VERSION ""

NS_ :

BS_:
BU_: RLR_L RRR_L mADC

BO_ 924 RRR_L_39C: 64 RRR_L
 SG_ RLR_CRCCheck_39C : 503|16@0+ (1.0000000000,0.0000000000) [0.0000000000|65535.0000000000] ""  RLR_L,mADC
 SG_ RLR_RollingCounter_39C : 491|4@0+ (1.0000000000,0.0000000000) [0.0000000000|15.0000000000] ""  RLR_L,mADC
 SG_ RLR_FreespaceSectorKinestate102 : 477|2@0+ (1.0000000000,0.0000000000) [0.0000000000|3.0000000000] "-"  RLR_L,mADC
 SG_ RLR_FreespaceSectorConRidence102 : 479|2@0+ (1.0000000000,0.0000000000) [0.0000000000|3.0000000000] "-"  RLR_L,mADC
 SG_ RLR_FreespaceSectorDistance102 : 457|10@0+ (0.1000000000,0.0000000000) [0.0000000000|100.0000000000] "-"  RLR_L,mADC
 SG_ RLR_FreespaceSectorKinestate101 : 459|2@0+ (1.0000000000,0.0000000000) [0.0000000000|3.0000000000] "-"  RLR_L,mADC
 SG_ RLR_FreespaceSectorConRidence101 : 461|2@0+ (1.0000000000,0.0000000000) [0.0000000000|3.0000000000] "-"  RLR_L,mADC
 SG_ RLR_FreespaceSectorDistance101 : 455|10@0+ (0.1000000000,0.0000000000) [0.0000000000|100.0000000000] "-"  RLR_L,mADC
 SG_ RLR_FreespaceSectorKinestate100 : 441|2@0+ (1.0000000000,0.0000000000) [0.0000000000|3.0000000000] "-"  RLR_L,mADC
 SG_ RLR_FreespaceSectorConRidence100 : 443|2@0+ (1.0000000000,0.0000000000) [0.0000000000|3.0000000000] "-"  RLR_L,mADC
 SG_ RLR_FreespaceSectorDistance100 : 437|10@0+ (0.1000000000,0.0000000000) [0.0000000000|100.0000000000] "-"  RLR_L,mADC
 SG_ RLR_FreespaceSectorKinestate99 : 439|2@0+ (1.0000000000,0.0000000000) [0.0000000000|3.0000000000] "-"  RLR_L,mADC
 SG_ RLR_FreespaceSectorConRidence99 : 425|2@0+ (1.0000000000,0.0000000000) [0.0000000000|3.0000000000] "-"  RLR_L,mADC
 SG_ RLR_FreespaceSectorDistance99 : 419|10@0+ (0.1000000000,0.0000000000) [0.0000000000|100.0000000000] "-"  RLR_L,mADC
 SG_ RLR_FreespaceSectorKinestate98 : 421|2@0+ (1.0000000000,0.0000000000) [0.0000000000|3.0000000000] "-"  RLR_L,mADC
 SG_ RLR_FreespaceSectorConRidence98 : 423|2@0+ (1.0000000000,0.0000000000) [0.0000000000|3.0000000000] "-"  RLR_L,mADC
 SG_ RLR_FreespaceSectorDistance98 : 401|10@0+ (0.1000000000,0.0000000000) [0.0000000000|100.0000000000] "-"  RLR_L,mADC
 SG_ RLR_FreespaceSectorKinestate97 : 403|2@0+ (1.0000000000,0.0000000000) [0.0000000000|3.0000000000] "-"  RLR_L,mADC
 SG_ RLR_FreespaceSectorConRidence97 : 405|2@0+ (1.0000000000,0.0000000000) [0.0000000000|3.0000000000] "-"  RLR_L,mADC
 SG_ RLR_FreespaceSectorDistance97 : 399|10@0+ (0.1000000000,0.0000000000) [0.0000000000|100.0000000000] "-"  RLR_L,mADC
 SG_ RLR_FreespaceSectorKinestate96 : 385|2@0+ (1.0000000000,0.0000000000) [0.0000000000|3.0000000000] "-"  RLR_L,mADC
 SG_ RLR_FreespaceSectorConRidence96 : 387|2@0+ (1.0000000000,0.0000000000) [0.0000000000|3.0000000000] "-"  RLR_L,mADC
 SG_ RLR_FreespaceSectorDistance96 : 381|10@0+ (0.1000000000,0.0000000000) [0.0000000000|100.0000000000] "-"  RLR_L,mADC
 SG_ RLR_FreespaceSectorKinestate95 : 383|2@0+ (1.0000000000,0.0000000000) [0.0000000000|3.0000000000] "-"  RLR_L,mADC
 SG_ RLR_FreespaceSectorConRidence95 : 369|2@0+ (1.0000000000,0.0000000000) [0.0000000000|3.0000000000] "-"  RLR_L,mADC
 SG_ RLR_FreespaceSectorDistance95 : 363|10@0+ (0.1000000000,0.0000000000) [0.0000000000|100.0000000000] "-"  RLR_L,mADC
 SG_ RLR_FreespaceSectorKinestate94 : 365|2@0+ (1.0000000000,0.0000000000) [0.0000000000|3.0000000000] "-"  RLR_L,mADC
 SG_ RLR_FreespaceSectorConRidence94 : 367|2@0+ (1.0000000000,0.0000000000) [0.0000000000|3.0000000000] "-"  RLR_L,mADC
 SG_ RLR_FreespaceSectorDistance94 : 345|10@0+ (0.1000000000,0.0000000000) [0.0000000000|100.0000000000] "-"  RLR_L,mADC
 SG_ RLR_FreespaceSectorKinestate93 : 347|2@0+ (1.0000000000,0.0000000000) [0.0000000000|3.0000000000] "-"  RLR_L,mADC
 SG_ RLR_FreespaceSectorConRidence93 : 349|2@0+ (1.0000000000,0.0000000000) [0.0000000000|3.0000000000] "-"  RLR_L,mADC
 SG_ RLR_FreespaceSectorDistance93 : 343|10@0+ (0.1000000000,0.0000000000) [0.0000000000|100.0000000000] "-"  RLR_L,mADC
 SG_ RLR_FreespaceSectorKinestate92 : 329|2@0+ (1.0000000000,0.0000000000) [0.0000000000|3.0000000000] "-"  RLR_L,mADC
 SG_ RLR_FreespaceSectorConRidence92 : 331|2@0+ (1.0000000000,0.0000000000) [0.0000000000|3.0000000000] "-"  RLR_L,mADC
 SG_ RLR_FreespaceSectorDistance92 : 325|10@0+ (0.1000000000,0.0000000000) [0.0000000000|100.0000000000] "-"  RLR_L,mADC
 SG_ RLR_FreespaceSectorKinestate91 : 327|2@0+ (1.0000000000,0.0000000000) [0.0000000000|3.0000000000] "-"  RLR_L,mADC
 SG_ RLR_FreespaceSectorConRidence91 : 313|2@0+ (1.0000000000,0.0000000000) [0.0000000000|3.0000000000] "-"  RLR_L,mADC
 SG_ RLR_FreespaceSectorDistance91 : 307|10@0+ (0.1000000000,0.0000000000) [0.0000000000|100.0000000000] "-"  RLR_L,mADC
 SG_ RLR_FreespaceSectorKinestate90 : 309|2@0+ (1.0000000000,0.0000000000) [0.0000000000|3.0000000000] "-"  RLR_L,mADC
 SG_ RLR_FreespaceSectorConRidence90 : 311|2@0+ (1.0000000000,0.0000000000) [0.0000000000|3.0000000000] "-"  RLR_L,mADC
 SG_ RLR_FreespaceSectorDistance90 : 289|10@0+ (0.1000000000,0.0000000000) [0.0000000000|100.0000000000] "-"  RLR_L,mADC
 SG_ RLR_FreespaceSectorKinestate89 : 291|2@0+ (1.0000000000,0.0000000000) [0.0000000000|3.0000000000] "-"  RLR_L,mADC
 SG_ RLR_FreespaceSectorConRidence89 : 293|2@0+ (1.0000000000,0.0000000000) [0.0000000000|3.0000000000] "-"  RLR_L,mADC
 SG_ RLR_FreespaceSectorDistance89 : 287|10@0+ (0.1000000000,0.0000000000) [0.0000000000|100.0000000000] "-"  RLR_L,mADC
 SG_ RLR_FreespaceSectorKinestate88 : 273|2@0+ (1.0000000000,0.0000000000) [0.0000000000|3.0000000000] "-"  RLR_L,mADC
 SG_ RLR_FreespaceSectorConRidence88 : 275|2@0+ (1.0000000000,0.0000000000) [0.0000000000|3.0000000000] "-"  RLR_L,mADC
 SG_ RLR_FreespaceSectorDistance88 : 269|10@0+ (0.1000000000,0.0000000000) [0.0000000000|100.0000000000] "-"  RLR_L,mADC
 SG_ RLR_FreespaceSectorKinestate87 : 271|2@0+ (1.0000000000,0.0000000000) [0.0000000000|3.0000000000] "-"  RLR_L,mADC
 SG_ RLR_FreespaceSectorConRidence87 : 257|2@0+ (1.0000000000,0.0000000000) [0.0000000000|3.0000000000] "-"  RLR_L,mADC
 SG_ RLR_FreespaceSectorDistance87 : 251|10@0+ (0.1000000000,0.0000000000) [0.0000000000|100.0000000000] "-"  RLR_L,mADC
 SG_ RLR_FreespaceSectorKinestate86 : 253|2@0+ (1.0000000000,0.0000000000) [0.0000000000|3.0000000000] "-"  RLR_L,mADC
 SG_ RLR_FreespaceSectorConRidence86 : 255|2@0+ (1.0000000000,0.0000000000) [0.0000000000|3.0000000000] "-"  RLR_L,mADC
 SG_ RLR_FreespaceSectorDistance86 : 233|10@0+ (0.1000000000,0.0000000000) [0.0000000000|100.0000000000] "-"  RLR_L,mADC
 SG_ RLR_FreespaceSectorKinestate85 : 235|2@0+ (1.0000000000,0.0000000000) [0.0000000000|3.0000000000] "-"  RLR_L,mADC
 SG_ RLR_FreespaceSectorConRidence85 : 237|2@0+ (1.0000000000,0.0000000000) [0.0000000000|3.0000000000] "-"  RLR_L,mADC
 SG_ RLR_FreespaceSectorDistance85 : 231|10@0+ (0.1000000000,0.0000000000) [0.0000000000|100.0000000000] "-"  RLR_L,mADC
 SG_ RLR_FreespaceSectorKinestate84 : 217|2@0+ (1.0000000000,0.0000000000) [0.0000000000|3.0000000000] "-"  RLR_L,mADC
 SG_ RLR_FreespaceSectorConRidence84 : 219|2@0+ (1.0000000000,0.0000000000) [0.0000000000|3.0000000000] "-"  RLR_L,mADC
 SG_ RLR_FreespaceSectorDistance84 : 213|10@0+ (0.1000000000,0.0000000000) [0.0000000000|100.0000000000] "-"  RLR_L,mADC
 SG_ RLR_FreespaceSectorKinestate83 : 215|2@0+ (1.0000000000,0.0000000000) [0.0000000000|3.0000000000] "-"  RLR_L,mADC
 SG_ RLR_FreespaceSectorConRidence83 : 201|2@0+ (1.0000000000,0.0000000000) [0.0000000000|3.0000000000] "-"  RLR_L,mADC
 SG_ RLR_FreespaceSectorDistance83 : 195|10@0+ (0.1000000000,0.0000000000) [0.0000000000|100.0000000000] "-"  RLR_L,mADC
 SG_ RLR_FreespaceSectorKinestate82 : 197|2@0+ (1.0000000000,0.0000000000) [0.0000000000|3.0000000000] "-"  RLR_L,mADC
 SG_ RLR_FreespaceSectorConRidence82 : 199|2@0+ (1.0000000000,0.0000000000) [0.0000000000|3.0000000000] "-"  RLR_L,mADC
 SG_ RLR_FreespaceSectorDistance82 : 177|10@0+ (0.1000000000,0.0000000000) [0.0000000000|100.0000000000] "-"  RLR_L,mADC
 SG_ RLR_FreespaceSectorKinestate81 : 179|2@0+ (1.0000000000,0.0000000000) [0.0000000000|3.0000000000] "-"  RLR_L,mADC
 SG_ RLR_FreespaceSectorConRidence81 : 181|2@0+ (1.0000000000,0.0000000000) [0.0000000000|3.0000000000] "-"  RLR_L,mADC
 SG_ RLR_FreespaceSectorDistance81 : 175|10@0+ (0.1000000000,0.0000000000) [0.0000000000|100.0000000000] "-"  RLR_L,mADC
 SG_ RLR_FreespaceSectorKinestate80 : 161|2@0+ (1.0000000000,0.0000000000) [0.0000000000|3.0000000000] "-"  RLR_L,mADC
 SG_ RLR_FreespaceSectorConRidence80 : 163|2@0+ (1.0000000000,0.0000000000) [0.0000000000|3.0000000000] "-"  RLR_L,mADC
 SG_ RLR_FreespaceSectorDistance80 : 157|10@0+ (0.1000000000,0.0000000000) [0.0000000000|100.0000000000] "-"  RLR_L,mADC
 SG_ RLR_FreespaceSectorKinestate79 : 159|2@0+ (1.0000000000,0.0000000000) [0.0000000000|3.0000000000] "-"  RLR_L,mADC
 SG_ RLR_FreespaceSectorConRidence79 : 145|2@0+ (1.0000000000,0.0000000000) [0.0000000000|3.0000000000] "-"  RLR_L,mADC
 SG_ RLR_FreespaceSectorDistance79 : 139|10@0+ (0.1000000000,0.0000000000) [0.0000000000|100.0000000000] "-"  RLR_L,mADC
 SG_ RLR_FreespaceSectorKinestate78 : 141|2@0+ (1.0000000000,0.0000000000) [0.0000000000|3.0000000000] "-"  RLR_L,mADC
 SG_ RLR_FreespaceSectorConRidence78 : 143|2@0+ (1.0000000000,0.0000000000) [0.0000000000|3.0000000000] "-"  RLR_L,mADC
 SG_ RLR_FreespaceSectorDistance78 : 121|10@0+ (0.1000000000,0.0000000000) [0.0000000000|100.0000000000] "-"  RLR_L,mADC
 SG_ RLR_FreespaceSectorKinestate77 : 123|2@0+ (1.0000000000,0.0000000000) [0.0000000000|3.0000000000] "-"  RLR_L,mADC
 SG_ RLR_FreespaceSectorConRidence77 : 125|2@0+ (1.0000000000,0.0000000000) [0.0000000000|3.0000000000] "-"  RLR_L,mADC
 SG_ RLR_FreespaceSectorDistance77 : 119|10@0+ (0.1000000000,0.0000000000) [0.0000000000|100.0000000000] "-"  RLR_L,mADC
 SG_ RLR_FreespaceSectorKinestate76 : 105|2@0+ (1.0000000000,0.0000000000) [0.0000000000|3.0000000000] "-"  RLR_L,mADC
 SG_ RLR_FreespaceSectorConRidence76 : 107|2@0+ (1.0000000000,0.0000000000) [0.0000000000|3.0000000000] "-"  RLR_L,mADC
 SG_ RLR_FreespaceSectorDistance76 : 101|10@0+ (0.1000000000,0.0000000000) [0.0000000000|100.0000000000] "-"  RLR_L,mADC
 SG_ RLR_FreespaceSectorKinestate75 : 103|2@0+ (1.0000000000,0.0000000000) [0.0000000000|3.0000000000] "-"  RLR_L,mADC
 SG_ RLR_FreespaceSectorConRidence75 : 89|2@0+ (1.0000000000,0.0000000000) [0.0000000000|3.0000000000] "-"  RLR_L,mADC
 SG_ RLR_FreespaceSectorDistance75 : 83|10@0+ (0.1000000000,0.0000000000) [0.0000000000|100.0000000000] "-"  RLR_L,mADC
 SG_ RLR_FreespaceSectorKinestate74 : 85|2@0+ (1.0000000000,0.0000000000) [0.0000000000|3.0000000000] "-"  RLR_L,mADC
 SG_ RLR_FreespaceSectorConRidence74 : 87|2@0+ (1.0000000000,0.0000000000) [0.0000000000|3.0000000000] "-"  RLR_L,mADC
 SG_ RLR_FreespaceSectorDistance74 : 65|10@0+ (0.1000000000,0.0000000000) [0.0000000000|100.0000000000] "-"  RLR_L,mADC
 SG_ RLR_FreespaceSectorKinestate73 : 67|2@0+ (1.0000000000,0.0000000000) [0.0000000000|3.0000000000] "-"  RLR_L,mADC
 SG_ RLR_FreespaceSectorConRidence73 : 69|2@0+ (1.0000000000,0.0000000000) [0.0000000000|3.0000000000] "-"  RLR_L,mADC
 SG_ RLR_FreespaceSectorDistance73 : 63|10@0+ (0.1000000000,0.0000000000) [0.0000000000|100.0000000000] "-"  RLR_L,mADC
 SG_ RLR_FreespaceSectorKinestate72 : 49|2@0+ (1.0000000000,0.0000000000) [0.0000000000|3.0000000000] "-"  RLR_L,mADC
 SG_ RLR_FreespaceSectorConRidence72 : 51|2@0+ (1.0000000000,0.0000000000) [0.0000000000|3.0000000000] "-"  RLR_L,mADC
 SG_ RLR_FreespaceSectorDistance72 : 45|10@0+ (0.1000000000,0.0000000000) [0.0000000000|100.0000000000] "-"  RLR_L,mADC
 SG_ RLR_FreespaceSectorKinestate71 : 47|2@0+ (1.0000000000,0.0000000000) [0.0000000000|3.0000000000] "-"  RLR_L,mADC
 SG_ RLR_FreespaceSectorConRidence71 : 33|2@0+ (1.0000000000,0.0000000000) [0.0000000000|3.0000000000] "-"  RLR_L,mADC
 SG_ RLR_FreespaceSectorDistance71 : 27|10@0+ (0.1000000000,0.0000000000) [0.0000000000|100.0000000000] "-"  RLR_L,mADC
 SG_ RLR_FreespaceSectorKinestate70 : 29|2@0+ (1.0000000000,0.0000000000) [0.0000000000|3.0000000000] "-"  RLR_L,mADC
 SG_ RLR_FreespaceSectorConRidence70 : 31|2@0+ (1.0000000000,0.0000000000) [0.0000000000|3.0000000000] "-"  RLR_L,mADC
 SG_ RLR_FreespaceSectorDistance70 : 9|10@0+ (0.1000000000,0.0000000000) [0.0000000000|100.0000000000] "-"  RLR_L,mADC
 SG_ RLR_FreespaceSectorKinestate69 : 11|2@0+ (1.0000000000,0.0000000000) [0.0000000000|3.0000000000] "-"  RLR_L,mADC
 SG_ RLR_FreespaceSectorConRidence69 : 13|2@0+ (1.0000000000,0.0000000000) [0.0000000000|3.0000000000] "-"  RLR_L,mADC
 SG_ RLR_FreespaceSectorDistance69 : 7|10@0+ (0.1000000000,0.0000000000) [0.0000000000|100.0000000000] "-"  RLR_L,mADC

BO_ 925 RRR_L_39D: 64 RRR_L
 SG_ RLR_CRCCheck_39D : 503|16@0+ (1.0000000000,0.0000000000) [0.0000000000|65535.0000000000] ""  RLR_L,mADC
 SG_ RLR_RollingCounter_39D : 491|4@0+ (1.0000000000,0.0000000000) [0.0000000000|15.0000000000] ""  RLR_L,mADC
 SG_ RLR_FreespaceSectorKinestate136 : 477|2@0+ (1.0000000000,0.0000000000) [0.0000000000|3.0000000000] "-"  RLR_L,mADC
 SG_ RLR_FreespaceSectorConRidence136 : 479|2@0+ (1.0000000000,0.0000000000) [0.0000000000|3.0000000000] "-"  RLR_L,mADC
 SG_ RLR_FreespaceSectorDistance136 : 457|10@0+ (0.1000000000,0.0000000000) [0.0000000000|100.0000000000] "-"  RLR_L,mADC
 SG_ RLR_FreespaceSectorKinestate135 : 459|2@0+ (1.0000000000,0.0000000000) [0.0000000000|3.0000000000] "-"  RLR_L,mADC
 SG_ RLR_FreespaceSectorConRidence135 : 461|2@0+ (1.0000000000,0.0000000000) [0.0000000000|3.0000000000] "-"  RLR_L,mADC
 SG_ RLR_FreespaceSectorDistance135 : 455|10@0+ (0.1000000000,0.0000000000) [0.0000000000|100.0000000000] "-"  RLR_L,mADC
 SG_ RLR_FreespaceSectorKinestate134 : 441|2@0+ (1.0000000000,0.0000000000) [0.0000000000|3.0000000000] "-"  RLR_L,mADC
 SG_ RLR_FreespaceSectorConRidence134 : 443|2@0+ (1.0000000000,0.0000000000) [0.0000000000|3.0000000000] "-"  RLR_L,mADC
 SG_ RLR_FreespaceSectorDistance134 : 437|10@0+ (0.1000000000,0.0000000000) [0.0000000000|100.0000000000] "-"  RLR_L,mADC
 SG_ RLR_FreespaceSectorKinestate133 : 439|2@0+ (1.0000000000,0.0000000000) [0.0000000000|3.0000000000] "-"  RLR_L,mADC
 SG_ RLR_FreespaceSectorConRidence133 : 425|2@0+ (1.0000000000,0.0000000000) [0.0000000000|3.0000000000] "-"  RLR_L,mADC
 SG_ RLR_FreespaceSectorDistance133 : 419|10@0+ (0.1000000000,0.0000000000) [0.0000000000|100.0000000000] "-"  RLR_L,mADC
 SG_ RLR_FreespaceSectorKinestate132 : 421|2@0+ (1.0000000000,0.0000000000) [0.0000000000|3.0000000000] "-"  RLR_L,mADC
 SG_ RLR_FreespaceSectorConRidence132 : 423|2@0+ (1.0000000000,0.0000000000) [0.0000000000|3.0000000000] "-"  RLR_L,mADC
 SG_ RLR_FreespaceSectorDistance132 : 401|10@0+ (0.1000000000,0.0000000000) [0.0000000000|100.0000000000] "-"  RLR_L,mADC
 SG_ RLR_FreespaceSectorKinestate131 : 403|2@0+ (1.0000000000,0.0000000000) [0.0000000000|3.0000000000] "-"  RLR_L,mADC
 SG_ RLR_FreespaceSectorConRidence131 : 405|2@0+ (1.0000000000,0.0000000000) [0.0000000000|3.0000000000] "-"  RLR_L,mADC
 SG_ RLR_FreespaceSectorDistance131 : 399|10@0+ (0.1000000000,0.0000000000) [0.0000000000|100.0000000000] "-"  RLR_L,mADC
 SG_ RLR_FreespaceSectorKinestate130 : 385|2@0+ (1.0000000000,0.0000000000) [0.0000000000|3.0000000000] "-"  RLR_L,mADC
 SG_ RLR_FreespaceSectorConRidence130 : 387|2@0+ (1.0000000000,0.0000000000) [0.0000000000|3.0000000000] "-"  RLR_L,mADC
 SG_ RLR_FreespaceSectorDistance130 : 381|10@0+ (0.1000000000,0.0000000000) [0.0000000000|100.0000000000] "-"  RLR_L,mADC
 SG_ RLR_FreespaceSectorKinestate129 : 383|2@0+ (1.0000000000,0.0000000000) [0.0000000000|3.0000000000] "-"  RLR_L,mADC
 SG_ RLR_FreespaceSectorConRidence129 : 369|2@0+ (1.0000000000,0.0000000000) [0.0000000000|3.0000000000] "-"  RLR_L,mADC
 SG_ RLR_FreespaceSectorDistance129 : 363|10@0+ (0.1000000000,0.0000000000) [0.0000000000|100.0000000000] "-"  RLR_L,mADC
 SG_ RLR_FreespaceSectorKinestate128 : 365|2@0+ (1.0000000000,0.0000000000) [0.0000000000|3.0000000000] "-"  RLR_L,mADC
 SG_ RLR_FreespaceSectorConRidence128 : 367|2@0+ (1.0000000000,0.0000000000) [0.0000000000|3.0000000000] "-"  RLR_L,mADC
 SG_ RLR_FreespaceSectorDistance128 : 345|10@0+ (0.1000000000,0.0000000000) [0.0000000000|100.0000000000] "-"  RLR_L,mADC
 SG_ RLR_FreespaceSectorKinestate127 : 347|2@0+ (1.0000000000,0.0000000000) [0.0000000000|3.0000000000] "-"  RLR_L,mADC
 SG_ RLR_FreespaceSectorConRidence127 : 349|2@0+ (1.0000000000,0.0000000000) [0.0000000000|3.0000000000] "-"  RLR_L,mADC
 SG_ RLR_FreespaceSectorDistance127 : 343|10@0+ (0.1000000000,0.0000000000) [0.0000000000|100.0000000000] "-"  RLR_L,mADC
 SG_ RLR_FreespaceSectorKinestate126 : 329|2@0+ (1.0000000000,0.0000000000) [0.0000000000|3.0000000000] "-"  RLR_L,mADC
 SG_ RLR_FreespaceSectorConRidence126 : 331|2@0+ (1.0000000000,0.0000000000) [0.0000000000|3.0000000000] "-"  RLR_L,mADC
 SG_ RLR_FreespaceSectorDistance126 : 325|10@0+ (0.1000000000,0.0000000000) [0.0000000000|100.0000000000] "-"  RLR_L,mADC
 SG_ RLR_FreespaceSectorKinestate125 : 327|2@0+ (1.0000000000,0.0000000000) [0.0000000000|3.0000000000] "-"  RLR_L,mADC
 SG_ RLR_FreespaceSectorConRidence125 : 313|2@0+ (1.0000000000,0.0000000000) [0.0000000000|3.0000000000] "-"  RLR_L,mADC
 SG_ RLR_FreespaceSectorDistance125 : 307|10@0+ (0.1000000000,0.0000000000) [0.0000000000|100.0000000000] "-"  RLR_L,mADC
 SG_ RLR_FreespaceSectorKinestate124 : 309|2@0+ (1.0000000000,0.0000000000) [0.0000000000|3.0000000000] "-"  RLR_L,mADC
 SG_ RLR_FreespaceSectorConRidence124 : 311|2@0+ (1.0000000000,0.0000000000) [0.0000000000|3.0000000000] "-"  RLR_L,mADC
 SG_ RLR_FreespaceSectorDistance124 : 289|10@0+ (0.1000000000,0.0000000000) [0.0000000000|100.0000000000] "-"  RLR_L,mADC
 SG_ RLR_FreespaceSectorKinestate123 : 291|2@0+ (1.0000000000,0.0000000000) [0.0000000000|3.0000000000] "-"  RLR_L,mADC
 SG_ RLR_FreespaceSectorConRidence123 : 293|2@0+ (1.0000000000,0.0000000000) [0.0000000000|3.0000000000] "-"  RLR_L,mADC
 SG_ RLR_FreespaceSectorDistance123 : 287|10@0+ (0.1000000000,0.0000000000) [0.0000000000|100.0000000000] "-"  RLR_L,mADC
 SG_ RLR_FreespaceSectorKinestate122 : 273|2@0+ (1.0000000000,0.0000000000) [0.0000000000|3.0000000000] "-"  RLR_L,mADC
 SG_ RLR_FreespaceSectorConRidence122 : 275|2@0+ (1.0000000000,0.0000000000) [0.0000000000|3.0000000000] "-"  RLR_L,mADC
 SG_ RLR_FreespaceSectorDistance122 : 269|10@0+ (0.1000000000,0.0000000000) [0.0000000000|100.0000000000] "-"  RLR_L,mADC
 SG_ RLR_FreespaceSectorKinestate121 : 271|2@0+ (1.0000000000,0.0000000000) [0.0000000000|3.0000000000] "-"  RLR_L,mADC
 SG_ RLR_FreespaceSectorConRidence121 : 257|2@0+ (1.0000000000,0.0000000000) [0.0000000000|3.0000000000] "-"  RLR_L,mADC
 SG_ RLR_FreespaceSectorDistance121 : 251|10@0+ (0.1000000000,0.0000000000) [0.0000000000|100.0000000000] "-"  RLR_L,mADC
 SG_ RLR_FreespaceSectorKinestate120 : 253|2@0+ (1.0000000000,0.0000000000) [0.0000000000|3.0000000000] "-"  RLR_L,mADC
 SG_ RLR_FreespaceSectorConRidence120 : 255|2@0+ (1.0000000000,0.0000000000) [0.0000000000|3.0000000000] "-"  RLR_L,mADC
 SG_ RLR_FreespaceSectorDistance120 : 233|10@0+ (0.1000000000,0.0000000000) [0.0000000000|100.0000000000] "-"  RLR_L,mADC
 SG_ RLR_FreespaceSectorKinestate119 : 235|2@0+ (1.0000000000,0.0000000000) [0.0000000000|3.0000000000] "-"  RLR_L,mADC
 SG_ RLR_FreespaceSectorConRidence119 : 237|2@0+ (1.0000000000,0.0000000000) [0.0000000000|3.0000000000] "-"  RLR_L,mADC
 SG_ RLR_FreespaceSectorDistance119 : 231|10@0+ (0.1000000000,0.0000000000) [0.0000000000|100.0000000000] "-"  RLR_L,mADC
 SG_ RLR_FreespaceSectorKinestate118 : 217|2@0+ (1.0000000000,0.0000000000) [0.0000000000|3.0000000000] "-"  RLR_L,mADC
 SG_ RLR_FreespaceSectorConRidence118 : 219|2@0+ (1.0000000000,0.0000000000) [0.0000000000|3.0000000000] "-"  RLR_L,mADC
 SG_ RLR_FreespaceSectorDistance118 : 213|10@0+ (0.1000000000,0.0000000000) [0.0000000000|100.0000000000] "-"  RLR_L,mADC
 SG_ RLR_FreespaceSectorKinestate117 : 215|2@0+ (1.0000000000,0.0000000000) [0.0000000000|3.0000000000] "-"  RLR_L,mADC
 SG_ RLR_FreespaceSectorConRidence117 : 201|2@0+ (1.0000000000,0.0000000000) [0.0000000000|3.0000000000] "-"  RLR_L,mADC
 SG_ RLR_FreespaceSectorDistance117 : 195|10@0+ (0.1000000000,0.0000000000) [0.0000000000|100.0000000000] "-"  RLR_L,mADC
 SG_ RLR_FreespaceSectorKinestate116 : 197|2@0+ (1.0000000000,0.0000000000) [0.0000000000|3.0000000000] "-"  RLR_L,mADC
 SG_ RLR_FreespaceSectorConRidence116 : 199|2@0+ (1.0000000000,0.0000000000) [0.0000000000|3.0000000000] "-"  RLR_L,mADC
 SG_ RLR_FreespaceSectorDistance116 : 177|10@0+ (0.1000000000,0.0000000000) [0.0000000000|100.0000000000] "-"  RLR_L,mADC
 SG_ RLR_FreespaceSectorKinestate115 : 179|2@0+ (1.0000000000,0.0000000000) [0.0000000000|3.0000000000] "-"  RLR_L,mADC
 SG_ RLR_FreespaceSectorConRidence115 : 181|2@0+ (1.0000000000,0.0000000000) [0.0000000000|3.0000000000] "-"  RLR_L,mADC
 SG_ RLR_FreespaceSectorDistance115 : 175|10@0+ (0.1000000000,0.0000000000) [0.0000000000|100.0000000000] "-"  RLR_L,mADC
 SG_ RLR_FreespaceSectorKinestate114 : 161|2@0+ (1.0000000000,0.0000000000) [0.0000000000|3.0000000000] "-"  RLR_L,mADC
 SG_ RLR_FreespaceSectorConRidence114 : 163|2@0+ (1.0000000000,0.0000000000) [0.0000000000|3.0000000000] "-"  RLR_L,mADC
 SG_ RLR_FreespaceSectorDistance114 : 157|10@0+ (0.1000000000,0.0000000000) [0.0000000000|100.0000000000] "-"  RLR_L,mADC
 SG_ RLR_FreespaceSectorKinestate113 : 159|2@0+ (1.0000000000,0.0000000000) [0.0000000000|3.0000000000] "-"  RLR_L,mADC
 SG_ RLR_FreespaceSectorConRidence113 : 145|2@0+ (1.0000000000,0.0000000000) [0.0000000000|3.0000000000] "-"  RLR_L,mADC
 SG_ RLR_FreespaceSectorDistance113 : 139|10@0+ (0.1000000000,0.0000000000) [0.0000000000|100.0000000000] "-"  RLR_L,mADC
 SG_ RLR_FreespaceSectorKinestate112 : 141|2@0+ (1.0000000000,0.0000000000) [0.0000000000|3.0000000000] "-"  RLR_L,mADC
 SG_ RLR_FreespaceSectorConRidence112 : 143|2@0+ (1.0000000000,0.0000000000) [0.0000000000|3.0000000000] "-"  RLR_L,mADC
 SG_ RLR_FreespaceSectorDistance112 : 121|10@0+ (0.1000000000,0.0000000000) [0.0000000000|100.0000000000] "-"  RLR_L,mADC
 SG_ RLR_FreespaceSectorKinestate111 : 123|2@0+ (1.0000000000,0.0000000000) [0.0000000000|3.0000000000] "-"  RLR_L,mADC
 SG_ RLR_FreespaceSectorConRidence111 : 125|2@0+ (1.0000000000,0.0000000000) [0.0000000000|3.0000000000] "-"  RLR_L,mADC
 SG_ RLR_FreespaceSectorDistance111 : 119|10@0+ (0.1000000000,0.0000000000) [0.0000000000|100.0000000000] "-"  RLR_L,mADC
 SG_ RLR_FreespaceSectorKinestate110 : 105|2@0+ (1.0000000000,0.0000000000) [0.0000000000|3.0000000000] "-"  RLR_L,mADC
 SG_ RLR_FreespaceSectorConRidence110 : 107|2@0+ (1.0000000000,0.0000000000) [0.0000000000|3.0000000000] "-"  RLR_L,mADC
 SG_ RLR_FreespaceSectorDistance110 : 101|10@0+ (0.1000000000,0.0000000000) [0.0000000000|100.0000000000] "-"  RLR_L,mADC
 SG_ RLR_FreespaceSectorKinestate109 : 103|2@0+ (1.0000000000,0.0000000000) [0.0000000000|3.0000000000] "-"  RLR_L,mADC
 SG_ RLR_FreespaceSectorConRidence109 : 89|2@0+ (1.0000000000,0.0000000000) [0.0000000000|3.0000000000] "-"  RLR_L,mADC
 SG_ RLR_FreespaceSectorDistance109 : 83|10@0+ (0.1000000000,0.0000000000) [0.0000000000|100.0000000000] "-"  RLR_L,mADC
 SG_ RLR_FreespaceSectorKinestate108 : 85|2@0+ (1.0000000000,0.0000000000) [0.0000000000|3.0000000000] "-"  RLR_L,mADC
 SG_ RLR_FreespaceSectorConRidence108 : 87|2@0+ (1.0000000000,0.0000000000) [0.0000000000|3.0000000000] "-"  RLR_L,mADC
 SG_ RLR_FreespaceSectorDistance108 : 65|10@0+ (0.1000000000,0.0000000000) [0.0000000000|100.0000000000] "-"  RLR_L,mADC
 SG_ RLR_FreespaceSectorKinestate107 : 67|2@0+ (1.0000000000,0.0000000000) [0.0000000000|3.0000000000] "-"  RLR_L,mADC
 SG_ RLR_FreespaceSectorConRidence107 : 69|2@0+ (1.0000000000,0.0000000000) [0.0000000000|3.0000000000] "-"  RLR_L,mADC
 SG_ RLR_FreespaceSectorDistance107 : 63|10@0+ (0.1000000000,0.0000000000) [0.0000000000|100.0000000000] "-"  RLR_L,mADC
 SG_ RLR_FreespaceSectorKinestate106 : 49|2@0+ (1.0000000000,0.0000000000) [0.0000000000|3.0000000000] "-"  RLR_L,mADC
 SG_ RLR_FreespaceSectorConRidence106 : 51|2@0+ (1.0000000000,0.0000000000) [0.0000000000|3.0000000000] "-"  RLR_L,mADC
 SG_ RLR_FreespaceSectorDistance106 : 45|10@0+ (0.1000000000,0.0000000000) [0.0000000000|100.0000000000] "-"  RLR_L,mADC
 SG_ RLR_FreespaceSectorKinestate105 : 47|2@0+ (1.0000000000,0.0000000000) [0.0000000000|3.0000000000] "-"  RLR_L,mADC
 SG_ RLR_FreespaceSectorConRidence105 : 33|2@0+ (1.0000000000,0.0000000000) [0.0000000000|3.0000000000] "-"  RLR_L,mADC
 SG_ RLR_FreespaceSectorDistance105 : 27|10@0+ (0.1000000000,0.0000000000) [0.0000000000|100.0000000000] "-"  RLR_L,mADC
 SG_ RLR_FreespaceSectorKinestate104 : 29|2@0+ (1.0000000000,0.0000000000) [0.0000000000|3.0000000000] "-"  RLR_L,mADC
 SG_ RLR_FreespaceSectorConRidence104 : 31|2@0+ (1.0000000000,0.0000000000) [0.0000000000|3.0000000000] "-"  RLR_L,mADC
 SG_ RLR_FreespaceSectorDistance104 : 9|10@0+ (0.1000000000,0.0000000000) [0.0000000000|100.0000000000] "-"  RLR_L,mADC
 SG_ RLR_FreespaceSectorKinestate103 : 11|2@0+ (1.0000000000,0.0000000000) [0.0000000000|3.0000000000] "-"  RLR_L,mADC
 SG_ RLR_FreespaceSectorConRidence103 : 13|2@0+ (1.0000000000,0.0000000000) [0.0000000000|3.0000000000] "-"  RLR_L,mADC
 SG_ RLR_FreespaceSectorDistance103 : 7|10@0+ (0.1000000000,0.0000000000) [0.0000000000|100.0000000000] "-"  RLR_L,mADC

BO_ 926 RRR_L_39E: 64 RRR_L
 SG_ RLR_CRCCheck_39E : 503|16@0+ (1.0000000000,0.0000000000) [0.0000000000|65535.0000000000] ""  RLR_L,mADC
 SG_ RLR_RollingCounter_39E : 491|4@0+ (1.0000000000,0.0000000000) [0.0000000000|15.0000000000] ""  RLR_L,mADC
 SG_ RLR_FreespaceSectorKinestate170 : 477|2@0+ (1.0000000000,0.0000000000) [0.0000000000|3.0000000000] "-"  RLR_L,mADC
 SG_ RLR_FreespaceSectorConRidence170 : 479|2@0+ (1.0000000000,0.0000000000) [0.0000000000|3.0000000000] "-"  RLR_L,mADC
 SG_ RLR_FreespaceSectorDistance170 : 457|10@0+ (0.1000000000,0.0000000000) [0.0000000000|100.0000000000] "-"  RLR_L,mADC
 SG_ RLR_FreespaceSectorKinestate169 : 459|2@0+ (1.0000000000,0.0000000000) [0.0000000000|3.0000000000] "-"  RLR_L,mADC
 SG_ RLR_FreespaceSectorConRidence169 : 461|2@0+ (1.0000000000,0.0000000000) [0.0000000000|3.0000000000] "-"  RLR_L,mADC
 SG_ RLR_FreespaceSectorDistance169 : 455|10@0+ (0.1000000000,0.0000000000) [0.0000000000|100.0000000000] "-"  RLR_L,mADC
 SG_ RLR_FreespaceSectorKinestate168 : 441|2@0+ (1.0000000000,0.0000000000) [0.0000000000|3.0000000000] "-"  RLR_L,mADC
 SG_ RLR_FreespaceSectorConRidence168 : 443|2@0+ (1.0000000000,0.0000000000) [0.0000000000|3.0000000000] "-"  RLR_L,mADC
 SG_ RLR_FreespaceSectorDistance168 : 437|10@0+ (0.1000000000,0.0000000000) [0.0000000000|100.0000000000] "-"  RLR_L,mADC
 SG_ RLR_FreespaceSectorKinestate167 : 439|2@0+ (1.0000000000,0.0000000000) [0.0000000000|3.0000000000] "-"  RLR_L,mADC
 SG_ RLR_FreespaceSectorConRidence167 : 425|2@0+ (1.0000000000,0.0000000000) [0.0000000000|3.0000000000] "-"  RLR_L,mADC
 SG_ RLR_FreespaceSectorDistance167 : 419|10@0+ (0.1000000000,0.0000000000) [0.0000000000|100.0000000000] "-"  RLR_L,mADC
 SG_ RLR_FreespaceSectorKinestate166 : 421|2@0+ (1.0000000000,0.0000000000) [0.0000000000|3.0000000000] "-"  RLR_L,mADC
 SG_ RLR_FreespaceSectorConRidence166 : 423|2@0+ (1.0000000000,0.0000000000) [0.0000000000|3.0000000000] "-"  RLR_L,mADC
 SG_ RLR_FreespaceSectorDistance166 : 401|10@0+ (0.1000000000,0.0000000000) [0.0000000000|100.0000000000] "-"  RLR_L,mADC
 SG_ RLR_FreespaceSectorKinestate165 : 403|2@0+ (1.0000000000,0.0000000000) [0.0000000000|3.0000000000] "-"  RLR_L,mADC
 SG_ RLR_FreespaceSectorConRidence165 : 405|2@0+ (1.0000000000,0.0000000000) [0.0000000000|3.0000000000] "-"  RLR_L,mADC
 SG_ RLR_FreespaceSectorDistance165 : 399|10@0+ (0.1000000000,0.0000000000) [0.0000000000|100.0000000000] "-"  RLR_L,mADC
 SG_ RLR_FreespaceSectorKinestate164 : 385|2@0+ (1.0000000000,0.0000000000) [0.0000000000|3.0000000000] "-"  RLR_L,mADC
 SG_ RLR_FreespaceSectorConRidence164 : 387|2@0+ (1.0000000000,0.0000000000) [0.0000000000|3.0000000000] "-"  RLR_L,mADC
 SG_ RLR_FreespaceSectorDistance164 : 381|10@0+ (0.1000000000,0.0000000000) [0.0000000000|100.0000000000] "-"  RLR_L,mADC
 SG_ RLR_FreespaceSectorKinestate163 : 383|2@0+ (1.0000000000,0.0000000000) [0.0000000000|3.0000000000] "-"  RLR_L,mADC
 SG_ RLR_FreespaceSectorConRidence163 : 369|2@0+ (1.0000000000,0.0000000000) [0.0000000000|3.0000000000] "-"  RLR_L,mADC
 SG_ RLR_FreespaceSectorDistance163 : 363|10@0+ (0.1000000000,0.0000000000) [0.0000000000|100.0000000000] "-"  RLR_L,mADC
 SG_ RLR_FreespaceSectorKinestate162 : 365|2@0+ (1.0000000000,0.0000000000) [0.0000000000|3.0000000000] "-"  RLR_L,mADC
 SG_ RLR_FreespaceSectorConRidence162 : 367|2@0+ (1.0000000000,0.0000000000) [0.0000000000|3.0000000000] "-"  RLR_L,mADC
 SG_ RLR_FreespaceSectorDistance162 : 345|10@0+ (0.1000000000,0.0000000000) [0.0000000000|100.0000000000] "-"  RLR_L,mADC
 SG_ RLR_FreespaceSectorKinestate161 : 347|2@0+ (1.0000000000,0.0000000000) [0.0000000000|3.0000000000] "-"  RLR_L,mADC
 SG_ RLR_FreespaceSectorConRidence161 : 349|2@0+ (1.0000000000,0.0000000000) [0.0000000000|3.0000000000] "-"  RLR_L,mADC
 SG_ RLR_FreespaceSectorDistance161 : 343|10@0+ (0.1000000000,0.0000000000) [0.0000000000|100.0000000000] "-"  RLR_L,mADC
 SG_ RLR_FreespaceSectorKinestate160 : 329|2@0+ (1.0000000000,0.0000000000) [0.0000000000|3.0000000000] "-"  RLR_L,mADC
 SG_ RLR_FreespaceSectorConRidence160 : 331|2@0+ (1.0000000000,0.0000000000) [0.0000000000|3.0000000000] "-"  RLR_L,mADC
 SG_ RLR_FreespaceSectorDistance160 : 325|10@0+ (0.1000000000,0.0000000000) [0.0000000000|100.0000000000] "-"  RLR_L,mADC
 SG_ RLR_FreespaceSectorKinestate159 : 327|2@0+ (1.0000000000,0.0000000000) [0.0000000000|3.0000000000] "-"  RLR_L,mADC
 SG_ RLR_FreespaceSectorConRidence159 : 313|2@0+ (1.0000000000,0.0000000000) [0.0000000000|3.0000000000] "-"  RLR_L,mADC
 SG_ RLR_FreespaceSectorDistance159 : 307|10@0+ (0.1000000000,0.0000000000) [0.0000000000|100.0000000000] "-"  RLR_L,mADC
 SG_ RLR_FreespaceSectorKinestate158 : 309|2@0+ (1.0000000000,0.0000000000) [0.0000000000|3.0000000000] "-"  RLR_L,mADC
 SG_ RLR_FreespaceSectorConRidence158 : 311|2@0+ (1.0000000000,0.0000000000) [0.0000000000|3.0000000000] "-"  RLR_L,mADC
 SG_ RLR_FreespaceSectorDistance158 : 289|10@0+ (0.1000000000,0.0000000000) [0.0000000000|100.0000000000] "-"  RLR_L,mADC
 SG_ RLR_FreespaceSectorKinestate157 : 291|2@0+ (1.0000000000,0.0000000000) [0.0000000000|3.0000000000] "-"  RLR_L,mADC
 SG_ RLR_FreespaceSectorConRidence157 : 293|2@0+ (1.0000000000,0.0000000000) [0.0000000000|3.0000000000] "-"  RLR_L,mADC
 SG_ RLR_FreespaceSectorDistance157 : 287|10@0+ (0.1000000000,0.0000000000) [0.0000000000|100.0000000000] "-"  RLR_L,mADC
 SG_ RLR_FreespaceSectorKinestate156 : 273|2@0+ (1.0000000000,0.0000000000) [0.0000000000|3.0000000000] "-"  RLR_L,mADC
 SG_ RLR_FreespaceSectorConRidence156 : 275|2@0+ (1.0000000000,0.0000000000) [0.0000000000|3.0000000000] "-"  RLR_L,mADC
 SG_ RLR_FreespaceSectorDistance156 : 269|10@0+ (0.1000000000,0.0000000000) [0.0000000000|100.0000000000] "-"  RLR_L,mADC
 SG_ RLR_FreespaceSectorKinestate155 : 271|2@0+ (1.0000000000,0.0000000000) [0.0000000000|3.0000000000] "-"  RLR_L,mADC
 SG_ RLR_FreespaceSectorConRidence155 : 257|2@0+ (1.0000000000,0.0000000000) [0.0000000000|3.0000000000] "-"  RLR_L,mADC
 SG_ RLR_FreespaceSectorDistance155 : 251|10@0+ (0.1000000000,0.0000000000) [0.0000000000|100.0000000000] "-"  RLR_L,mADC
 SG_ RLR_FreespaceSectorKinestate154 : 253|2@0+ (1.0000000000,0.0000000000) [0.0000000000|3.0000000000] "-"  RLR_L,mADC
 SG_ RLR_FreespaceSectorConRidence154 : 255|2@0+ (1.0000000000,0.0000000000) [0.0000000000|3.0000000000] "-"  RLR_L,mADC
 SG_ RLR_FreespaceSectorDistance154 : 233|10@0+ (0.1000000000,0.0000000000) [0.0000000000|100.0000000000] "-"  RLR_L,mADC
 SG_ RLR_FreespaceSectorKinestate153 : 235|2@0+ (1.0000000000,0.0000000000) [0.0000000000|3.0000000000] "-"  RLR_L,mADC
 SG_ RLR_FreespaceSectorConRidence153 : 237|2@0+ (1.0000000000,0.0000000000) [0.0000000000|3.0000000000] "-"  RLR_L,mADC
 SG_ RLR_FreespaceSectorDistance153 : 231|10@0+ (0.1000000000,0.0000000000) [0.0000000000|100.0000000000] "-"  RLR_L,mADC
 SG_ RLR_FreespaceSectorKinestate152 : 217|2@0+ (1.0000000000,0.0000000000) [0.0000000000|3.0000000000] "-"  RLR_L,mADC
 SG_ RLR_FreespaceSectorConRidence152 : 219|2@0+ (1.0000000000,0.0000000000) [0.0000000000|3.0000000000] "-"  RLR_L,mADC
 SG_ RLR_FreespaceSectorDistance152 : 213|10@0+ (0.1000000000,0.0000000000) [0.0000000000|100.0000000000] "-"  RLR_L,mADC
 SG_ RLR_FreespaceSectorKinestate151 : 215|2@0+ (1.0000000000,0.0000000000) [0.0000000000|3.0000000000] "-"  RLR_L,mADC
 SG_ RLR_FreespaceSectorConRidence151 : 201|2@0+ (1.0000000000,0.0000000000) [0.0000000000|3.0000000000] "-"  RLR_L,mADC
 SG_ RLR_FreespaceSectorDistance151 : 195|10@0+ (0.1000000000,0.0000000000) [0.0000000000|100.0000000000] "-"  RLR_L,mADC
 SG_ RLR_FreespaceSectorKinestate150 : 197|2@0+ (1.0000000000,0.0000000000) [0.0000000000|3.0000000000] "-"  RLR_L,mADC
 SG_ RLR_FreespaceSectorConRidence150 : 199|2@0+ (1.0000000000,0.0000000000) [0.0000000000|3.0000000000] "-"  RLR_L,mADC
 SG_ RLR_FreespaceSectorDistance150 : 177|10@0+ (0.1000000000,0.0000000000) [0.0000000000|100.0000000000] "-"  RLR_L,mADC
 SG_ RLR_FreespaceSectorKinestate149 : 179|2@0+ (1.0000000000,0.0000000000) [0.0000000000|3.0000000000] "-"  RLR_L,mADC
 SG_ RLR_FreespaceSectorConRidence149 : 181|2@0+ (1.0000000000,0.0000000000) [0.0000000000|3.0000000000] "-"  RLR_L,mADC
 SG_ RLR_FreespaceSectorDistance149 : 175|10@0+ (0.1000000000,0.0000000000) [0.0000000000|100.0000000000] "-"  RLR_L,mADC
 SG_ RLR_FreespaceSectorKinestate148 : 161|2@0+ (1.0000000000,0.0000000000) [0.0000000000|3.0000000000] "-"  RLR_L,mADC
 SG_ RLR_FreespaceSectorConRidence148 : 163|2@0+ (1.0000000000,0.0000000000) [0.0000000000|3.0000000000] "-"  RLR_L,mADC
 SG_ RLR_FreespaceSectorDistance148 : 157|10@0+ (0.1000000000,0.0000000000) [0.0000000000|100.0000000000] "-"  RLR_L,mADC
 SG_ RLR_FreespaceSectorKinestate147 : 159|2@0+ (1.0000000000,0.0000000000) [0.0000000000|3.0000000000] "-"  RLR_L,mADC
 SG_ RLR_FreespaceSectorConRidence147 : 145|2@0+ (1.0000000000,0.0000000000) [0.0000000000|3.0000000000] "-"  RLR_L,mADC
 SG_ RLR_FreespaceSectorDistance147 : 139|10@0+ (0.1000000000,0.0000000000) [0.0000000000|100.0000000000] "-"  RLR_L,mADC
 SG_ RLR_FreespaceSectorKinestate146 : 141|2@0+ (1.0000000000,0.0000000000) [0.0000000000|3.0000000000] "-"  RLR_L,mADC
 SG_ RLR_FreespaceSectorConRidence146 : 143|2@0+ (1.0000000000,0.0000000000) [0.0000000000|3.0000000000] "-"  RLR_L,mADC
 SG_ RLR_FreespaceSectorDistance146 : 121|10@0+ (0.1000000000,0.0000000000) [0.0000000000|100.0000000000] "-"  RLR_L,mADC
 SG_ RLR_FreespaceSectorKinestate145 : 123|2@0+ (1.0000000000,0.0000000000) [0.0000000000|3.0000000000] "-"  RLR_L,mADC
 SG_ RLR_FreespaceSectorConRidence145 : 125|2@0+ (1.0000000000,0.0000000000) [0.0000000000|3.0000000000] "-"  RLR_L,mADC
 SG_ RLR_FreespaceSectorDistance145 : 119|10@0+ (0.1000000000,0.0000000000) [0.0000000000|100.0000000000] "-"  RLR_L,mADC
 SG_ RLR_FreespaceSectorKinestate144 : 105|2@0+ (1.0000000000,0.0000000000) [0.0000000000|3.0000000000] "-"  RLR_L,mADC
 SG_ RLR_FreespaceSectorConRidence144 : 107|2@0+ (1.0000000000,0.0000000000) [0.0000000000|3.0000000000] "-"  RLR_L,mADC
 SG_ RLR_FreespaceSectorDistance144 : 101|10@0+ (0.1000000000,0.0000000000) [0.0000000000|100.0000000000] "-"  RLR_L,mADC
 SG_ RLR_FreespaceSectorKinestate143 : 103|2@0+ (1.0000000000,0.0000000000) [0.0000000000|3.0000000000] "-"  RLR_L,mADC
 SG_ RLR_FreespaceSectorConRidence143 : 89|2@0+ (1.0000000000,0.0000000000) [0.0000000000|3.0000000000] "-"  RLR_L,mADC
 SG_ RLR_FreespaceSectorDistance143 : 83|10@0+ (0.1000000000,0.0000000000) [0.0000000000|100.0000000000] "-"  RLR_L,mADC
 SG_ RLR_FreespaceSectorKinestate142 : 85|2@0+ (1.0000000000,0.0000000000) [0.0000000000|3.0000000000] "-"  RLR_L,mADC
 SG_ RLR_FreespaceSectorConRidence142 : 87|2@0+ (1.0000000000,0.0000000000) [0.0000000000|3.0000000000] "-"  RLR_L,mADC
 SG_ RLR_FreespaceSectorDistance142 : 65|10@0+ (0.1000000000,0.0000000000) [0.0000000000|100.0000000000] "-"  RLR_L,mADC
 SG_ RLR_FreespaceSectorKinestate141 : 67|2@0+ (1.0000000000,0.0000000000) [0.0000000000|3.0000000000] "-"  RLR_L,mADC
 SG_ RLR_FreespaceSectorConRidence141 : 69|2@0+ (1.0000000000,0.0000000000) [0.0000000000|3.0000000000] "-"  RLR_L,mADC
 SG_ RLR_FreespaceSectorDistance141 : 63|10@0+ (0.1000000000,0.0000000000) [0.0000000000|100.0000000000] "-"  RLR_L,mADC
 SG_ RLR_FreespaceSectorKinestate140 : 49|2@0+ (1.0000000000,0.0000000000) [0.0000000000|3.0000000000] "-"  RLR_L,mADC
 SG_ RLR_FreespaceSectorConRidence140 : 51|2@0+ (1.0000000000,0.0000000000) [0.0000000000|3.0000000000] "-"  RLR_L,mADC
 SG_ RLR_FreespaceSectorDistance140 : 45|10@0+ (0.1000000000,0.0000000000) [0.0000000000|100.0000000000] "-"  RLR_L,mADC
 SG_ RLR_FreespaceSectorKinestate139 : 47|2@0+ (1.0000000000,0.0000000000) [0.0000000000|3.0000000000] "-"  RLR_L,mADC
 SG_ RLR_FreespaceSectorConRidence139 : 33|2@0+ (1.0000000000,0.0000000000) [0.0000000000|3.0000000000] "-"  RLR_L,mADC
 SG_ RLR_FreespaceSectorDistance139 : 27|10@0+ (0.1000000000,0.0000000000) [0.0000000000|100.0000000000] "-"  RLR_L,mADC
 SG_ RLR_FreespaceSectorKinestate138 : 29|2@0+ (1.0000000000,0.0000000000) [0.0000000000|3.0000000000] "-"  RLR_L,mADC
 SG_ RLR_FreespaceSectorConRidence138 : 31|2@0+ (1.0000000000,0.0000000000) [0.0000000000|3.0000000000] "-"  RLR_L,mADC
 SG_ RLR_FreespaceSectorDistance138 : 9|10@0+ (0.1000000000,0.0000000000) [0.0000000000|100.0000000000] "-"  RLR_L,mADC
 SG_ RLR_FreespaceSectorKinestate137 : 11|2@0+ (1.0000000000,0.0000000000) [0.0000000000|3.0000000000] "-"  RLR_L,mADC
 SG_ RLR_FreespaceSectorConRidence137 : 13|2@0+ (1.0000000000,0.0000000000) [0.0000000000|3.0000000000] "-"  RLR_L,mADC
 SG_ RLR_FreespaceSectorDistance137 : 7|10@0+ (0.1000000000,0.0000000000) [0.0000000000|100.0000000000] "-"  RLR_L,mADC

BO_ 927 RRR_L_39F: 64 RRR_L
 SG_ RLR_CRCCheck_39F : 503|16@0+ (1.0000000000,0.0000000000) [0.0000000000|65535.0000000000] ""  RLR_L,mADC
 SG_ RLR_RollingCounter_39F : 491|4@0+ (1.0000000000,0.0000000000) [0.0000000000|15.0000000000] ""  RLR_L,mADC
 SG_ RLR_FreespaceSectorKinestate180 : 141|2@0+ (1.0000000000,0.0000000000) [0.0000000000|3.0000000000] "-"  RLR_L,mADC
 SG_ RLR_FreespaceSectorConRidence180 : 143|2@0+ (1.0000000000,0.0000000000) [0.0000000000|3.0000000000] "-"  RLR_L,mADC
 SG_ RLR_FreespaceSectorDistance180 : 121|10@0+ (0.1000000000,0.0000000000) [0.0000000000|100.0000000000] "-"  RLR_L,mADC
 SG_ RLR_FreespaceSectorKinestate179 : 123|2@0+ (1.0000000000,0.0000000000) [0.0000000000|3.0000000000] "-"  RLR_L,mADC
 SG_ RLR_FreespaceSectorConRidence179 : 125|2@0+ (1.0000000000,0.0000000000) [0.0000000000|3.0000000000] "-"  RLR_L,mADC
 SG_ RLR_FreespaceSectorDistance179 : 119|10@0+ (0.1000000000,0.0000000000) [0.0000000000|100.0000000000] "-"  RLR_L,mADC
 SG_ RLR_FreespaceSectorKinestate178 : 105|2@0+ (1.0000000000,0.0000000000) [0.0000000000|3.0000000000] "-"  RLR_L,mADC
 SG_ RLR_FreespaceSectorConRidence178 : 107|2@0+ (1.0000000000,0.0000000000) [0.0000000000|3.0000000000] "-"  RLR_L,mADC
 SG_ RLR_FreespaceSectorDistance178 : 101|10@0+ (0.1000000000,0.0000000000) [0.0000000000|100.0000000000] "-"  RLR_L,mADC
 SG_ RLR_FreespaceSectorKinestate177 : 103|2@0+ (1.0000000000,0.0000000000) [0.0000000000|3.0000000000] "-"  RLR_L,mADC
 SG_ RLR_FreespaceSectorConRidence177 : 89|2@0+ (1.0000000000,0.0000000000) [0.0000000000|3.0000000000] "-"  RLR_L,mADC
 SG_ RLR_FreespaceSectorDistance177 : 83|10@0+ (0.1000000000,0.0000000000) [0.0000000000|100.0000000000] "-"  RLR_L,mADC
 SG_ RLR_FreespaceSectorKinestate176 : 85|2@0+ (1.0000000000,0.0000000000) [0.0000000000|3.0000000000] "-"  RLR_L,mADC
 SG_ RLR_FreespaceSectorConRidence176 : 87|2@0+ (1.0000000000,0.0000000000) [0.0000000000|3.0000000000] "-"  RLR_L,mADC
 SG_ RLR_FreespaceSectorDistance176 : 65|10@0+ (0.1000000000,0.0000000000) [0.0000000000|100.0000000000] "-"  RLR_L,mADC
 SG_ RLR_FreespaceSectorKinestate175 : 67|2@0+ (1.0000000000,0.0000000000) [0.0000000000|3.0000000000] "-"  RLR_L,mADC
 SG_ RLR_FreespaceSectorConRidence175 : 69|2@0+ (1.0000000000,0.0000000000) [0.0000000000|3.0000000000] "-"  RLR_L,mADC
 SG_ RLR_FreespaceSectorDistance175 : 63|10@0+ (0.1000000000,0.0000000000) [0.0000000000|100.0000000000] "-"  RLR_L,mADC
 SG_ RLR_FreespaceSectorKinestate174 : 49|2@0+ (1.0000000000,0.0000000000) [0.0000000000|3.0000000000] "-"  RLR_L,mADC
 SG_ RLR_FreespaceSectorConRidence174 : 51|2@0+ (1.0000000000,0.0000000000) [0.0000000000|3.0000000000] "-"  RLR_L,mADC
 SG_ RLR_FreespaceSectorDistance174 : 45|10@0+ (0.1000000000,0.0000000000) [0.0000000000|100.0000000000] "-"  RLR_L,mADC
 SG_ RLR_FreespaceSectorKinestate173 : 47|2@0+ (1.0000000000,0.0000000000) [0.0000000000|3.0000000000] "-"  RLR_L,mADC
 SG_ RLR_FreespaceSectorConRidence173 : 33|2@0+ (1.0000000000,0.0000000000) [0.0000000000|3.0000000000] "-"  RLR_L,mADC
 SG_ RLR_FreespaceSectorDistance173 : 27|10@0+ (0.1000000000,0.0000000000) [0.0000000000|100.0000000000] "-"  RLR_L,mADC
 SG_ RLR_FreespaceSectorKinestate172 : 29|2@0+ (1.0000000000,0.0000000000) [0.0000000000|3.0000000000] "-"  RLR_L,mADC
 SG_ RLR_FreespaceSectorConRidence172 : 31|2@0+ (1.0000000000,0.0000000000) [0.0000000000|3.0000000000] "-"  RLR_L,mADC
 SG_ RLR_FreespaceSectorDistance172 : 9|10@0+ (0.1000000000,0.0000000000) [0.0000000000|100.0000000000] "-"  RLR_L,mADC
 SG_ RLR_FreespaceSectorKinestate171 : 11|2@0+ (1.0000000000,0.0000000000) [0.0000000000|3.0000000000] "-"  RLR_L,mADC
 SG_ RLR_FreespaceSectorConRidence171 : 13|2@0+ (1.0000000000,0.0000000000) [0.0000000000|3.0000000000] "-"  RLR_L,mADC
 SG_ RLR_FreespaceSectorDistance171 : 7|10@0+ (0.1000000000,0.0000000000) [0.0000000000|100.0000000000] "-"  RLR_L,mADC

BO_ 693 RRR_L_2B5: 64 RRR_L
 SG_ RLR_CRCCheck_2B5 : 503|16@0+ (1.0000000000,0.0000000000) [0.0000000000|65535.0000000000] ""  RLR_L,mADC
 SG_ RLR_RollingCounter_2B5 : 491|4@0+ (1.0000000000,0.0000000000) [0.0000000000|15.0000000000] ""  RLR_L,mADC
 SG_ LCDAR_ResetSts : 250|3@0+ (1.0000000000,0.0000000000) [0.0000000000|7.0000000000] ""  RLR_L,mADC
 SG_ FuncDegradeType_RR : 223|32@0+ (1.0000000000,0.0000000000) [0.0000000000|4294967295.0000000000] ""  RLR_L,mADC
 SG_ FUSION_TimeoutCnt_RR : 215|8@0+ (1.0000000000,0.0000000000) [0.0000000000|255.0000000000] ""  RLR_L,mADC
 SG_ VALIDATION_TimeoutCnt_RR : 207|8@0+ (1.0000000000,0.0000000000) [0.0000000000|255.0000000000] ""  RLR_L,mADC
 SG_ CurFrameCycle_RR : 199|8@0+ (1.0000000000,0.0000000000) [0.0000000000|255.0000000000] ""  RLR_L,mADC
 SG_ ProcessTimeoutCnt_RR : 191|8@0+ (1.0000000000,0.0000000000) [0.0000000000|255.0000000000] ""  RLR_L,mADC
 SG_ RevFrameCnt_RR : 159|32@0+ (1.0000000000,0.0000000000) [0.0000000000|4294967295.0000000000] ""  RLR_L,mADC
 SG_ Local_Pointcloud_Number_RR : 151|8@0+ (1.0000000000,0.0000000000) [0.0000000000|255.0000000000] ""  RLR_L,mADC
 SG_ RealTimeCal_PrcssBar_RR : 142|7@0+ (1.0000000000,0.0000000000) [0.0000000000|100.0000000000] "%"  RLR_L,mADC
 SG_ RealTimeCal_VelErrOutput_RR : 134|7@0+ (0.1000000000,-5.0000000000) [-5.0000000000|5.0000000000] "%"  RLR_L,mADC
 SG_ RealTimeCal_HoriMntErrOutput_RR : 112|9@0+ (0.0200000000,-5.0000000000) [-5.0000000000|5.0000000000] "°"  RLR_L,mADC
 SG_ RealTimeCal_FailReasonCode_RR : 116|3@0+ (1.0000000000,0.0000000000) [0.0000000000|7.0000000000] ""  RLR_L,mADC
 SG_ RealTimeCal_Status_RR : 119|3@0+ (1.0000000000,0.0000000000) [0.0000000000|7.0000000000] ""  RLR_L,mADC
 SG_ DiagCal_PrcssBar_RR : 110|7@0+ (1.0000000000,0.0000000000) [0.0000000000|100.0000000000] "%"  RLR_L,mADC
 SG_ DiagCal_VelErrOutput_RR : 102|7@0+ (0.1000000000,-5.0000000000) [-5.0000000000|5.0000000000] "%"  RLR_L,mADC
 SG_ DiagCal_HoriMntErrOutput_RR : 80|9@0+ (0.0200000000,-5.0000000000) [-5.0000000000|5.0000000000] "°"  RLR_L,mADC
 SG_ DiagCal_FailReasonCode_RR : 84|3@0+ (1.0000000000,0.0000000000) [0.0000000000|7.0000000000] ""  RLR_L,mADC
 SG_ DiagCal_Status_RR : 87|3@0+ (1.0000000000,0.0000000000) [0.0000000000|7.0000000000] ""  RLR_L,mADC
 SG_ EolCal_PrcssBar_RR : 78|7@0+ (1.0000000000,0.0000000000) [0.0000000000|100.0000000000] "%"  RLR_L,mADC
 SG_ EolCal_VelErrOutput_RR : 70|7@0+ (0.1000000000,-5.0000000000) [-5.0000000000|5.0000000000] "%"  RLR_L,mADC
 SG_ EolCal_HoriMntErrOutput_RR : 48|9@0+ (0.0200000000,-5.0000000000) [-5.0000000000|5.0000000000] "°"  RLR_L,mADC
 SG_ EolCal_FailReasonCode_RR : 52|3@0+ (1.0000000000,0.0000000000) [0.0000000000|7.0000000000] ""  RLR_L,mADC
 SG_ EolCal_Status_RR : 55|3@0+ (1.0000000000,0.0000000000) [0.0000000000|7.0000000000] ""  RLR_L,mADC
 SG_ PriCounter_RR : 31|24@0+ (1.0000000000,0.0000000000) [0.0000000000|16777215.0000000000] ""  RLR_L,mADC
 SG_ MsgCounter_RR : 7|24@0+ (1.0000000000,0.0000000000) [0.0000000000|16777215.0000000000] ""  RLR_L,mADC

BO_ 338 mADC_152: 64 mADC
 SG_ ADR_TriggerEventReq : 303|6@0+ (1.0000000000,0.0000000000) [0.0000000000|63.0000000000] ""  RLR_L,RRR_L
 SG_ ADC_RollingCounter_152 : 491|4@0+ (1.0000000000,0.0000000000) [0.0000000000|15.0000000000] ""  RLR_L,RRR_L
 SG_ ADC_CRCCheck_152 : 503|16@0+ (1.0000000000,0.0000000000) [0.0000000000|65535.0000000000] ""  RLR_L,RRR_L
 SG_ ADC_SenceMode : 131|2@0+ (1.0000000000,0.0000000000) [0.0000000000|3.0000000000] ""  RLR_L,RRR_L

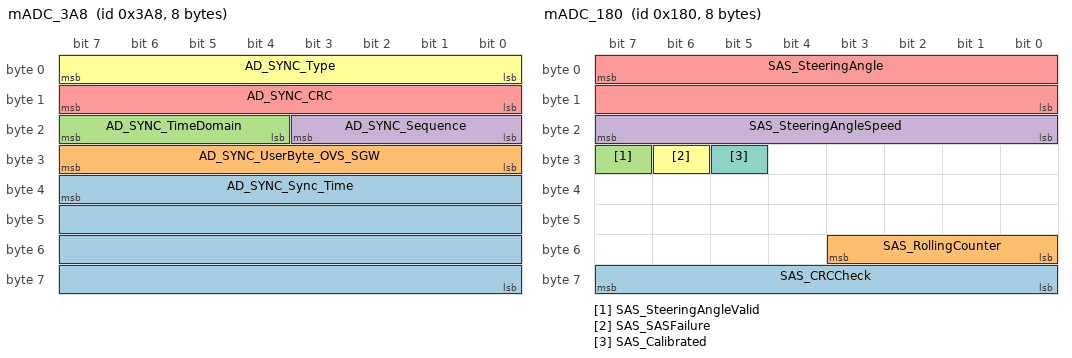
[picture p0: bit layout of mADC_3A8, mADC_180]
BO_ 936 mADC_3A8: 8 mADC
 SG_ AD_SYNC_Sync_Time : 39|32@0+ (1.0000000000,0.0000000000) [0.0000000000|4290000000.0000000000] ""  RLR_L,RRR_L
 SG_ AD_SYNC_UserByte_OVS_SGW : 31|8@0+ (1.0000000000,0.0000000000) [0.0000000000|255.0000000000] ""  RLR_L,RRR_L
 SG_ AD_SYNC_TimeDomain : 23|4@0+ (1.0000000000,0.0000000000) [0.0000000000|15.0000000000] ""  RLR_L,RRR_L
 SG_ AD_SYNC_Sequence : 19|4@0+ (1.0000000000,0.0000000000) [0.0000000000|15.0000000000] ""  RLR_L,RRR_L
 SG_ AD_SYNC_CRC : 15|8@0+ (1.0000000000,0.0000000000) [0.0000000000|255.0000000000] ""  RLR_L,RRR_L
 SG_ AD_SYNC_Type : 7|8@0+ (1.0000000000,0.0000000000) [0.0000000000|255.0000000000] ""  RLR_L,RRR_L

BO_ 384 mADC_180: 8 mADC
 SG_ SAS_CRCCheck : 63|8@0+ (1.0000000000,0.0000000000) [0.0000000000|255.0000000000] ""  RLR_L,RRR_L
 SG_ SAS_RollingCounter : 51|4@0+ (1.0000000000,0.0000000000) [0.0000000000|15.0000000000] ""  RLR_L,RRR_L
 SG_ SAS_SteeringAngleValid : 31|1@0+ (1.0000000000,0.0000000000) [0.0000000000|1.0000000000] ""  RLR_L,RRR_L
 SG_ SAS_SteeringAngleSpeed : 23|8@0+ (4.0000000000,0.0000000000) [0.0000000000|1016.0000000000] "deg/s"  RLR_L,RRR_L
 SG_ SAS_SteeringAngle : 7|16@0- (0.1000000000,0.0000000000) [-780.0000000000|780.0000000000] "degree"  RLR_L,RRR_L
 SG_ SAS_SASFailure : 30|1@0+ (1.0000000000,0.0000000000) [0.0000000000|1.0000000000] ""  RLR_L,RRR_L
 SG_ SAS_Calibrated : 29|1@0+ (1.0000000000,0.0000000000) [0.0000000000|1.0000000000] ""  RLR_L,RRR_L

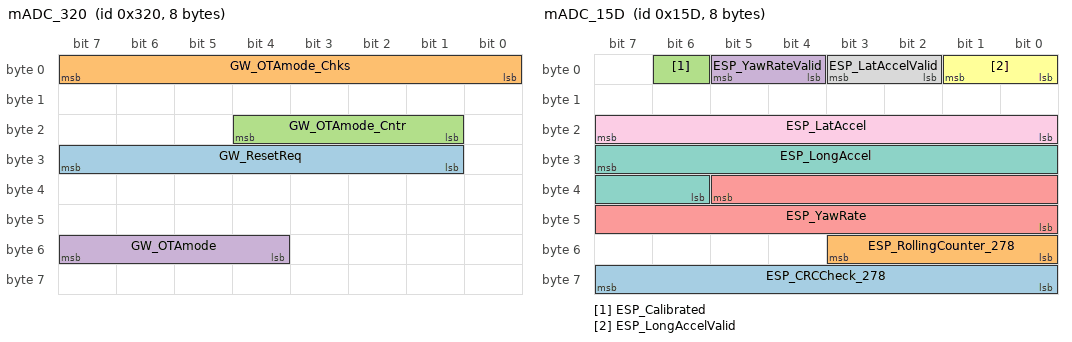
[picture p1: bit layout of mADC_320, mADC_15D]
BO_ 800 mADC_320: 8 mADC
 SG_ GW_ResetReq : 31|7@0+ (1.0000000000,0.0000000000) [0.0000000000|127.0000000000] ""  RLR_L,RRR_L
 SG_ GW_OTAmode_Chks : 7|8@0+ (1.0000000000,0.0000000000) [0.0000000000|255.0000000000] ""  RLR_L,RRR_L
 SG_ GW_OTAmode_Cntr : 20|4@0+ (1.0000000000,0.0000000000) [0.0000000000|15.0000000000] ""  RLR_L,RRR_L
 SG_ GW_OTAmode : 55|4@0+ (1.0000000000,0.0000000000) [0.0000000000|15.0000000000] ""  RLR_L,RRR_L

BO_ 1302 mADC_516: 32 mADC
 SG_ HU_LocalTimeValid : 71|1@0+ (1.0000000000,0.0000000000) [0.0000000000|1.0000000000] ""  RLR_L,RRR_L
 SG_ HU_LocalTimeSecond : 109|6@0+ (1.0000000000,0.0000000000) [0.0000000000|59.0000000000] "second"  RLR_L,RRR_L
 SG_ HU_LocalTimeMinute : 101|6@0+ (1.0000000000,0.0000000000) [0.0000000000|59.0000000000] "minute"  RLR_L,RRR_L
 SG_ HU_LocalTimeHour : 92|5@0+ (1.0000000000,0.0000000000) [0.0000000000|23.0000000000] "hour"  RLR_L,RRR_L
 SG_ HU_LocalTimeDate : 84|5@0+ (1.0000000000,0.0000000000) [1.0000000000|31.0000000000] "day"  RLR_L,RRR_L
 SG_ HU_LocalTimeMonth : 75|4@0+ (1.0000000000,0.0000000000) [1.0000000000|12.0000000000] "month"  RLR_L,RRR_L
 SG_ HU_LocalTimeYear : 119|8@0+ (1.0000000000,2013.0000000000) [2013.0000000000|2268.0000000000] "year"  RLR_L,RRR_L
 SG_ HU_CurrentLocationLatitude : 35|28@0+ (0.0000010000,-134.2177270000) [-90.0000000000|90.0000000000] "degree"  RLR_L,RRR_L
 SG_ HU_CurrentLocationLongitude : 4|29@0+ (0.0000010000,-268.4354550000) [-180.0000000000|180.0000000000] "degree"  RLR_L,RRR_L
 SG_ HU_CurrentLocationValid : 7|1@0+ (1.0000000000,0.0000000000) [0.0000000000|1.0000000000] ""  RLR_L,RRR_L

BO_ 349 mADC_15D: 8 mADC
 SG_ ESP_CRCCheck_278 : 63|8@0+ (1.0000000000,0.0000000000) [0.0000000000|255.0000000000] ""  RLR_L,RRR_L
 SG_ ESP_RollingCounter_278 : 51|4@0+ (1.0000000000,0.0000000000) [0.0000000000|15.0000000000] ""  RLR_L,RRR_L
 SG_ ESP_Calibrated : 6|1@0+ (1.0000000000,0.0000000000) [0.0000000000|1.0000000000] ""  RLR_L,RRR_L
 SG_ ESP_YawRateValid : 5|2@0+ (1.0000000000,0.0000000000) [0.0000000000|3.0000000000] ""  RLR_L,RRR_L
 SG_ ESP_YawRate : 37|14@0+ (0.0100000000,-81.9100000000) [-81.9100000000|81.9100000000] "degree/s"  RLR_L,RRR_L
 SG_ ESP_LongAccelValid : 1|2@0+ (1.0000000000,0.0000000000) [0.0000000000|3.0000000000] ""  RLR_L,RRR_L
 SG_ ESP_LongAccel : 31|10@0+ (0.0312500000,-16.0000000000) [-16.0000000000|15.9062500000] "m/s2"  RLR_L,RRR_L
 SG_ ESP_LatAccelValid : 3|2@0+ (1.0000000000,0.0000000000) [0.0000000000|3.0000000000] ""  RLR_L,RRR_L
 SG_ ESP_LatAccel : 23|8@0+ (0.1000000000,-12.7000000000) [-12.7000000000|12.7000000000] "m/s2"  RLR_L,RRR_L

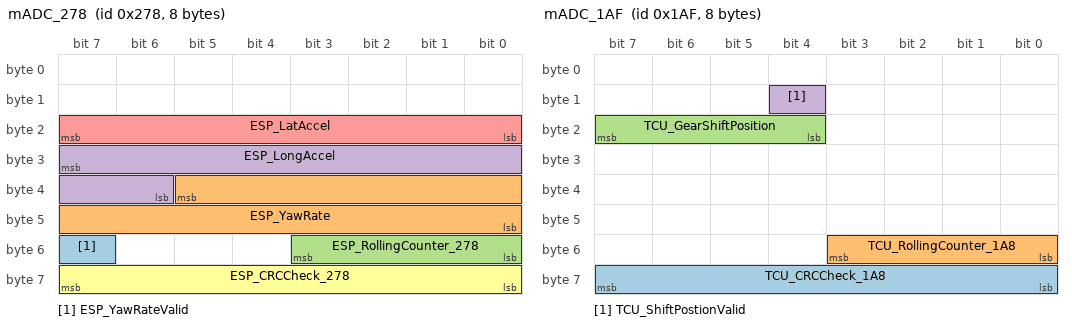
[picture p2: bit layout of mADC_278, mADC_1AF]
BO_ 632 mADC_278: 8 mADC
 SG_ ESP_YawRateValid : 55|1@0+ (1.0000000000,0.0000000000) [0.0000000000|1.0000000000] ""  RLR_L,RRR_L
 SG_ ESP_YawRate : 37|14@0+ (0.0100000000,-81.9100000000) [-81.9100000000|81.9100000000] "degree/s"  RLR_L,RRR_L
 SG_ ESP_RollingCounter_278 : 51|4@0+ (1.0000000000,0.0000000000) [0.0000000000|15.0000000000] ""  RLR_L,RRR_L
 SG_ ESP_LongAccel : 31|10@0+ (0.0312500000,-16.0000000000) [-16.0000000000|15.9062500000] "m/s2"  RLR_L,RRR_L
 SG_ ESP_LatAccel : 23|8@0+ (0.1000000000,-12.7000000000) [-12.7000000000|12.7000000000] "m/s2"  RLR_L,RRR_L
 SG_ ESP_CRCCheck_278 : 63|8@0+ (1.0000000000,0.0000000000) [0.0000000000|255.0000000000] ""  RLR_L,RRR_L

BO_ 378 mADC_17A: 64 mADC
 SG_ ESP_TCSFailStatus : 4|1@0+ (1.0000000000,0.0000000000) [0.0000000000|1.0000000000] ""  RLR_L,RRR_L
 SG_ ESP_ESPFunctionStatus : 1|1@0+ (1.0000000000,0.0000000000) [0.0000000000|1.0000000000] ""  RLR_L,RRR_L
 SG_ ESP_ESPActiveStatus : 0|1@0+ (1.0000000000,0.0000000000) [0.0000000000|1.0000000000] ""  RLR_L,RRR_L
 SG_ ESP_ABSFailStatus : 3|1@0+ (1.0000000000,0.0000000000) [0.0000000000|1.0000000000] ""  RLR_L,RRR_L
 SG_ ESP_ABSActiveStatus : 7|1@0+ (1.0000000000,0.0000000000) [0.0000000000|1.0000000000] ""  RLR_L,RRR_L
 SG_ ESP_VehicleSpeedValid : 37|1@0+ (1.0000000000,0.0000000000) [0.0000000000|1.0000000000] ""  RLR_L,RRR_L
 SG_ ESP_VehicleSpeed : 36|13@0+ (0.0562500000,0.0000000000) [0.0000000000|360.0000000000] "km/h"  RLR_L,RRR_L

BO_ 523 mADC_20B: 64 mADC
 SG_ ESP_RollingCounter_20B : 491|4@0+ (1.0000000000,0.0000000000) [0.0000000000|15.0000000000] ""  RLR_L,RRR_L
 SG_ ESP_CRCCheck_20B : 503|16@0+ (1.0000000000,0.0000000000) [0.0000000000|65535.0000000000] ""  RLR_L,RRR_L
 SG_ ESP_PrefillAvailable : 259|1@0+ (1.0000000000,0.0000000000) [0.0000000000|1.0000000000] ""  RLR_L,RRR_L
 SG_ ESP_PrefillActive : 260|1@0+ (1.0000000000,0.0000000000) [0.0000000000|1.0000000000] ""  RLR_L,RRR_L
 SG_ ESP_BrakeOverHeatBrakeDiscTemp : 270|1@0+ (1.0000000000,0.0000000000) [0.0000000000|1.0000000000] ""  RLR_L,RRR_L
 SG_ ESP_BrakeForce : 263|1@0+ (1.0000000000,0.0000000000) [0.0000000000|1.0000000000] ""  RLR_L,RRR_L
 SG_ ESP_AEBdecActive : 257|1@0+ (1.0000000000,0.0000000000) [0.0000000000|1.0000000000] ""  RLR_L,RRR_L
 SG_ ESP_AEBAvailable : 258|1@0+ (1.0000000000,0.0000000000) [0.0000000000|1.0000000000] ""  RLR_L,RRR_L
 SG_ ESP_VDCActive : 266|1@0+ (1.0000000000,0.0000000000) [0.0000000000|1.0000000000] ""  RLR_L,RRR_L
 SG_ ESP_TCSActive : 265|1@0+ (1.0000000000,0.0000000000) [0.0000000000|1.0000000000] ""  RLR_L,RRR_L
 SG_ ESP_OnlyABSActive : 264|1@0+ (1.0000000000,0.0000000000) [0.0000000000|1.0000000000] ""  RLR_L,RRR_L
 SG_ Wheel_Speed_RR_Valid_Data : 71|1@0+ (1.0000000000,0.0000000000) [0.0000000000|1.0000000000] ""  RLR_L,RRR_L
 SG_ Wheel_Speed_RR_Pulse : 231|8@0+ (1.0000000000,0.0000000000) [0.0000000000|254.0000000000] ""  RLR_L,RRR_L
 SG_ Wheel_Speed_RR_Direction : 70|2@0+ (1.0000000000,0.0000000000) [0.0000000000|3.0000000000] ""  RLR_L,RRR_L
 SG_ Wheel_Speed_RR_Data : 68|13@0+ (0.0562500000,0.0000000000) [0.0000000000|360.0000000000] "km/h"  RLR_L,RRR_L
 SG_ Wheel_Speed_RL_Valid_Data : 87|1@0+ (1.0000000000,0.0000000000) [0.0000000000|1.0000000000] ""  RLR_L,RRR_L
 SG_ Wheel_Speed_RL_Pulse : 239|8@0+ (1.0000000000,0.0000000000) [0.0000000000|254.0000000000] ""  RLR_L,RRR_L
 SG_ Wheel_Speed_RL_Direction : 86|2@0+ (1.0000000000,0.0000000000) [0.0000000000|3.0000000000] ""  RLR_L,RRR_L
 SG_ Wheel_Speed_RL_Data : 84|13@0+ (0.0562500000,0.0000000000) [0.0000000000|360.0000000000] "km/h"  RLR_L,RRR_L
 SG_ Wheel_Speed_FR_Valid_Data : 7|1@0+ (1.0000000000,0.0000000000) [0.0000000000|1.0000000000] ""  RLR_L,RRR_L
 SG_ Wheel_Speed_FR_Pulse : 223|8@0+ (1.0000000000,0.0000000000) [0.0000000000|254.0000000000] ""  RLR_L,RRR_L
 SG_ Wheel_Speed_FR_Direction : 6|2@0+ (1.0000000000,0.0000000000) [0.0000000000|3.0000000000] ""  RLR_L,RRR_L
 SG_ Wheel_Speed_FR_Data : 4|13@0+ (0.0562500000,0.0000000000) [0.0000000000|360.0000000000] "km/h"  RLR_L,RRR_L
 SG_ Wheel_Speed_FL_Valid_Data : 23|1@0+ (1.0000000000,0.0000000000) [0.0000000000|1.0000000000] ""  RLR_L,RRR_L
 SG_ Wheel_Speed_FL_Pulse : 215|8@0+ (1.0000000000,0.0000000000) [0.0000000000|254.0000000000] ""  RLR_L,RRR_L
 SG_ Wheel_Speed_FL_Direction : 22|2@0+ (1.0000000000,0.0000000000) [0.0000000000|3.0000000000] ""  RLR_L,RRR_L
 SG_ Wheel_Speed_FL_Data : 20|13@0+ (0.0562500000,0.0000000000) [0.0000000000|360.0000000000] "km/h"  RLR_L,RRR_L
 SG_ IBCU_BrkPedlStsGbVld : 303|2@0+ (1.0000000000,0.0000000000) [0.0000000000|2.0000000000] ""  RLR_L,RRR_L
 SG_ IBCU_BrkPedoplStsGb : 295|8@0+ (1.0000000000,0.0000000000) [0.0000000000|255.0000000000] "%"  RLR_L,RRR_L
 SG_ ESP_VehicleStandstillVld : 286|1@0+ (1.0000000000,0.0000000000) [0.0000000000|1.0000000000] ""  RLR_L,RRR_L
 SG_ ESP_VehicleStandstill : 267|1@0+ (1.0000000000,0.0000000000) [0.0000000000|1.0000000000] ""  RLR_L,RRR_L

BO_ 271 mADC_10F: 8 mADC
 SG_ IBCU_sOutputRodAct_Q : 29|2@0+ (1.0000000000,0.0000000000) [0.0000000000|3.0000000000] ""  RLR_L,RRR_L
 SG_ IBCU_sOutputRodAct : 27|12@0+ (0.0156250000,-5.0000000000) [-5.0000000000|47.0000000000] "mm"  RLR_L,RRR_L

BO_ 381 mADC_17D: 64 mADC
 SG_ PCU_RollingCounter_17D : 491|4@0+ (1.0000000000,0.0000000000) [0.0000000000|15.0000000000] ""  RLR_L,RRR_L
 SG_ PCU_CRCCheck_17D : 503|16@0+ (1.0000000000,0.0000000000) [0.0000000000|65535.0000000000] ""  RLR_L,RRR_L
 SG_ PCU_RealAccPedlVld : 79|1@0+ (1.0000000000,0.0000000000) [0.0000000000|1.0000000000] ""  RLR_L,RRR_L
 SG_ PCU_RealAccPedl : 71|8@0+ (0.3920000000,0.0000000000) [0.0000000000|99.9600000000] "%"  RLR_L,RRR_L

BO_ 398 mADC_18E: 32 mADC
 SG_ EMS_BrakePedalStatus : 119|2@0+ (1.0000000000,0.0000000000) [0.0000000000|3.0000000000] ""  RLR_L,RRR_L
 SG_ EMS_RollingCounter_18E : 235|4@0+ (1.0000000000,0.0000000000) [0.0000000000|15.0000000000] ""  RLR_L,RRR_L
 SG_ EMS_CRCCheck_18E : 247|16@0+ (1.0000000000,0.0000000000) [0.0000000000|65535.0000000000] ""  RLR_L,RRR_L
 SG_ EMS_RealAccPedal : 71|8@0+ (0.3920000000,0.0000000000) [0.0000000000|99.5680000000] "%"  RLR_L,RRR_L

BO_ 431 mADC_1AF: 8 mADC
 SG_ TCU_CRCCheck_1A8 : 63|8@0+ (1.0000000000,0.0000000000) [0.0000000000|255.0000000000] ""  RLR_L,RRR_L
 SG_ TCU_RollingCounter_1A8 : 51|4@0+ (1.0000000000,0.0000000000) [0.0000000000|15.0000000000] ""  RLR_L,RRR_L
 SG_ TCU_GearShiftPosition : 23|4@0+ (1.0000000000,0.0000000000) [0.0000000000|15.0000000000] ""  RLR_L,RRR_L
 SG_ TCU_ShiftPostionValid : 12|1@0+ (1.0000000000,0.0000000000) [0.0000000000|1.0000000000] ""  RLR_L,RRR_L

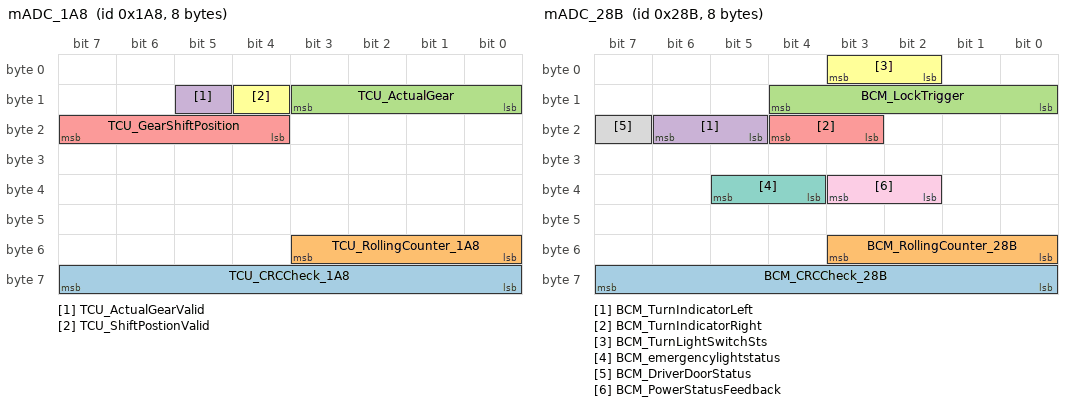
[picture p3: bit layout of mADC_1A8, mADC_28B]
BO_ 424 mADC_1A8: 8 mADC
 SG_ TCU_CRCCheck_1A8 : 63|8@0+ (1.0000000000,0.0000000000) [0.0000000000|255.0000000000] ""  RLR_L,RRR_L
 SG_ TCU_RollingCounter_1A8 : 51|4@0+ (1.0000000000,0.0000000000) [0.0000000000|15.0000000000] ""  RLR_L,RRR_L
 SG_ TCU_ActualGear : 11|4@0+ (1.0000000000,0.0000000000) [0.0000000000|15.0000000000] ""  RLR_L,RRR_L
 SG_ TCU_ActualGearValid : 13|1@0+ (1.0000000000,0.0000000000) [0.0000000000|1.0000000000] ""  RLR_L,RRR_L
 SG_ TCU_GearShiftPosition : 23|4@0+ (1.0000000000,0.0000000000) [0.0000000000|15.0000000000] ""  RLR_L,RRR_L
 SG_ TCU_ShiftPostionValid : 12|1@0+ (1.0000000000,0.0000000000) [0.0000000000|1.0000000000] ""  RLR_L,RRR_L

BO_ 796 mADC_31C: 8 mADC
 SG_ PCU_VcuRdySts : 16|1@0+ (1.0000000000,0.0000000000) [0.0000000000|1.0000000000] ""  RLR_L,RRR_L

BO_ 651 mADC_28B: 8 mADC
 SG_ BCM_CRCCheck_28B : 63|8@0+ (1.0000000000,0.0000000000) [0.0000000000|255.0000000000] ""  RLR_L,RRR_L
 SG_ BCM_RollingCounter_28B : 51|4@0+ (1.0000000000,0.0000000000) [0.0000000000|15.0000000000] ""  RLR_L,RRR_L
 SG_ BCM_LockTrigger : 12|5@0+ (1.0000000000,0.0000000000) [0.0000000000|31.0000000000] ""  RLR_L,RRR_L
 SG_ BCM_TurnIndicatorLeft : 22|2@0+ (1.0000000000,0.0000000000) [0.0000000000|3.0000000000] ""  RLR_L,RRR_L
 SG_ BCM_TurnIndicatorRight : 20|2@0+ (1.0000000000,0.0000000000) [0.0000000000|3.0000000000] ""  RLR_L,RRR_L
 SG_ BCM_TurnLightSwitchSts : 3|2@0+ (1.0000000000,0.0000000000) [0.0000000000|3.0000000000] ""  RLR_L,RRR_L
 SG_ BCM_emergencylightstatus : 37|2@0+ (1.0000000000,0.0000000000) [0.0000000000|3.0000000000] ""  RLR_L,RRR_L
 SG_ BCM_DriverDoorStatus : 23|1@0+ (1.0000000000,0.0000000000) [0.0000000000|1.0000000000] ""  RLR_L,RRR_L
 SG_ BCM_PowerStatusFeedback : 35|2@0+ (1.0000000000,0.0000000000) [0.0000000000|3.0000000000] ""  RLR_L,RRR_L

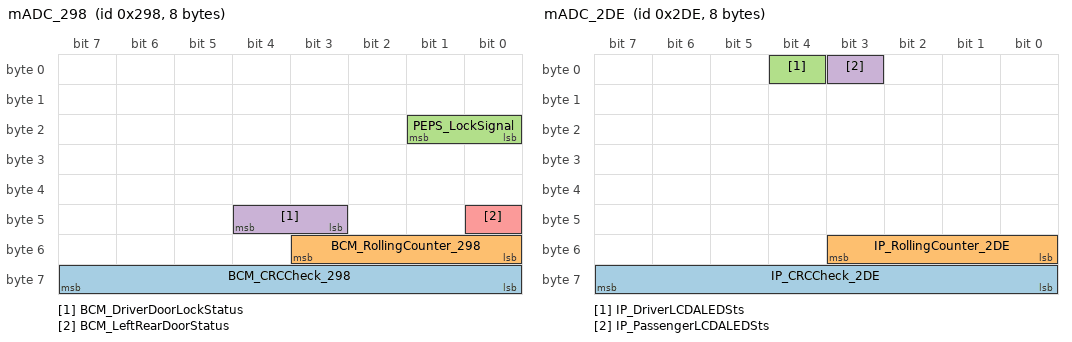
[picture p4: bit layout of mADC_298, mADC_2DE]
BO_ 664 mADC_298: 8 mADC
 SG_ BCM_CRCCheck_298 : 63|8@0+ (1.0000000000,0.0000000000) [0.0000000000|255.0000000000] ""  RLR_L,RRR_L
 SG_ BCM_RollingCounter_298 : 51|4@0+ (1.0000000000,0.0000000000) [0.0000000000|15.0000000000] ""  RLR_L,RRR_L
 SG_ PEPS_LockSignal : 17|2@0+ (1.0000000000,0.0000000000) [0.0000000000|3.0000000000] ""  RLR_L,RRR_L
 SG_ BCM_DriverDoorLockStatus : 44|2@0+ (1.0000000000,0.0000000000) [0.0000000000|3.0000000000] ""  RLR_L,RRR_L
 SG_ BCM_LeftRearDoorStatus : 40|1@0+ (1.0000000000,0.0000000000) [0.0000000000|1.0000000000] ""  RLR_L,RRR_L

BO_ 721 mADC_2D1: 8 mADC
 SG_ BCM_RightRearDoorStatus : 38|1@0+ (1.0000000000,0.0000000000) [0.0000000000|1.0000000000] ""  RLR_L,RRR_L
 SG_ BCM_PassengerDoorStatus : 45|1@0+ (1.0000000000,0.0000000000) [0.0000000000|1.0000000000] ""  RLR_L,RRR_L

BO_ 734 mADC_2DE: 8 mADC
 SG_ IP_CRCCheck_2DE : 63|8@0+ (1.0000000000,0.0000000000) [0.0000000000|255.0000000000] ""  RLR_L,RRR_L
 SG_ IP_RollingCounter_2DE : 51|4@0+ (1.0000000000,0.0000000000) [0.0000000000|15.0000000000] ""  RLR_L,RRR_L
 SG_ IP_DriverLCDALEDSts : 4|1@0+ (1.0000000000,0.0000000000) [0.0000000000|1.0000000000] ""  RLR_L,RRR_L
 SG_ IP_PassengerLCDALEDSts : 3|1@0+ (1.0000000000,0.0000000000) [0.0000000000|1.0000000000] ""  RLR_L,RRR_L

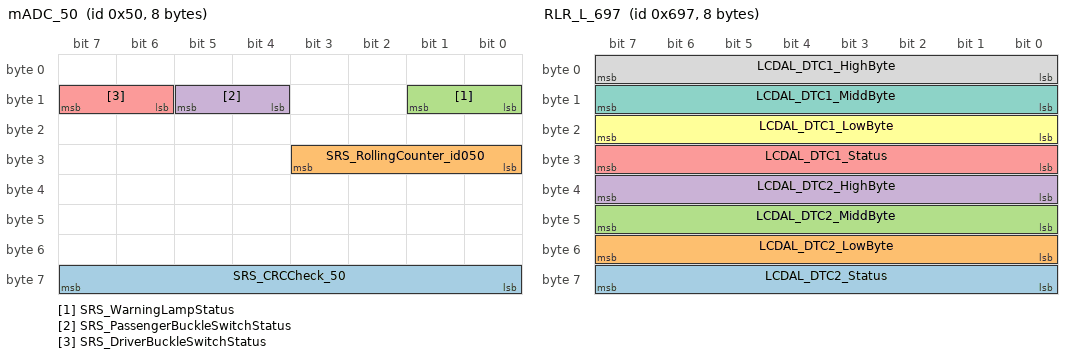
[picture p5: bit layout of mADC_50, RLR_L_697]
BO_ 80 mADC_50: 8 mADC
 SG_ SRS_CRCCheck_50 : 63|8@0+ (1.0000000000,0.0000000000) [0.0000000000|255.0000000000] ""  RLR_L,RRR_L
 SG_ SRS_RollingCounter_id050 : 27|4@0+ (1.0000000000,0.0000000000) [0.0000000000|15.0000000000] ""  RLR_L,RRR_L
 SG_ SRS_WarningLampStatus : 9|2@0+ (1.0000000000,0.0000000000) [0.0000000000|3.0000000000] ""  RLR_L,RRR_L
 SG_ SRS_PassengerBuckleSwitchStatus : 13|2@0+ (1.0000000000,0.0000000000) [0.0000000000|3.0000000000] ""  RLR_L,RRR_L
 SG_ SRS_DriverBuckleSwitchStatus : 15|2@0+ (1.0000000000,0.0000000000) [0.0000000000|3.0000000000] ""  RLR_L,RRR_L

BO_ 870 mADC_366: 8 mADC
 SG_ AC_EnvironmentalTemp : 23|8@0+ (0.5000000000,-40.0000000000) [-40.0000000000|87.0000000000] "degreeC"  RLR_L,RRR_L
 SG_ AC_EnvironmentalTempVD : 8|1@0+ (1.0000000000,0.0000000000) [0.0000000000|1.0000000000] ""  RLR_L,RRR_L

BO_ 1287 mADC_507: 64 mADC
 SG_ HU_AudioWarningEnable : 25|2@0+ (1.0000000000,0.0000000000) [0.0000000000|3.0000000000] ""  RLR_L,RRR_L
 SG_ HU_RCTBEnable : 19|2@0+ (1.0000000000,0.0000000000) [0.0000000000|3.0000000000] ""  RLR_L,RRR_L
 SG_ HU_RCTAEnable : 0|2@0+ (1.0000000000,0.0000000000) [0.0000000000|3.0000000000] ""  RLR_L,RRR_L
 SG_ HU_BSDLCASetting : 162|3@0+ (1.0000000000,0.0000000000) [0.0000000000|7.0000000000] ""  RLR_L,RRR_L
 SG_ HU_SEAEnable : 17|2@0+ (1.0000000000,0.0000000000) [0.0000000000|3.0000000000] ""  RLR_L,RRR_L
 SG_ HU_RCWEnable : 14|2@0+ (1.0000000000,0.0000000000) [0.0000000000|3.0000000000] ""  RLR_L,RRR_L

BO_ 1328 mADC_530: 8 mADC
 SG_ IP_TotalOdometer : 23|24@0+ (0.1000000000,0.0000000000) [0.0000000000|999999.0000000000] "Km"  RLR_L,RRR_L

BO_ 903 mADC_387: 8 mADC
 SG_ BCM_PowersaveModeStatus : 21|2@0+ (1.0000000000,0.0000000000) [0.0000000000|3.0000000000] ""  RLR_L,RRR_L

BO_ 964 mADC_3C4: 64 mADC
 SG_ HU_BSDLCAMode : 183|3@0+ (1.0000000000,0.0000000000) [0.0000000000|7.0000000000] ""  RLR_L,RRR_L

BO_ 579 mADC_243: 64 mADC
 SG_ Transmitcnt6_F : 455|32@0+ (1.0000000000,0.0000000000) [0.0000000000|4294967295.0000000000] ""  RLR_L,RRR_L
 SG_ Transmitcnt5_F : 423|32@0+ (1.0000000000,0.0000000000) [0.0000000000|4294967295.0000000000] ""  RLR_L,RRR_L
 SG_ Transmitcnt4_F : 391|32@0+ (1.0000000000,0.0000000000) [0.0000000000|4294967295.0000000000] ""  RLR_L,RRR_L
 SG_ Transmitcnt3_F : 359|32@0+ (1.0000000000,0.0000000000) [0.0000000000|4294967295.0000000000] ""  RLR_L,RRR_L
 SG_ Transmitcnt2_F : 327|32@0+ (1.0000000000,0.0000000000) [0.0000000000|4294967295.0000000000] ""  RLR_L,RRR_L
 SG_ Transmitcnt1_F : 295|32@0+ (1.0000000000,0.0000000000) [0.0000000000|4294967295.0000000000] ""  RLR_L,RRR_L
 SG_ FLR_Track_ID_R : 270|7@0+ (1.0000000000,0.0000000000) [0.0000000000|127.0000000000] ""  RLR_L,RRR_L
 SG_ FLR_Measured_R : 273|2@0+ (1.0000000000,0.0000000000) [0.0000000000|3.0000000000] ""  RLR_L,RRR_L
 SG_ FLR_Location_R : 199|2@0+ (1.0000000000,0.0000000000) [0.0000000000|3.0000000000] ""  RLR_L,RRR_L
 SG_ FLR_ClassComfrmFlg_R : 271|1@0+ (1.0000000000,0.0000000000) [0.0000000000|1.0000000000] ""  RLR_L,RRR_L
 SG_ FLR_TrckrType_R : 197|3@0+ (1.0000000000,0.0000000000) [0.0000000000|7.0000000000] ""  RLR_L,RRR_L
 SG_ FLR_TrckrAge_R : 263|8@0+ (1.0000000000,0.0000000000) [0.0000000000|255.0000000000] ""  RLR_L,RRR_L
 SG_ FLR_MotionStatus_R : 194|3@0+ (1.0000000000,0.0000000000) [0.0000000000|7.0000000000] ""  RLR_L,RRR_L
 SG_ FLR_AbsVy_R : 207|12@0+ (0.0625000000,-128.0000000000) [-128.0000000000|127.9380000000] "m/s"  RLR_L,RRR_L
 SG_ FLR_AbsoVx_R : 211|10@0+ (0.1250000000,-64.0000000000) [-64.0000000000|63.8750000000] "m/s"  RLR_L,RRR_L
 SG_ FLR_LocDx_R : 217|13@0+ (0.0625000000,-256.0000000000) [-256.0000000000|255.9380000000] "m"  RLR_L,RRR_L
 SG_ FLR_LocDy_R : 236|11@0+ (0.1250000000,-128.0000000000) [-128.0000000000|127.8750000000] "m"  RLR_L,RRR_L
 SG_ FLR_HeadingAngle_R : 241|10@0+ (0.0100000000,-3.1400000000) [-3.1400000000|3.1400000000] "rad"  RLR_L,RRR_L
 SG_ FLR_Length_R : 132|9@0+ (0.0500000000,0.0000000000) [0.0000000000|25.5000000000] "m"  RLR_L,RRR_L
 SG_ FLR_Width_R : 139|11@0+ (0.0100000000,0.0000000000) [0.0000000000|12.0000000000] "m"  RLR_L,RRR_L
 SG_ FLR_Track_ID_L : 144|7@0+ (1.0000000000,0.0000000000) [0.0000000000|127.0000000000] ""  RLR_L,RRR_L
 SG_ FLR_Measured_L : 153|2@0+ (1.0000000000,0.0000000000) [0.0000000000|3.0000000000] ""  RLR_L,RRR_L
 SG_ FLR_Location_L : 167|2@0+ (1.0000000000,0.0000000000) [0.0000000000|3.0000000000] ""  RLR_L,RRR_L
 SG_ FLR_ClassComfrmFlg_L : 164|1@0+ (1.0000000000,0.0000000000) [0.0000000000|1.0000000000] ""  RLR_L,RRR_L
 SG_ FLR_TrckrType_L : 163|3@0+ (1.0000000000,0.0000000000) [0.0000000000|7.0000000000] ""  RLR_L,RRR_L
 SG_ FLR_TrckrAge_L : 71|8@0+ (1.0000000000,0.0000000000) [0.0000000000|255.0000000000] ""  RLR_L,RRR_L
 SG_ FLR_MotionStatus_L : 160|3@0+ (1.0000000000,0.0000000000) [0.0000000000|7.0000000000] ""  RLR_L,RRR_L
 SG_ FLR_AbsVy_L : 173|12@0+ (0.0625000000,-128.0000000000) [-128.0000000000|127.9380000000] "m/s"  RLR_L,RRR_L
 SG_ FLR_AbsoVx_L : 177|10@0+ (0.1250000000,-64.0000000000) [-64.0000000000|63.8750000000] "m/s"  RLR_L,RRR_L
 SG_ FLR_LocDx_L : 79|13@0+ (0.0625000000,-256.0000000000) [-256.0000000000|255.9380000000] "m"  RLR_L,RRR_L
 SG_ FLR_LocDy_L : 82|11@0+ (0.1250000000,-128.0000000000) [-128.0000000000|127.8750000000] "m"  RLR_L,RRR_L
 SG_ FLR_HeadingAngle_L : 103|10@0+ (0.0100000000,-3.1400000000) [-3.1400000000|3.1400000000] "rad"  RLR_L,RRR_L
 SG_ FLR_Length_L : 109|9@0+ (0.0500000000,0.0000000000) [0.0000000000|25.5000000000] "m"  RLR_L,RRR_L
 SG_ FLR_Width_L : 116|11@0+ (0.0100000000,0.0000000000) [0.0000000000|12.0000000000] "m"  RLR_L,RRR_L
 SG_ FLR_TrckrNum : 121|2@0+ (1.0000000000,0.0000000000) [0.0000000000|3.0000000000] ""  RLR_L,RRR_L
 SG_ FLR_TrackerTimeStamp : 7|64@0+ (0.0001000000,0.0000000000) [0.0000000000|429496.7295000000] "s"  RLR_L,RRR_L

BO_ 1875 mADC_753: 64 mADC

BO_ 1884 RRR_L_75C: 8 RRR_L

BO_ 1876 mADC_754: 64 mADC

BO_ 1883 RLR_L_75B: 8 RLR_L

BO_ 1104 mADC_450: 8 mADC

BO_ 1108 RLR_L_454: 8 RLR_L

BO_ 1109 RRR_L_455: 8 RRR_L

BO_ 1687 RLR_L_697: 8 RLR_L
 SG_ LCDAL_DTC2_Status : 63|8@0+ (1.0000000000,0.0000000000) [0.0000000000|255.0000000000] ""  RRR_L,mADC
 SG_ LCDAL_DTC2_LowByte : 55|8@0+ (1.0000000000,0.0000000000) [0.0000000000|255.0000000000] ""  RRR_L,mADC
 SG_ LCDAL_DTC2_MiddByte : 47|8@0+ (1.0000000000,0.0000000000) [0.0000000000|255.0000000000] ""  RRR_L,mADC
 SG_ LCDAL_DTC2_HighByte : 39|8@0+ (1.0000000000,0.0000000000) [0.0000000000|255.0000000000] ""  RRR_L,mADC
 SG_ LCDAL_DTC1_Status : 31|8@0+ (1.0000000000,0.0000000000) [0.0000000000|255.0000000000] ""  RRR_L,mADC
 SG_ LCDAL_DTC1_LowByte : 23|8@0+ (1.0000000000,0.0000000000) [0.0000000000|255.0000000000] ""  RRR_L,mADC
 SG_ LCDAL_DTC1_MiddByte : 15|8@0+ (1.0000000000,0.0000000000) [0.0000000000|255.0000000000] ""  RRR_L,mADC
 SG_ LCDAL_DTC1_HighByte : 7|8@0+ (1.0000000000,0.0000000000) [0.0000000000|255.0000000000] ""  RRR_L,mADC

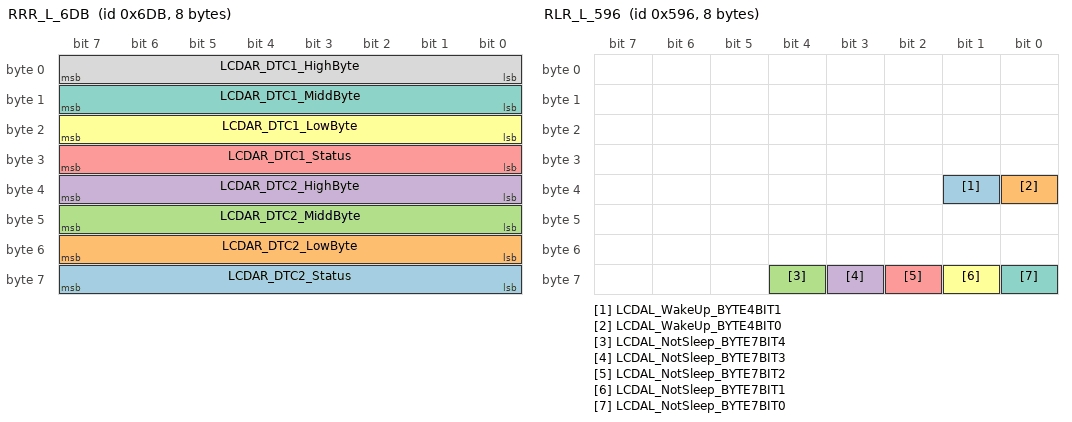
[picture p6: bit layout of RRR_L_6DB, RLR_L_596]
BO_ 1755 RRR_L_6DB: 8 RRR_L
 SG_ LCDAR_DTC2_Status : 63|8@0+ (1.0000000000,0.0000000000) [0.0000000000|255.0000000000] ""  RLR_L,mADC
 SG_ LCDAR_DTC2_LowByte : 55|8@0+ (1.0000000000,0.0000000000) [0.0000000000|255.0000000000] ""  RLR_L,mADC
 SG_ LCDAR_DTC2_MiddByte : 47|8@0+ (1.0000000000,0.0000000000) [0.0000000000|255.0000000000] ""  RLR_L,mADC
 SG_ LCDAR_DTC2_HighByte : 39|8@0+ (1.0000000000,0.0000000000) [0.0000000000|255.0000000000] ""  RLR_L,mADC
 SG_ LCDAR_DTC1_Status : 31|8@0+ (1.0000000000,0.0000000000) [0.0000000000|255.0000000000] ""  RLR_L,mADC
 SG_ LCDAR_DTC1_LowByte : 23|8@0+ (1.0000000000,0.0000000000) [0.0000000000|255.0000000000] ""  RLR_L,mADC
 SG_ LCDAR_DTC1_MiddByte : 15|8@0+ (1.0000000000,0.0000000000) [0.0000000000|255.0000000000] ""  RLR_L,mADC
 SG_ LCDAR_DTC1_HighByte : 7|8@0+ (1.0000000000,0.0000000000) [0.0000000000|255.0000000000] ""  RLR_L,mADC

BO_ 1430 RLR_L_596: 8 RLR_L
 SG_ LCDAL_WakeUp_BYTE4BIT1 : 33|1@0+ (1.0000000000,0.0000000000) [0.0000000000|1.0000000000] ""  RRR_L,mADC
 SG_ LCDAL_WakeUp_BYTE4BIT0 : 32|1@0+ (1.0000000000,0.0000000000) [0.0000000000|1.0000000000] ""  RRR_L,mADC
 SG_ LCDAL_NotSleep_BYTE7BIT4 : 60|1@0+ (1.0000000000,0.0000000000) [0.0000000000|1.0000000000] ""  RRR_L,mADC
 SG_ LCDAL_NotSleep_BYTE7BIT3 : 59|1@0+ (1.0000000000,0.0000000000) [0.0000000000|1.0000000000] ""  RRR_L,mADC
 SG_ LCDAL_NotSleep_BYTE7BIT2 : 58|1@0+ (1.0000000000,0.0000000000) [0.0000000000|1.0000000000] ""  RRR_L,mADC
 SG_ LCDAL_NotSleep_BYTE7BIT1 : 57|1@0+ (1.0000000000,0.0000000000) [0.0000000000|1.0000000000] ""  RRR_L,mADC
 SG_ LCDAL_NotSleep_BYTE7BIT0 : 56|1@0+ (1.0000000000,0.0000000000) [0.0000000000|1.0000000000] ""  RRR_L,mADC

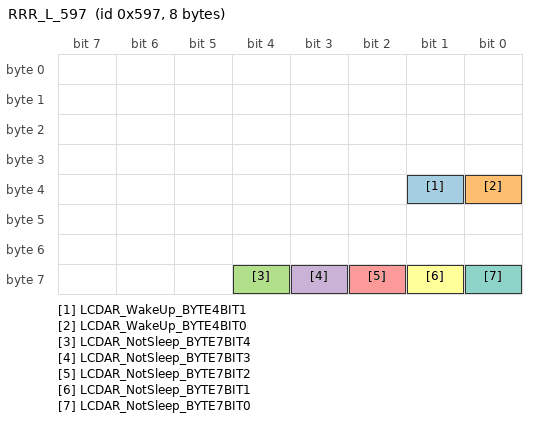
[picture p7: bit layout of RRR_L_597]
BO_ 1431 RRR_L_597: 8 RRR_L
 SG_ LCDAR_WakeUp_BYTE4BIT1 : 33|1@0+ (1.0000000000,0.0000000000) [0.0000000000|1.0000000000] ""  RLR_L,mADC
 SG_ LCDAR_WakeUp_BYTE4BIT0 : 32|1@0+ (1.0000000000,0.0000000000) [0.0000000000|1.0000000000] ""  RLR_L,mADC
 SG_ LCDAR_NotSleep_BYTE7BIT4 : 60|1@0+ (1.0000000000,0.0000000000) [0.0000000000|1.0000000000] ""  RLR_L,mADC
 SG_ LCDAR_NotSleep_BYTE7BIT3 : 59|1@0+ (1.0000000000,0.0000000000) [0.0000000000|1.0000000000] ""  RLR_L,mADC
 SG_ LCDAR_NotSleep_BYTE7BIT2 : 58|1@0+ (1.0000000000,0.0000000000) [0.0000000000|1.0000000000] ""  RLR_L,mADC
 SG_ LCDAR_NotSleep_BYTE7BIT1 : 57|1@0+ (1.0000000000,0.0000000000) [0.0000000000|1.0000000000] ""  RLR_L,mADC
 SG_ LCDAR_NotSleep_BYTE7BIT0 : 56|1@0+ (1.0000000000,0.0000000000) [0.0000000000|1.0000000000] ""  RLR_L,mADC

BO_ 698 RLR_L_2BA: 64 RLR_L
 SG_ RLR_CRCCheck_2BA : 503|16@0+ (1.0000000000,0.0000000000) [0.0000000000|65535.0000000000] ""  RRR_L,mADC
 SG_ RLR_RollingCounter_2BA : 491|4@0+ (1.0000000000,0.0000000000) [0.0000000000|15.0000000000] ""  RRR_L,mADC
 SG_ RLR_OBJ32_Ax : 333|10@0+ (0.0312500000,-16.0000000000) [-16.0000000000|15.9688000000] "m/s2"  RRR_L,mADC
 SG_ RLR_OBJ31_Ax : 327|10@0+ (0.0312500000,-16.0000000000) [-16.0000000000|15.9688000000] "m/s2"  RRR_L,mADC
 SG_ RLR_OBJ30_Ax : 309|10@0+ (0.0312500000,-16.0000000000) [-16.0000000000|15.9688000000] "m/s2"  RRR_L,mADC
 SG_ RLR_OBJ29_Ax : 303|10@0+ (0.0312500000,-16.0000000000) [-16.0000000000|15.9688000000] "m/s2"  RRR_L,mADC
 SG_ RLR_OBJ28_Ax : 281|10@0+ (0.0312500000,-16.0000000000) [-16.0000000000|15.9688000000] "m/s2"  RRR_L,mADC
 SG_ RLR_OBJ27_Ax : 275|10@0+ (0.0312500000,-16.0000000000) [-16.0000000000|15.9688000000] "m/s2"  RRR_L,mADC
 SG_ RLR_OBJ26_Ax : 269|10@0+ (0.0312500000,-16.0000000000) [-16.0000000000|15.9688000000] "m/s2"  RRR_L,mADC
 SG_ RLR_OBJ25_Ax : 263|10@0+ (0.0312500000,-16.0000000000) [-16.0000000000|15.9688000000] "m/s2"  RRR_L,mADC
 SG_ RLR_OBJ24_Ax : 245|10@0+ (0.0312500000,-16.0000000000) [-16.0000000000|15.9688000000] "m/s2"  RRR_L,mADC
 SG_ RLR_OBJ23_Ax : 239|10@0+ (0.0312500000,-16.0000000000) [-16.0000000000|15.9688000000] "m/s2"  RRR_L,mADC
 SG_ RLR_OBJ22_Ax : 217|10@0+ (0.0312500000,-16.0000000000) [-16.0000000000|15.9688000000] "m/s2"  RRR_L,mADC
 SG_ RLR_OBJ21_Ax : 211|10@0+ (0.0312500000,-16.0000000000) [-16.0000000000|15.9688000000] "m/s2"  RRR_L,mADC
 SG_ RLR_OBJ20_Ax : 205|10@0+ (0.0312500000,-16.0000000000) [-16.0000000000|15.9688000000] "m/s2"  RRR_L,mADC
 SG_ RLR_OBJ19_Ax : 199|10@0+ (0.0312500000,-16.0000000000) [-16.0000000000|15.9688000000] "m/s2"  RRR_L,mADC
 SG_ RLR_OBJ18_Ax : 181|10@0+ (0.0312500000,-16.0000000000) [-16.0000000000|15.9688000000] "m/s2"  RRR_L,mADC
 SG_ RLR_OBJ17_Ax : 175|10@0+ (0.0312500000,-16.0000000000) [-16.0000000000|15.9688000000] "m/s2"  RRR_L,mADC
 SG_ RLR_OBJ16_Ax : 153|10@0+ (0.0312500000,-16.0000000000) [-16.0000000000|15.9688000000] "m/s2"  RRR_L,mADC
 SG_ RLR_OBJ15_Ax : 147|10@0+ (0.0312500000,-16.0000000000) [-16.0000000000|15.9688000000] "m/s2"  RRR_L,mADC
 SG_ RLR_OBJ14_Ax : 141|10@0+ (0.0312500000,-16.0000000000) [-16.0000000000|15.9688000000] "m/s2"  RRR_L,mADC
 SG_ RLR_OBJ13_Ax : 135|10@0+ (0.0312500000,-16.0000000000) [-16.0000000000|15.9688000000] "m/s2"  RRR_L,mADC
 SG_ RLR_OBJ12_Ax : 117|10@0+ (0.0312500000,-16.0000000000) [-16.0000000000|15.9688000000] "m/s2"  RRR_L,mADC
 SG_ RLR_OBJ11_Ax : 111|10@0+ (0.0312500000,-16.0000000000) [-16.0000000000|15.9688000000] "m/s2"  RRR_L,mADC
 SG_ RLR_OBJ10_Ax : 89|10@0+ (0.0312500000,-16.0000000000) [-16.0000000000|15.9688000000] "m/s2"  RRR_L,mADC
 SG_ RLR_OBJ9_Ax : 83|10@0+ (0.0312500000,-16.0000000000) [-16.0000000000|15.9688000000] "m/s2"  RRR_L,mADC
 SG_ RLR_OBJ8_Ax : 77|10@0+ (0.0312500000,-16.0000000000) [-16.0000000000|15.9688000000] "m/s2"  RRR_L,mADC
 SG_ RLR_OBJ7_Ax : 71|10@0+ (0.0312500000,-16.0000000000) [-16.0000000000|15.9688000000] "m/s2"  RRR_L,mADC
 SG_ RLR_OBJ6_Ax : 53|10@0+ (0.0312500000,-16.0000000000) [-16.0000000000|15.9688000000] "m/s2"  RRR_L,mADC
 SG_ RLR_OBJ5_Ax : 47|10@0+ (0.0312500000,-16.0000000000) [-16.0000000000|15.9688000000] "m/s2"  RRR_L,mADC
 SG_ RLR_OBJ4_Ax : 25|10@0+ (0.0312500000,-16.0000000000) [-16.0000000000|15.9688000000] "m/s2"  RRR_L,mADC
 SG_ RLR_OBJ3_Ax : 19|10@0+ (0.0312500000,-16.0000000000) [-16.0000000000|15.9688000000] "m/s2"  RRR_L,mADC
 SG_ RLR_OBJ2_Ax : 13|10@0+ (0.0312500000,-16.0000000000) [-16.0000000000|15.9688000000] "m/s2"  RRR_L,mADC
 SG_ RLR_OBJ1_Ax : 7|10@0+ (0.0312500000,-16.0000000000) [-16.0000000000|15.9688000000] "m/s2"  RRR_L,mADC

BO_ 957 mADC_3BD: 64 mADC
 SG_ HU_AsistantSysteSwitch : 365|2@0+ (1.0000000000,0.0000000000) [0.0000000000|2.0000000000] ""  RLR_L,RRR_L

CM_ BO_ 924  " ";
CM_ SG_ 924 RLR_CRCCheck_39C  " ";
CM_ SG_ 924 RLR_RollingCounter_39C  " ";
CM_ SG_ 924 RLR_FreespaceSectorKinestate102  " ";
CM_ SG_ 924 RLR_FreespaceSectorConRidence102  " ";
CM_ SG_ 924 RLR_FreespaceSectorDistance102  " ";
CM_ SG_ 924 RLR_FreespaceSectorKinestate101  " ";
CM_ SG_ 924 RLR_FreespaceSectorConRidence101  " ";
CM_ SG_ 924 RLR_FreespaceSectorDistance101  " ";
CM_ SG_ 924 RLR_FreespaceSectorKinestate100  " ";
CM_ SG_ 924 RLR_FreespaceSectorConRidence100  " ";
CM_ SG_ 924 RLR_FreespaceSectorDistance100  " ";
CM_ SG_ 924 RLR_FreespaceSectorKinestate99  " ";
CM_ SG_ 924 RLR_FreespaceSectorConRidence99  " ";
CM_ SG_ 924 RLR_FreespaceSectorDistance99  " ";
CM_ SG_ 924 RLR_FreespaceSectorKinestate98  " ";
CM_ SG_ 924 RLR_FreespaceSectorConRidence98  " ";
CM_ SG_ 924 RLR_FreespaceSectorDistance98  " ";
CM_ SG_ 924 RLR_FreespaceSectorKinestate97  " ";
CM_ SG_ 924 RLR_FreespaceSectorConRidence97  " ";
CM_ SG_ 924 RLR_FreespaceSectorDistance97  " ";
CM_ SG_ 924 RLR_FreespaceSectorKinestate96  " ";
CM_ SG_ 924 RLR_FreespaceSectorConRidence96  " ";
CM_ SG_ 924 RLR_FreespaceSectorDistance96  " ";
CM_ SG_ 924 RLR_FreespaceSectorKinestate95  " ";
CM_ SG_ 924 RLR_FreespaceSectorConRidence95  " ";
CM_ SG_ 924 RLR_FreespaceSectorDistance95  " ";
CM_ SG_ 924 RLR_FreespaceSectorKinestate94  " ";
CM_ SG_ 924 RLR_FreespaceSectorConRidence94  " ";
CM_ SG_ 924 RLR_FreespaceSectorDistance94  " ";
CM_ SG_ 924 RLR_FreespaceSectorKinestate93  " ";
CM_ SG_ 924 RLR_FreespaceSectorConRidence93  " ";
CM_ SG_ 924 RLR_FreespaceSectorDistance93  " ";
CM_ SG_ 924 RLR_FreespaceSectorKinestate92  " ";
CM_ SG_ 924 RLR_FreespaceSectorConRidence92  " ";
CM_ SG_ 924 RLR_FreespaceSectorDistance92  " ";
CM_ SG_ 924 RLR_FreespaceSectorKinestate91  " ";
CM_ SG_ 924 RLR_FreespaceSectorConRidence91  " ";
CM_ SG_ 924 RLR_FreespaceSectorDistance91  " ";
CM_ SG_ 924 RLR_FreespaceSectorKinestate90  " ";
CM_ SG_ 924 RLR_FreespaceSectorConRidence90  " ";
CM_ SG_ 924 RLR_FreespaceSectorDistance90  " ";
CM_ SG_ 924 RLR_FreespaceSectorKinestate89  " ";
CM_ SG_ 924 RLR_FreespaceSectorConRidence89  " ";
CM_ SG_ 924 RLR_FreespaceSectorDistance89  " ";
CM_ SG_ 924 RLR_FreespaceSectorKinestate88  " ";
CM_ SG_ 924 RLR_FreespaceSectorConRidence88  " ";
CM_ SG_ 924 RLR_FreespaceSectorDistance88  " ";
CM_ SG_ 924 RLR_FreespaceSectorKinestate87  " ";
CM_ SG_ 924 RLR_FreespaceSectorConRidence87  " ";
CM_ SG_ 924 RLR_FreespaceSectorDistance87  " ";
CM_ SG_ 924 RLR_FreespaceSectorKinestate86  " ";
CM_ SG_ 924 RLR_FreespaceSectorConRidence86  " ";
CM_ SG_ 924 RLR_FreespaceSectorDistance86  " ";
CM_ SG_ 924 RLR_FreespaceSectorKinestate85  " ";
CM_ SG_ 924 RLR_FreespaceSectorConRidence85  " ";
CM_ SG_ 924 RLR_FreespaceSectorDistance85  " ";
CM_ SG_ 924 RLR_FreespaceSectorKinestate84  " ";
CM_ SG_ 924 RLR_FreespaceSectorConRidence84  " ";
CM_ SG_ 924 RLR_FreespaceSectorDistance84  " ";
CM_ SG_ 924 RLR_FreespaceSectorKinestate83  " ";
CM_ SG_ 924 RLR_FreespaceSectorConRidence83  " ";
CM_ SG_ 924 RLR_FreespaceSectorDistance83  " ";
CM_ SG_ 924 RLR_FreespaceSectorKinestate82  " ";
CM_ SG_ 924 RLR_FreespaceSectorConRidence82  " ";
CM_ SG_ 924 RLR_FreespaceSectorDistance82  " ";
CM_ SG_ 924 RLR_FreespaceSectorKinestate81  " ";
CM_ SG_ 924 RLR_FreespaceSectorConRidence81  " ";
CM_ SG_ 924 RLR_FreespaceSectorDistance81  " ";
CM_ SG_ 924 RLR_FreespaceSectorKinestate80  " ";
CM_ SG_ 924 RLR_FreespaceSectorConRidence80  " ";
CM_ SG_ 924 RLR_FreespaceSectorDistance80  " ";
CM_ SG_ 924 RLR_FreespaceSectorKinestate79  " ";
CM_ SG_ 924 RLR_FreespaceSectorConRidence79  " ";
CM_ SG_ 924 RLR_FreespaceSectorDistance79  " ";
CM_ SG_ 924 RLR_FreespaceSectorKinestate78  " ";
CM_ SG_ 924 RLR_FreespaceSectorConRidence78  " ";
CM_ SG_ 924 RLR_FreespaceSectorDistance78  " ";
CM_ SG_ 924 RLR_FreespaceSectorKinestate77  " ";
CM_ SG_ 924 RLR_FreespaceSectorConRidence77  " ";
CM_ SG_ 924 RLR_FreespaceSectorDistance77  " ";
CM_ SG_ 924 RLR_FreespaceSectorKinestate76  " ";
CM_ SG_ 924 RLR_FreespaceSectorConRidence76  " ";
CM_ SG_ 924 RLR_FreespaceSectorDistance76  " ";
CM_ SG_ 924 RLR_FreespaceSectorKinestate75  " ";
CM_ SG_ 924 RLR_FreespaceSectorConRidence75  " ";
CM_ SG_ 924 RLR_FreespaceSectorDistance75  " ";
CM_ SG_ 924 RLR_FreespaceSectorKinestate74  " ";
CM_ SG_ 924 RLR_FreespaceSectorConRidence74  " ";
CM_ SG_ 924 RLR_FreespaceSectorDistance74  " ";
CM_ SG_ 924 RLR_FreespaceSectorKinestate73  " ";
CM_ SG_ 924 RLR_FreespaceSectorConRidence73  " ";
CM_ SG_ 924 RLR_FreespaceSectorDistance73  " ";
CM_ SG_ 924 RLR_FreespaceSectorKinestate72  " ";
CM_ SG_ 924 RLR_FreespaceSectorConRidence72  " ";
CM_ SG_ 924 RLR_FreespaceSectorDistance72  " ";
CM_ SG_ 924 RLR_FreespaceSectorKinestate71  " ";
CM_ SG_ 924 RLR_FreespaceSectorConRidence71  " ";
CM_ SG_ 924 RLR_FreespaceSectorDistance71  " ";
CM_ SG_ 924 RLR_FreespaceSectorKinestate70  " ";
CM_ SG_ 924 RLR_FreespaceSectorConRidence70  " ";
CM_ SG_ 924 RLR_FreespaceSectorDistance70  " ";
CM_ SG_ 924 RLR_FreespaceSectorKinestate69  " ";
CM_ SG_ 924 RLR_FreespaceSectorConRidence69  " ";
CM_ SG_ 924 RLR_FreespaceSectorDistance69  " ";

CM_ BO_ 925  " ";
CM_ SG_ 925 RLR_CRCCheck_39D  " ";
CM_ SG_ 925 RLR_RollingCounter_39D  " ";
CM_ SG_ 925 RLR_FreespaceSectorKinestate136  " ";
CM_ SG_ 925 RLR_FreespaceSectorConRidence136  " ";
CM_ SG_ 925 RLR_FreespaceSectorDistance136  " ";
CM_ SG_ 925 RLR_FreespaceSectorKinestate135  " ";
CM_ SG_ 925 RLR_FreespaceSectorConRidence135  " ";
CM_ SG_ 925 RLR_FreespaceSectorDistance135  " ";
CM_ SG_ 925 RLR_FreespaceSectorKinestate134  " ";
CM_ SG_ 925 RLR_FreespaceSectorConRidence134  " ";
CM_ SG_ 925 RLR_FreespaceSectorDistance134  " ";
CM_ SG_ 925 RLR_FreespaceSectorKinestate133  " ";
CM_ SG_ 925 RLR_FreespaceSectorConRidence133  " ";
CM_ SG_ 925 RLR_FreespaceSectorDistance133  " ";
CM_ SG_ 925 RLR_FreespaceSectorKinestate132  " ";
CM_ SG_ 925 RLR_FreespaceSectorConRidence132  " ";
CM_ SG_ 925 RLR_FreespaceSectorDistance132  " ";
CM_ SG_ 925 RLR_FreespaceSectorKinestate131  " ";
CM_ SG_ 925 RLR_FreespaceSectorConRidence131  " ";
CM_ SG_ 925 RLR_FreespaceSectorDistance131  " ";
CM_ SG_ 925 RLR_FreespaceSectorKinestate130  " ";
CM_ SG_ 925 RLR_FreespaceSectorConRidence130  " ";
CM_ SG_ 925 RLR_FreespaceSectorDistance130  " ";
CM_ SG_ 925 RLR_FreespaceSectorKinestate129  " ";
CM_ SG_ 925 RLR_FreespaceSectorConRidence129  " ";
CM_ SG_ 925 RLR_FreespaceSectorDistance129  " ";
CM_ SG_ 925 RLR_FreespaceSectorKinestate128  " ";
CM_ SG_ 925 RLR_FreespaceSectorConRidence128  " ";
CM_ SG_ 925 RLR_FreespaceSectorDistance128  " ";
CM_ SG_ 925 RLR_FreespaceSectorKinestate127  " ";
CM_ SG_ 925 RLR_FreespaceSectorConRidence127  " ";
CM_ SG_ 925 RLR_FreespaceSectorDistance127  " ";
CM_ SG_ 925 RLR_FreespaceSectorKinestate126  " ";
CM_ SG_ 925 RLR_FreespaceSectorConRidence126  " ";
CM_ SG_ 925 RLR_FreespaceSectorDistance126  " ";
CM_ SG_ 925 RLR_FreespaceSectorKinestate125  " ";
CM_ SG_ 925 RLR_FreespaceSectorConRidence125  " ";
CM_ SG_ 925 RLR_FreespaceSectorDistance125  " ";
CM_ SG_ 925 RLR_FreespaceSectorKinestate124  " ";
CM_ SG_ 925 RLR_FreespaceSectorConRidence124  " ";
CM_ SG_ 925 RLR_FreespaceSectorDistance124  " ";
CM_ SG_ 925 RLR_FreespaceSectorKinestate123  " ";
CM_ SG_ 925 RLR_FreespaceSectorConRidence123  " ";
CM_ SG_ 925 RLR_FreespaceSectorDistance123  " ";
CM_ SG_ 925 RLR_FreespaceSectorKinestate122  " ";
CM_ SG_ 925 RLR_FreespaceSectorConRidence122  " ";
CM_ SG_ 925 RLR_FreespaceSectorDistance122  " ";
CM_ SG_ 925 RLR_FreespaceSectorKinestate121  " ";
CM_ SG_ 925 RLR_FreespaceSectorConRidence121  " ";
CM_ SG_ 925 RLR_FreespaceSectorDistance121  " ";
CM_ SG_ 925 RLR_FreespaceSectorKinestate120  " ";
CM_ SG_ 925 RLR_FreespaceSectorConRidence120  " ";
CM_ SG_ 925 RLR_FreespaceSectorDistance120  " ";
CM_ SG_ 925 RLR_FreespaceSectorKinestate119  " ";
CM_ SG_ 925 RLR_FreespaceSectorConRidence119  " ";
CM_ SG_ 925 RLR_FreespaceSectorDistance119  " ";
CM_ SG_ 925 RLR_FreespaceSectorKinestate118  " ";
CM_ SG_ 925 RLR_FreespaceSectorConRidence118  " ";
CM_ SG_ 925 RLR_FreespaceSectorDistance118  " ";
CM_ SG_ 925 RLR_FreespaceSectorKinestate117  " ";
CM_ SG_ 925 RLR_FreespaceSectorConRidence117  " ";
CM_ SG_ 925 RLR_FreespaceSectorDistance117  " ";
CM_ SG_ 925 RLR_FreespaceSectorKinestate116  " ";
CM_ SG_ 925 RLR_FreespaceSectorConRidence116  " ";
CM_ SG_ 925 RLR_FreespaceSectorDistance116  " ";
CM_ SG_ 925 RLR_FreespaceSectorKinestate115  " ";
CM_ SG_ 925 RLR_FreespaceSectorConRidence115  " ";
CM_ SG_ 925 RLR_FreespaceSectorDistance115  " ";
CM_ SG_ 925 RLR_FreespaceSectorKinestate114  " ";
CM_ SG_ 925 RLR_FreespaceSectorConRidence114  " ";
CM_ SG_ 925 RLR_FreespaceSectorDistance114  " ";
CM_ SG_ 925 RLR_FreespaceSectorKinestate113  " ";
CM_ SG_ 925 RLR_FreespaceSectorConRidence113  " ";
CM_ SG_ 925 RLR_FreespaceSectorDistance113  " ";
CM_ SG_ 925 RLR_FreespaceSectorKinestate112  " ";
CM_ SG_ 925 RLR_FreespaceSectorConRidence112  " ";
CM_ SG_ 925 RLR_FreespaceSectorDistance112  " ";
CM_ SG_ 925 RLR_FreespaceSectorKinestate111  " ";
CM_ SG_ 925 RLR_FreespaceSectorConRidence111  " ";
CM_ SG_ 925 RLR_FreespaceSectorDistance111  " ";
CM_ SG_ 925 RLR_FreespaceSectorKinestate110  " ";
CM_ SG_ 925 RLR_FreespaceSectorConRidence110  " ";
CM_ SG_ 925 RLR_FreespaceSectorDistance110  " ";
CM_ SG_ 925 RLR_FreespaceSectorKinestate109  " ";
CM_ SG_ 925 RLR_FreespaceSectorConRidence109  " ";
CM_ SG_ 925 RLR_FreespaceSectorDistance109  " ";
CM_ SG_ 925 RLR_FreespaceSectorKinestate108  " ";
CM_ SG_ 925 RLR_FreespaceSectorConRidence108  " ";
CM_ SG_ 925 RLR_FreespaceSectorDistance108  " ";
CM_ SG_ 925 RLR_FreespaceSectorKinestate107  " ";
CM_ SG_ 925 RLR_FreespaceSectorConRidence107  " ";
CM_ SG_ 925 RLR_FreespaceSectorDistance107  " ";
CM_ SG_ 925 RLR_FreespaceSectorKinestate106  " ";
CM_ SG_ 925 RLR_FreespaceSectorConRidence106  " ";
CM_ SG_ 925 RLR_FreespaceSectorDistance106  " ";
CM_ SG_ 925 RLR_FreespaceSectorKinestate105  " ";
CM_ SG_ 925 RLR_FreespaceSectorConRidence105  " ";
CM_ SG_ 925 RLR_FreespaceSectorDistance105  " ";
CM_ SG_ 925 RLR_FreespaceSectorKinestate104  " ";
CM_ SG_ 925 RLR_FreespaceSectorConRidence104  " ";
CM_ SG_ 925 RLR_FreespaceSectorDistance104  " ";
CM_ SG_ 925 RLR_FreespaceSectorKinestate103  " ";
CM_ SG_ 925 RLR_FreespaceSectorConRidence103  " ";
CM_ SG_ 925 RLR_FreespaceSectorDistance103  " ";

CM_ BO_ 926  " ";
CM_ SG_ 926 RLR_CRCCheck_39E  " ";
CM_ SG_ 926 RLR_RollingCounter_39E  " ";
CM_ SG_ 926 RLR_FreespaceSectorKinestate170  " ";
CM_ SG_ 926 RLR_FreespaceSectorConRidence170  " ";
CM_ SG_ 926 RLR_FreespaceSectorDistance170  " ";
CM_ SG_ 926 RLR_FreespaceSectorKinestate169  " ";
CM_ SG_ 926 RLR_FreespaceSectorConRidence169  " ";
CM_ SG_ 926 RLR_FreespaceSectorDistance169  " ";
CM_ SG_ 926 RLR_FreespaceSectorKinestate168  " ";
CM_ SG_ 926 RLR_FreespaceSectorConRidence168  " ";
CM_ SG_ 926 RLR_FreespaceSectorDistance168  " ";
CM_ SG_ 926 RLR_FreespaceSectorKinestate167  " ";
CM_ SG_ 926 RLR_FreespaceSectorConRidence167  " ";
CM_ SG_ 926 RLR_FreespaceSectorDistance167  " ";
CM_ SG_ 926 RLR_FreespaceSectorKinestate166  " ";
CM_ SG_ 926 RLR_FreespaceSectorConRidence166  " ";
CM_ SG_ 926 RLR_FreespaceSectorDistance166  " ";
CM_ SG_ 926 RLR_FreespaceSectorKinestate165  " ";
CM_ SG_ 926 RLR_FreespaceSectorConRidence165  " ";
CM_ SG_ 926 RLR_FreespaceSectorDistance165  " ";
CM_ SG_ 926 RLR_FreespaceSectorKinestate164  " ";
CM_ SG_ 926 RLR_FreespaceSectorConRidence164  " ";
CM_ SG_ 926 RLR_FreespaceSectorDistance164  " ";
CM_ SG_ 926 RLR_FreespaceSectorKinestate163  " ";
CM_ SG_ 926 RLR_FreespaceSectorConRidence163  " ";
CM_ SG_ 926 RLR_FreespaceSectorDistance163  " ";
CM_ SG_ 926 RLR_FreespaceSectorKinestate162  " ";
CM_ SG_ 926 RLR_FreespaceSectorConRidence162  " ";
CM_ SG_ 926 RLR_FreespaceSectorDistance162  " ";
CM_ SG_ 926 RLR_FreespaceSectorKinestate161  " ";
CM_ SG_ 926 RLR_FreespaceSectorConRidence161  " ";
CM_ SG_ 926 RLR_FreespaceSectorDistance161  " ";
CM_ SG_ 926 RLR_FreespaceSectorKinestate160  " ";
CM_ SG_ 926 RLR_FreespaceSectorConRidence160  " ";
CM_ SG_ 926 RLR_FreespaceSectorDistance160  " ";
CM_ SG_ 926 RLR_FreespaceSectorKinestate159  " ";
CM_ SG_ 926 RLR_FreespaceSectorConRidence159  " ";
CM_ SG_ 926 RLR_FreespaceSectorDistance159  " ";
CM_ SG_ 926 RLR_FreespaceSectorKinestate158  " ";
CM_ SG_ 926 RLR_FreespaceSectorConRidence158  " ";
CM_ SG_ 926 RLR_FreespaceSectorDistance158  " ";
CM_ SG_ 926 RLR_FreespaceSectorKinestate157  " ";
CM_ SG_ 926 RLR_FreespaceSectorConRidence157  " ";
CM_ SG_ 926 RLR_FreespaceSectorDistance157  " ";
CM_ SG_ 926 RLR_FreespaceSectorKinestate156  " ";
CM_ SG_ 926 RLR_FreespaceSectorConRidence156  " ";
CM_ SG_ 926 RLR_FreespaceSectorDistance156  " ";
CM_ SG_ 926 RLR_FreespaceSectorKinestate155  " ";
CM_ SG_ 926 RLR_FreespaceSectorConRidence155  " ";
CM_ SG_ 926 RLR_FreespaceSectorDistance155  " ";
CM_ SG_ 926 RLR_FreespaceSectorKinestate154  " ";
CM_ SG_ 926 RLR_FreespaceSectorConRidence154  " ";
CM_ SG_ 926 RLR_FreespaceSectorDistance154  " ";
CM_ SG_ 926 RLR_FreespaceSectorKinestate153  " ";
CM_ SG_ 926 RLR_FreespaceSectorConRidence153  " ";
CM_ SG_ 926 RLR_FreespaceSectorDistance153  " ";
CM_ SG_ 926 RLR_FreespaceSectorKinestate152  " ";
CM_ SG_ 926 RLR_FreespaceSectorConRidence152  " ";
CM_ SG_ 926 RLR_FreespaceSectorDistance152  " ";
CM_ SG_ 926 RLR_FreespaceSectorKinestate151  " ";
CM_ SG_ 926 RLR_FreespaceSectorConRidence151  " ";
CM_ SG_ 926 RLR_FreespaceSectorDistance151  " ";
CM_ SG_ 926 RLR_FreespaceSectorKinestate150  " ";
CM_ SG_ 926 RLR_FreespaceSectorConRidence150  " ";
CM_ SG_ 926 RLR_FreespaceSectorDistance150  " ";
CM_ SG_ 926 RLR_FreespaceSectorKinestate149  " ";
CM_ SG_ 926 RLR_FreespaceSectorConRidence149  " ";
CM_ SG_ 926 RLR_FreespaceSectorDistance149  " ";
CM_ SG_ 926 RLR_FreespaceSectorKinestate148  " ";
CM_ SG_ 926 RLR_FreespaceSectorConRidence148  " ";
CM_ SG_ 926 RLR_FreespaceSectorDistance148  " ";
CM_ SG_ 926 RLR_FreespaceSectorKinestate147  " ";
CM_ SG_ 926 RLR_FreespaceSectorConRidence147  " ";
CM_ SG_ 926 RLR_FreespaceSectorDistance147  " ";
CM_ SG_ 926 RLR_FreespaceSectorKinestate146  " ";
CM_ SG_ 926 RLR_FreespaceSectorConRidence146  " ";
CM_ SG_ 926 RLR_FreespaceSectorDistance146  " ";
CM_ SG_ 926 RLR_FreespaceSectorKinestate145  " ";
CM_ SG_ 926 RLR_FreespaceSectorConRidence145  " ";
CM_ SG_ 926 RLR_FreespaceSectorDistance145  " ";
CM_ SG_ 926 RLR_FreespaceSectorKinestate144  " ";
CM_ SG_ 926 RLR_FreespaceSectorConRidence144  " ";
CM_ SG_ 926 RLR_FreespaceSectorDistance144  " ";
CM_ SG_ 926 RLR_FreespaceSectorKinestate143  " ";
CM_ SG_ 926 RLR_FreespaceSectorConRidence143  " ";
CM_ SG_ 926 RLR_FreespaceSectorDistance143  " ";
CM_ SG_ 926 RLR_FreespaceSectorKinestate142  " ";
CM_ SG_ 926 RLR_FreespaceSectorConRidence142  " ";
CM_ SG_ 926 RLR_FreespaceSectorDistance142  " ";
CM_ SG_ 926 RLR_FreespaceSectorKinestate141  " ";
CM_ SG_ 926 RLR_FreespaceSectorConRidence141  " ";
CM_ SG_ 926 RLR_FreespaceSectorDistance141  " ";
CM_ SG_ 926 RLR_FreespaceSectorKinestate140  " ";
CM_ SG_ 926 RLR_FreespaceSectorConRidence140  " ";
CM_ SG_ 926 RLR_FreespaceSectorDistance140  " ";
CM_ SG_ 926 RLR_FreespaceSectorKinestate139  " ";
CM_ SG_ 926 RLR_FreespaceSectorConRidence139  " ";
CM_ SG_ 926 RLR_FreespaceSectorDistance139  " ";
CM_ SG_ 926 RLR_FreespaceSectorKinestate138  " ";
CM_ SG_ 926 RLR_FreespaceSectorConRidence138  " ";
CM_ SG_ 926 RLR_FreespaceSectorDistance138  " ";
CM_ SG_ 926 RLR_FreespaceSectorKinestate137  " ";
CM_ SG_ 926 RLR_FreespaceSectorConRidence137  " ";
CM_ SG_ 926 RLR_FreespaceSectorDistance137  " ";

CM_ BO_ 927  " ";
CM_ SG_ 927 RLR_CRCCheck_39F  " ";
CM_ SG_ 927 RLR_RollingCounter_39F  " ";
CM_ SG_ 927 RLR_FreespaceSectorKinestate180  " ";
CM_ SG_ 927 RLR_FreespaceSectorConRidence180  " ";
CM_ SG_ 927 RLR_FreespaceSectorDistance180  " ";
CM_ SG_ 927 RLR_FreespaceSectorKinestate179  " ";
CM_ SG_ 927 RLR_FreespaceSectorConRidence179  " ";
CM_ SG_ 927 RLR_FreespaceSectorDistance179  " ";
CM_ SG_ 927 RLR_FreespaceSectorKinestate178  " ";
CM_ SG_ 927 RLR_FreespaceSectorConRidence178  " ";
CM_ SG_ 927 RLR_FreespaceSectorDistance178  " ";
CM_ SG_ 927 RLR_FreespaceSectorKinestate177  " ";
CM_ SG_ 927 RLR_FreespaceSectorConRidence177  " ";
CM_ SG_ 927 RLR_FreespaceSectorDistance177  " ";
CM_ SG_ 927 RLR_FreespaceSectorKinestate176  " ";
CM_ SG_ 927 RLR_FreespaceSectorConRidence176  " ";
CM_ SG_ 927 RLR_FreespaceSectorDistance176  " ";
CM_ SG_ 927 RLR_FreespaceSectorKinestate175  " ";
CM_ SG_ 927 RLR_FreespaceSectorConRidence175  " ";
CM_ SG_ 927 RLR_FreespaceSectorDistance175  " ";
CM_ SG_ 927 RLR_FreespaceSectorKinestate174  " ";
CM_ SG_ 927 RLR_FreespaceSectorConRidence174  " ";
CM_ SG_ 927 RLR_FreespaceSectorDistance174  " ";
CM_ SG_ 927 RLR_FreespaceSectorKinestate173  " ";
CM_ SG_ 927 RLR_FreespaceSectorConRidence173  " ";
CM_ SG_ 927 RLR_FreespaceSectorDistance173  " ";
CM_ SG_ 927 RLR_FreespaceSectorKinestate172  " ";
CM_ SG_ 927 RLR_FreespaceSectorConRidence172  " ";
CM_ SG_ 927 RLR_FreespaceSectorDistance172  " ";
CM_ SG_ 927 RLR_FreespaceSectorKinestate171  " ";
CM_ SG_ 927 RLR_FreespaceSectorConRidence171  " ";
CM_ SG_ 927 RLR_FreespaceSectorDistance171  " ";

CM_ BO_ 693  " ";
CM_ SG_ 693 RLR_CRCCheck_2B5  " ";
CM_ SG_ 693 RLR_RollingCounter_2B5  " ";
CM_ SG_ 693 FuncDegradeType_RR  " ";
CM_ SG_ 693 FUSION_TimeoutCnt_RR  " ";
CM_ SG_ 693 VALIDATION_TimeoutCnt_RR  " ";
CM_ SG_ 693 CurFrameCycle_RR  " ";
CM_ SG_ 693 ProcessTimeoutCnt_RR  " ";
CM_ SG_ 693 RevFrameCnt_RR  " ";
CM_ SG_ 693 Local_Pointcloud_Number_RR  " ";
CM_ SG_ 693 RealTimeCal_PrcssBar_RR  " ";
CM_ SG_ 693 RealTimeCal_VelErrOutput_RR  " ";
CM_ SG_ 693 RealTimeCal_HoriMntErrOutput_RR  " ";
CM_ SG_ 693 RealTimeCal_FailReasonCode_RR  " ";
CM_ SG_ 693 RealTimeCal_Status_RR  " ";
CM_ SG_ 693 DiagCal_PrcssBar_RR  " ";
CM_ SG_ 693 DiagCal_VelErrOutput_RR  " ";
CM_ SG_ 693 DiagCal_HoriMntErrOutput_RR  " ";
CM_ SG_ 693 DiagCal_FailReasonCode_RR  " ";
CM_ SG_ 693 DiagCal_Status_RR  " ";
CM_ SG_ 693 EolCal_PrcssBar_RR  " ";
CM_ SG_ 693 EolCal_VelErrOutput_RR  " ";
CM_ SG_ 693 EolCal_HoriMntErrOutput_RR  " ";
CM_ SG_ 693 EolCal_FailReasonCode_RR  " ";
CM_ SG_ 693 EolCal_Status_RR  " ";
CM_ SG_ 693 PriCounter_RR  " ";
CM_ SG_ 693 MsgCounter_RR  " ";

CM_ BO_ 338  " ";
CM_ SG_ 338 ADR_TriggerEventReq  " ";
CM_ SG_ 338 ADC_SenceMode  " ";

CM_ BO_ 936  " ";
CM_ SG_ 936 AD_SYNC_Sync_Time  " ";
CM_ SG_ 936 AD_SYNC_UserByte_OVS_SGW  " ";
CM_ SG_ 936 AD_SYNC_TimeDomain  " ";
CM_ SG_ 936 AD_SYNC_Sequence  " ";
CM_ SG_ 936 AD_SYNC_CRC  " ";
CM_ SG_ 936 AD_SYNC_Type  " ";

CM_ BO_ 384  " ";
CM_ SG_ 384 SAS_SteeringAngle  "APA配置接收方无BDC ";

CM_ BO_ 800  " ";
CM_ SG_ 800 GW_ResetReq  " ";
CM_ SG_ 800 GW_OTAmode_Chks  "与GW_OTAmode分配到一个ID的相邻字节 ";
CM_ SG_ 800 GW_OTAmode_Cntr  "与GW_OTAmode分配到1个字节 ";
CM_ SG_ 800 GW_OTAmode  "与GW_OTAmode_Cntr分配到1个字节 ";

CM_ BO_ 1302  " ";

CM_ BO_ 349  " ";
CM_ SG_ 349 ESP_CRCCheck_278  " ";
CM_ SG_ 349 ESP_RollingCounter_278  " ";
CM_ SG_ 349 ESP_Calibrated  " ";
CM_ SG_ 349 ESP_YawRateValid  " ";
CM_ SG_ 349 ESP_YawRate  " ";
CM_ SG_ 349 ESP_LongAccelValid  " ";
CM_ SG_ 349 ESP_LongAccel  " ";
CM_ SG_ 349 ESP_LatAccelValid  " ";
CM_ SG_ 349 ESP_LatAccel  " ";

CM_ BO_ 632  " ";
CM_ SG_ 632 ESP_YawRate  "右正左负（举例理解=水平路面向
右转弯时，发正值。反之发负值） ";
CM_ SG_ 632 ESP_LongAccel  "举例理解=水平路面直线加速
时，发正值。反之发负值。 ";
CM_ SG_ 632 ESP_LatAccel  "右正左负（举例理解=水平路面向
右转弯时，发正值。反之发负值） ";

CM_ BO_ 378  " ";
CM_ SG_ 378 ESP_ESPActiveStatus  "TCU接收为DCT专用 ";
CM_ SG_ 378 ESP_VehicleSpeedValid  "TCU接收为DCT专用 ";
CM_ SG_ 378 ESP_VehicleSpeed  "TCU接收为DCT专用 ";

CM_ BO_ 523  " ";
CM_ SG_ 523 ESP_PrefillAvailable  "ACC 主控则ACC接收，LAS 主控则LAS接收 ";
CM_ SG_ 523 ESP_PrefillActive  "ACC 主控则ACC接收，LAS 主控则LAS接收 ";
CM_ SG_ 523 ESP_BrakeForce  "APA配置接收方无BDC ";
CM_ SG_ 523 ESP_AEBdecActive  "ACC 主控则ACC接收，LAS 主控则LAS接收 ";
CM_ SG_ 523 ESP_AEBAvailable  "ACC 主控则ACC接收，LAS 主控则LAS接收 ";
CM_ SG_ 523 Wheel_Speed_RR_Pulse  "All4wheelpulsesignalsaresentbyABSwithoutfiltering.Theriseedgeandfalledgearebothcountedinit,thewheelpulsemustbesequentialintheway0,1,2…254,0,1… ";
CM_ SG_ 523 Wheel_Speed_RR_Direction  "APA配置接收方无BDC ";
CM_ SG_ 523 Wheel_Speed_RR_Data  "APA配置接收方无BDC ";
CM_ SG_ 523 Wheel_Speed_RL_Pulse  "All4wheelpulsesignalsaresentbyABSwithoutfiltering.Theriseedgeandfalledgearebothcountedinit,thewheelpulsemustbesequentialintheway0,1,2…254,0,2… ";
CM_ SG_ 523 Wheel_Speed_RL_Direction  "APA配置接收方无BDC ";
CM_ SG_ 523 Wheel_Speed_RL_Data  "APA配置接收方无BDC ";
CM_ SG_ 523 Wheel_Speed_FR_Pulse  "All4wheelpulsesignalsaresentbyABSwithoutfiltering.Theriseedgeandfalledgearebothcountedinit,thewheelpulsemustbesequentialintheway0,1,2…254,0,3… ";
CM_ SG_ 523 Wheel_Speed_FR_Direction  "APA配置接收方无BDC ";
CM_ SG_ 523 Wheel_Speed_FR_Data  "APA配置接收方无BDC ";
CM_ SG_ 523 Wheel_Speed_FL_Pulse  "All4wheelpulsesignalsaresentbyABSwithoutfiltering.Theriseedgeandfalledgearebothcountedinit,thewheelpulsemustbesequentialintheway0,1,2…254,0,4… ";
CM_ SG_ 523 Wheel_Speed_FL_Direction  "APA配置接收方无BDC ";
CM_ SG_ 523 Wheel_Speed_FL_Data  "APA配置接收方无BDC ";
CM_ SG_ 523 ESP_VehicleStandstillVld  " ";
CM_ SG_ 523 ESP_VehicleStandstill  "APA配置接收方无BDC ";

CM_ BO_ 271  " ";

CM_ BO_ 381  " ";
CM_ SG_ 381 PCU_RealAccPedlVld  "ACC 主控则ACC接收，LAS 主控则LAS接收 ";
CM_ SG_ 381 PCU_RealAccPedl  "APA配置接收方无BDC ";

CM_ BO_ 398  " ";
CM_ SG_ 398 EMS_BrakePedalStatus  "表示驾驶员踩下制动踏板的真实状态
ACM接收为AT专用 ";

CM_ BO_ 431  " ";
CM_ SG_ 431 TCU_CRCCheck_1A8  "CRCCheck_SAE_J1850_2001,multinomial is X8+X4+X3+X2+1 ";
CM_ SG_ 431 TCU_GearShiftPosition  "TCU receives driver demands gear from ESL and make decisition of actual drive mode based on current vehicle/transmission status.
PCU receives this signals to understand actual drive mode and estimate target gear ";
CM_ SG_ 431 TCU_ShiftPostionValid  "APA配置接收方无BDC ";

CM_ BO_ 424  " ";
CM_ SG_ 424 TCU_CRCCheck_1A8  "ACM接收为AT专用 ";
CM_ SG_ 424 TCU_RollingCounter_1A8  "AT/DCT
ACM接收为AT专用
rollingcounter ";
CM_ SG_ 424 TCU_ActualGear  "AT/DCT ";
CM_ SG_ 424 TCU_ActualGearValid  "AT/DCT ";
CM_ SG_ 424 TCU_GearShiftPosition  "AT/DCT
ACM接收为AT专用 ";
CM_ SG_ 424 TCU_ShiftPostionValid  "AT/DCT
ACM接收为AT专用 ";

CM_ BO_ 796  " ";
CM_ SG_ 796 PCU_VcuRdySts  "APA配置接收方无BDC ";

CM_ BO_ 651  " ";

CM_ BO_ 664  " ";

CM_ BO_ 721  " ";

CM_ BO_ 734  " ";
CM_ SG_ 734 IP_DriverLCDALEDSts  "GW报文转发 ";
CM_ SG_ 734 IP_PassengerLCDALEDSts  "GW报文转发 ";

CM_ BO_ 80  " ";
CM_ SG_ 80 SRS_RollingCounter_id050  "ACM接收为AT专用 ";
CM_ SG_ 80 SRS_PassengerBuckleSwitchStatus  "For PDM is configured projects=
(if PDM is configured, logical detection with PDM is required)
0x0= [Buckled] or [Unbuckled and passenger not occupied]
0x1= [Unbuckle and passenger occupied]
0x2= Not Used
0x3= Not Used
 ";
CM_ SG_ 80 SRS_DriverBuckleSwitchStatus  " ";

CM_ BO_ 870  " ";

CM_ BO_ 1287  " ";
CM_ SG_ 1287 HU_AudioWarningEnable  " ";
CM_ SG_ 1287 HU_RCTBEnable  " ";
CM_ SG_ 1287 HU_RCTAEnable  "513(周期)和514(事件)，当前多数项目使用514(事件)报文。 ";
CM_ SG_ 1287 HU_SEAEnable  "513(周期)和514(事件)，当前多数项目使用514(事件)报文。 ";
CM_ SG_ 1287 HU_RCWEnable  "513(周期)和514(事件)，当前多数项目使用514(事件)报文。 ";

CM_ BO_ 1328  " ";
CM_ SG_ 1328 IP_TotalOdometer  "GW报文转发 ";

CM_ BO_ 903  " ";
CM_ SG_ 903 BCM_PowersaveModeStatus  " ";

CM_ BO_ 964  " ";

CM_ BO_ 579  " ";
CM_ SG_ 579 Transmitcnt6_F  " ";
CM_ SG_ 579 Transmitcnt5_F  " ";
CM_ SG_ 579 Transmitcnt4_F  " ";
CM_ SG_ 579 Transmitcnt3_F  " ";
CM_ SG_ 579 Transmitcnt2_F  " ";
CM_ SG_ 579 Transmitcnt1_F  " ";
CM_ SG_ 579 FLR_Track_ID_R  " ";
CM_ SG_ 579 FLR_Measured_R  " ";
CM_ SG_ 579 FLR_Location_R  " ";
CM_ SG_ 579 FLR_ClassComfrmFlg_R  " ";
CM_ SG_ 579 FLR_TrckrType_R  " ";
CM_ SG_ 579 FLR_TrckrAge_R  " ";
CM_ SG_ 579 FLR_MotionStatus_R  " ";
CM_ SG_ 579 FLR_AbsVy_R  " ";
CM_ SG_ 579 FLR_AbsoVx_R  " ";
CM_ SG_ 579 FLR_LocDx_R  " ";
CM_ SG_ 579 FLR_LocDy_R  " ";
CM_ SG_ 579 FLR_HeadingAngle_R  " ";
CM_ SG_ 579 FLR_Length_R  " ";
CM_ SG_ 579 FLR_Width_R  " ";
CM_ SG_ 579 FLR_Track_ID_L  " ";
CM_ SG_ 579 FLR_Measured_L  " ";
CM_ SG_ 579 FLR_Location_L  " ";
CM_ SG_ 579 FLR_ClassComfrmFlg_L  " ";
CM_ SG_ 579 FLR_TrckrType_L  " ";
CM_ SG_ 579 FLR_TrckrAge_L  " ";
CM_ SG_ 579 FLR_MotionStatus_L  " ";
CM_ SG_ 579 FLR_AbsVy_L  " ";
CM_ SG_ 579 FLR_AbsoVx_L  " ";
CM_ SG_ 579 FLR_LocDx_L  " ";
CM_ SG_ 579 FLR_LocDy_L  " ";
CM_ SG_ 579 FLR_HeadingAngle_L  " ";
CM_ SG_ 579 FLR_Length_L  " ";
CM_ SG_ 579 FLR_Width_L  " ";
CM_ SG_ 579 FLR_TrckrNum  " ";
CM_ SG_ 579 FLR_TrackerTimeStamp  " ";

CM_ BO_ 1875  "CANFD诊断仪使用 ";

CM_ BO_ 1884  "CANFD诊断仪使用 ";

CM_ BO_ 1876  "CANFD诊断仪使用 ";

CM_ BO_ 1883  "CANFD诊断仪使用 ";

CM_ BO_ 1104  "Diag--VDC--ADAS4--mADC
TX 100M-VDC-T1 100/1000MR--mADC ";

CM_ BO_ 1108  " ";

CM_ BO_ 1109  " ";

CM_ BO_ 1687  " ";
CM_ SG_ 1687 LCDAL_DTC2_Status  "DTC上传 ";
CM_ SG_ 1687 LCDAL_DTC2_LowByte  "DTC上传 ";
CM_ SG_ 1687 LCDAL_DTC2_MiddByte  "DTC上传 ";
CM_ SG_ 1687 LCDAL_DTC2_HighByte  "DTC上传 ";
CM_ SG_ 1687 LCDAL_DTC1_Status  "DTC上传 ";
CM_ SG_ 1687 LCDAL_DTC1_LowByte  "DTC上传 ";
CM_ SG_ 1687 LCDAL_DTC1_MiddByte  "DTC上传 ";
CM_ SG_ 1687 LCDAL_DTC1_HighByte  "DTC上传 ";

CM_ BO_ 1755  " ";
CM_ SG_ 1755 LCDAR_DTC2_Status  "DTC上传 ";
CM_ SG_ 1755 LCDAR_DTC2_LowByte  "DTC上传 ";
CM_ SG_ 1755 LCDAR_DTC2_MiddByte  "DTC上传 ";
CM_ SG_ 1755 LCDAR_DTC2_HighByte  "DTC上传 ";
CM_ SG_ 1755 LCDAR_DTC1_Status  "DTC上传 ";
CM_ SG_ 1755 LCDAR_DTC1_LowByte  "DTC上传 ";
CM_ SG_ 1755 LCDAR_DTC1_MiddByte  "DTC上传 ";
CM_ SG_ 1755 LCDAR_DTC1_HighByte  "DTC上传 ";

CM_ BO_ 1430  " ";
CM_ SG_ 1430 LCDAL_WakeUp_BYTE4BIT1  " ";
CM_ SG_ 1430 LCDAL_WakeUp_BYTE4BIT0  " ";
CM_ SG_ 1430 LCDAL_NotSleep_BYTE7BIT4  " ";
CM_ SG_ 1430 LCDAL_NotSleep_BYTE7BIT3  " ";
CM_ SG_ 1430 LCDAL_NotSleep_BYTE7BIT2  " ";
CM_ SG_ 1430 LCDAL_NotSleep_BYTE7BIT1  " ";
CM_ SG_ 1430 LCDAL_NotSleep_BYTE7BIT0  " ";

CM_ BO_ 1431  " ";
CM_ SG_ 1431 LCDAR_WakeUp_BYTE4BIT1  " ";
CM_ SG_ 1431 LCDAR_WakeUp_BYTE4BIT0  " ";
CM_ SG_ 1431 LCDAR_NotSleep_BYTE7BIT4  " ";
CM_ SG_ 1431 LCDAR_NotSleep_BYTE7BIT3  " ";
CM_ SG_ 1431 LCDAR_NotSleep_BYTE7BIT2  " ";
CM_ SG_ 1431 LCDAR_NotSleep_BYTE7BIT1  " ";
CM_ SG_ 1431 LCDAR_NotSleep_BYTE7BIT0  " ";

CM_ BO_ 698  " ";
CM_ SG_ 698 RLR_CRCCheck_2BA  " ";
CM_ SG_ 698 RLR_RollingCounter_2BA  " ";
CM_ SG_ 698 RLR_OBJ32_Ax  " ";
CM_ SG_ 698 RLR_OBJ31_Ax  " ";
CM_ SG_ 698 RLR_OBJ30_Ax  " ";
CM_ SG_ 698 RLR_OBJ29_Ax  " ";
CM_ SG_ 698 RLR_OBJ28_Ax  " ";
CM_ SG_ 698 RLR_OBJ27_Ax  " ";
CM_ SG_ 698 RLR_OBJ26_Ax  " ";
CM_ SG_ 698 RLR_OBJ25_Ax  " ";
CM_ SG_ 698 RLR_OBJ24_Ax  " ";
CM_ SG_ 698 RLR_OBJ23_Ax  " ";
CM_ SG_ 698 RLR_OBJ22_Ax  " ";
CM_ SG_ 698 RLR_OBJ21_Ax  " ";
CM_ SG_ 698 RLR_OBJ20_Ax  " ";
CM_ SG_ 698 RLR_OBJ19_Ax  " ";
CM_ SG_ 698 RLR_OBJ18_Ax  " ";
CM_ SG_ 698 RLR_OBJ17_Ax  " ";
CM_ SG_ 698 RLR_OBJ16_Ax  " ";
CM_ SG_ 698 RLR_OBJ15_Ax  " ";
CM_ SG_ 698 RLR_OBJ14_Ax  " ";
CM_ SG_ 698 RLR_OBJ13_Ax  " ";
CM_ SG_ 698 RLR_OBJ12_Ax  " ";
CM_ SG_ 698 RLR_OBJ11_Ax  " ";
CM_ SG_ 698 RLR_OBJ10_Ax  " ";
CM_ SG_ 698 RLR_OBJ9_Ax  " ";
CM_ SG_ 698 RLR_OBJ8_Ax  " ";
CM_ SG_ 698 RLR_OBJ7_Ax  " ";
CM_ SG_ 698 RLR_OBJ6_Ax  " ";
CM_ SG_ 698 RLR_OBJ5_Ax  " ";
CM_ SG_ 698 RLR_OBJ4_Ax  " ";
CM_ SG_ 698 RLR_OBJ3_Ax  " ";
CM_ SG_ 698 RLR_OBJ2_Ax  " ";
CM_ SG_ 698 RLR_OBJ1_Ax  " ";

CM_ BO_ 957  " ";

BA_DEF_ SG_  "GenSigStartValue" INT 0 0;
BA_DEF_ SG_  "GenSigInvalidValue" STRING  ;
BA_DEF_ SG_  "GenSigCycleTime" INT 0 0;
BA_DEF_ SG_  "GenSigSendType" ENUM  "Cyclic","OnWrite","OnWriteWithRepetition","OnChange","OnChangeWithRepetition","IfActive","IfActiveWithRepetition","NoSigSendType","NotUsed","NotUsed","NotUsed","NotUsed","NotUsed";
BA_DEF_ BO_  "GenMsgSendType" ENUM  "Cyclic","Event","Direct","NotUsed","NotUsed","Cyclic","NotUsed","IfActive","NoMsgSendType","NotUsed";
BA_DEF_ BO_  "GenMsgILSupport" ENUM  "No","Yes";
BA_DEF_ BO_  "GenMsgCycleTime" INT 0 65535;
BA_DEF_ BO_  "CANFD_BRS" ENUM  "0","1";
BA_DEF_ BO_  "VFrameFormat" ENUM  "StandardCAN","ExtendedCAN","reserved","reserved","reserved","reserved","reserved","reserved","reserved","reserved","reserved","reserved","reserved","reserved","StandardCAN_FD","ExtendedCAN_FD";
BA_DEF_DEF_  "GenSigStartValue" 0;
BA_DEF_DEF_  "GenSigInvalidValue" "/";
BA_DEF_DEF_  "GenSigCycleTime" 0;
BA_DEF_DEF_  "GenSigSendType" "Cyclic";
BA_DEF_DEF_  "GenMsgSendType" "NoMsgSendType";
BA_DEF_DEF_  "GenMsgILSupport" "Yes";
BA_DEF_DEF_  "GenMsgCycleTime" 0;
BA_DEF_DEF_  "CANFD_BRS" "1";
BA_DEF_DEF_  "VFrameFormat" "StandardCAN";
BA_ "GenMsgCycleTime" BO_ 924 50;
BA_ "GenMsgSendType" BO_ 924 0;
BA_ "VFrameFormat" BO_ 924 14;
BA_ "GenMsgCycleTime" BO_ 925 50;
BA_ "GenMsgSendType" BO_ 925 0;
BA_ "VFrameFormat" BO_ 925 14;
BA_ "GenMsgCycleTime" BO_ 926 50;
BA_ "GenMsgSendType" BO_ 926 0;
BA_ "VFrameFormat" BO_ 926 14;
BA_ "GenMsgCycleTime" BO_ 927 50;
BA_ "GenMsgSendType" BO_ 927 0;
BA_ "VFrameFormat" BO_ 927 14;
BA_ "GenMsgCycleTime" BO_ 693 50;
BA_ "GenMsgSendType" BO_ 693 0;
BA_ "VFrameFormat" BO_ 693 14;
BA_ "GenMsgCycleTime" BO_ 338 10;
BA_ "GenMsgSendType" BO_ 338 0;
BA_ "VFrameFormat" BO_ 338 14;
BA_ "GenMsgSendType" BO_ 936 1;
BA_ "VFrameFormat" BO_ 936 14;
BA_ "GenMsgCycleTime" BO_ 384 10;
BA_ "GenMsgSendType" BO_ 384 0;
BA_ "VFrameFormat" BO_ 384 14;
BA_ "GenMsgCycleTime" BO_ 800 100;
BA_ "GenMsgSendType" BO_ 800 0;
BA_ "VFrameFormat" BO_ 800 14;
BA_ "GenMsgCycleTime" BO_ 1302 1000;
BA_ "GenMsgSendType" BO_ 1302 0;
BA_ "VFrameFormat" BO_ 1302 14;
BA_ "GenMsgCycleTime" BO_ 349 20;
BA_ "GenMsgSendType" BO_ 349 0;
BA_ "VFrameFormat" BO_ 349 14;
BA_ "GenMsgCycleTime" BO_ 632 20;
BA_ "GenMsgSendType" BO_ 632 0;
BA_ "VFrameFormat" BO_ 632 14;
BA_ "GenMsgCycleTime" BO_ 378 10;
BA_ "GenMsgSendType" BO_ 378 0;
BA_ "VFrameFormat" BO_ 378 14;
BA_ "GenMsgCycleTime" BO_ 523 20;
BA_ "GenMsgSendType" BO_ 523 0;
BA_ "VFrameFormat" BO_ 523 14;
BA_ "GenMsgCycleTime" BO_ 271 20;
BA_ "GenMsgSendType" BO_ 271 0;
BA_ "VFrameFormat" BO_ 271 14;
BA_ "GenMsgCycleTime" BO_ 381 10;
BA_ "GenMsgSendType" BO_ 381 0;
BA_ "VFrameFormat" BO_ 381 14;
BA_ "GenMsgCycleTime" BO_ 398 10;
BA_ "GenMsgSendType" BO_ 398 0;
BA_ "VFrameFormat" BO_ 398 14;
BA_ "GenMsgCycleTime" BO_ 431 10;
BA_ "GenMsgSendType" BO_ 431 0;
BA_ "VFrameFormat" BO_ 431 14;
BA_ "GenMsgCycleTime" BO_ 424 10;
BA_ "GenMsgSendType" BO_ 424 0;
BA_ "VFrameFormat" BO_ 424 14;
BA_ "GenMsgCycleTime" BO_ 796 100;
BA_ "GenMsgSendType" BO_ 796 0;
BA_ "VFrameFormat" BO_ 796 14;
BA_ "GenMsgCycleTime" BO_ 651 40;
BA_ "GenMsgSendType" BO_ 651 0;
BA_ "VFrameFormat" BO_ 651 14;
BA_ "GenMsgCycleTime" BO_ 664 40;
BA_ "GenMsgSendType" BO_ 664 0;
BA_ "VFrameFormat" BO_ 664 14;
BA_ "GenMsgCycleTime" BO_ 721 40;
BA_ "GenMsgSendType" BO_ 721 0;
BA_ "VFrameFormat" BO_ 721 14;
BA_ "GenMsgCycleTime" BO_ 734 50;
BA_ "GenMsgSendType" BO_ 734 0;
BA_ "VFrameFormat" BO_ 734 14;
BA_ "GenMsgCycleTime" BO_ 80 500;
BA_ "GenMsgSendType" BO_ 80 0;
BA_ "VFrameFormat" BO_ 80 14;
BA_ "GenMsgCycleTime" BO_ 870 100;
BA_ "GenMsgSendType" BO_ 870 0;
BA_ "VFrameFormat" BO_ 870 14;
BA_ "GenMsgSendType" BO_ 1287 1;
BA_ "VFrameFormat" BO_ 1287 14;
BA_ "GenMsgCycleTime" BO_ 1328 500;
BA_ "GenMsgSendType" BO_ 1328 0;
BA_ "VFrameFormat" BO_ 1328 14;
BA_ "GenMsgCycleTime" BO_ 903 100;
BA_ "GenMsgSendType" BO_ 903 0;
BA_ "VFrameFormat" BO_ 903 14;
BA_ "GenMsgCycleTime" BO_ 964 100;
BA_ "GenMsgSendType" BO_ 964 0;
BA_ "VFrameFormat" BO_ 964 14;
BA_ "GenMsgCycleTime" BO_ 579 50;
BA_ "GenMsgSendType" BO_ 579 0;
BA_ "VFrameFormat" BO_ 579 14;
BA_ "GenMsgSendType" BO_ 1875 1;
BA_ "VFrameFormat" BO_ 1875 14;
BA_ "GenMsgSendType" BO_ 1884 1;
BA_ "VFrameFormat" BO_ 1884 14;
BA_ "GenMsgSendType" BO_ 1876 1;
BA_ "VFrameFormat" BO_ 1876 14;
BA_ "GenMsgSendType" BO_ 1883 1;
BA_ "VFrameFormat" BO_ 1883 14;
BA_ "GenMsgSendType" BO_ 1104 1;
BA_ "GenMsgSendType" BO_ 1108 1;
BA_ "GenMsgSendType" BO_ 1109 1;
BA_ "GenMsgCycleTime" BO_ 1687 500;
BA_ "GenMsgSendType" BO_ 1687 0;
BA_ "VFrameFormat" BO_ 1687 14;
BA_ "GenMsgCycleTime" BO_ 1755 500;
BA_ "GenMsgSendType" BO_ 1755 0;
BA_ "VFrameFormat" BO_ 1755 14;
BA_ "GenMsgCycleTime" BO_ 1430 1000;
BA_ "GenMsgSendType" BO_ 1430 0;
BA_ "VFrameFormat" BO_ 1430 14;
BA_ "GenMsgCycleTime" BO_ 1431 1000;
BA_ "GenMsgSendType" BO_ 1431 0;
BA_ "VFrameFormat" BO_ 1431 14;
BA_ "GenMsgCycleTime" BO_ 698 50;
BA_ "GenMsgSendType" BO_ 698 0;
BA_ "VFrameFormat" BO_ 698 14;
BA_ "GenMsgCycleTime" BO_ 957 100;
BA_ "GenMsgSendType" BO_ 957 0;
BA_ "VFrameFormat" BO_ 957 14;

BA_ "GenSigCycleTime" SG_ 924 RLR_CRCCheck_39C 50;
BA_ "GenSigCycleTime" SG_ 924 RLR_RollingCounter_39C 50;
BA_ "GenSigCycleTime" SG_ 924 RLR_FreespaceSectorKinestate102 50;
BA_ "GenSigCycleTime" SG_ 924 RLR_FreespaceSectorConRidence102 50;
BA_ "GenSigCycleTime" SG_ 924 RLR_FreespaceSectorDistance102 50;
BA_ "GenSigCycleTime" SG_ 924 RLR_FreespaceSectorKinestate101 50;
BA_ "GenSigCycleTime" SG_ 924 RLR_FreespaceSectorConRidence101 50;
BA_ "GenSigCycleTime" SG_ 924 RLR_FreespaceSectorDistance101 50;
BA_ "GenSigCycleTime" SG_ 924 RLR_FreespaceSectorKinestate100 50;
BA_ "GenSigCycleTime" SG_ 924 RLR_FreespaceSectorConRidence100 50;
BA_ "GenSigCycleTime" SG_ 924 RLR_FreespaceSectorDistance100 50;
BA_ "GenSigCycleTime" SG_ 924 RLR_FreespaceSectorKinestate99 50;
BA_ "GenSigCycleTime" SG_ 924 RLR_FreespaceSectorConRidence99 50;
BA_ "GenSigCycleTime" SG_ 924 RLR_FreespaceSectorDistance99 50;
BA_ "GenSigCycleTime" SG_ 924 RLR_FreespaceSectorKinestate98 50;
BA_ "GenSigCycleTime" SG_ 924 RLR_FreespaceSectorConRidence98 50;
BA_ "GenSigCycleTime" SG_ 924 RLR_FreespaceSectorDistance98 50;
BA_ "GenSigCycleTime" SG_ 924 RLR_FreespaceSectorKinestate97 50;
BA_ "GenSigCycleTime" SG_ 924 RLR_FreespaceSectorConRidence97 50;
BA_ "GenSigCycleTime" SG_ 924 RLR_FreespaceSectorDistance97 50;
BA_ "GenSigCycleTime" SG_ 924 RLR_FreespaceSectorKinestate96 50;
BA_ "GenSigCycleTime" SG_ 924 RLR_FreespaceSectorConRidence96 50;
BA_ "GenSigCycleTime" SG_ 924 RLR_FreespaceSectorDistance96 50;
BA_ "GenSigCycleTime" SG_ 924 RLR_FreespaceSectorKinestate95 50;
BA_ "GenSigCycleTime" SG_ 924 RLR_FreespaceSectorConRidence95 50;
BA_ "GenSigCycleTime" SG_ 924 RLR_FreespaceSectorDistance95 50;
BA_ "GenSigCycleTime" SG_ 924 RLR_FreespaceSectorKinestate94 50;
BA_ "GenSigCycleTime" SG_ 924 RLR_FreespaceSectorConRidence94 50;
BA_ "GenSigCycleTime" SG_ 924 RLR_FreespaceSectorDistance94 50;
BA_ "GenSigCycleTime" SG_ 924 RLR_FreespaceSectorKinestate93 50;
BA_ "GenSigCycleTime" SG_ 924 RLR_FreespaceSectorConRidence93 50;
BA_ "GenSigCycleTime" SG_ 924 RLR_FreespaceSectorDistance93 50;
BA_ "GenSigCycleTime" SG_ 924 RLR_FreespaceSectorKinestate92 50;
BA_ "GenSigCycleTime" SG_ 924 RLR_FreespaceSectorConRidence92 50;
BA_ "GenSigCycleTime" SG_ 924 RLR_FreespaceSectorDistance92 50;
BA_ "GenSigCycleTime" SG_ 924 RLR_FreespaceSectorKinestate91 50;
BA_ "GenSigCycleTime" SG_ 924 RLR_FreespaceSectorConRidence91 50;
BA_ "GenSigCycleTime" SG_ 924 RLR_FreespaceSectorDistance91 50;
BA_ "GenSigCycleTime" SG_ 924 RLR_FreespaceSectorKinestate90 50;
BA_ "GenSigCycleTime" SG_ 924 RLR_FreespaceSectorConRidence90 50;
BA_ "GenSigCycleTime" SG_ 924 RLR_FreespaceSectorDistance90 50;
BA_ "GenSigCycleTime" SG_ 924 RLR_FreespaceSectorKinestate89 50;
BA_ "GenSigCycleTime" SG_ 924 RLR_FreespaceSectorConRidence89 50;
BA_ "GenSigCycleTime" SG_ 924 RLR_FreespaceSectorDistance89 50;
BA_ "GenSigCycleTime" SG_ 924 RLR_FreespaceSectorKinestate88 50;
BA_ "GenSigCycleTime" SG_ 924 RLR_FreespaceSectorConRidence88 50;
BA_ "GenSigCycleTime" SG_ 924 RLR_FreespaceSectorDistance88 50;
BA_ "GenSigCycleTime" SG_ 924 RLR_FreespaceSectorKinestate87 50;
BA_ "GenSigCycleTime" SG_ 924 RLR_FreespaceSectorConRidence87 50;
BA_ "GenSigCycleTime" SG_ 924 RLR_FreespaceSectorDistance87 50;
BA_ "GenSigCycleTime" SG_ 924 RLR_FreespaceSectorKinestate86 50;
BA_ "GenSigCycleTime" SG_ 924 RLR_FreespaceSectorConRidence86 50;
BA_ "GenSigCycleTime" SG_ 924 RLR_FreespaceSectorDistance86 50;
BA_ "GenSigCycleTime" SG_ 924 RLR_FreespaceSectorKinestate85 50;
BA_ "GenSigCycleTime" SG_ 924 RLR_FreespaceSectorConRidence85 50;
BA_ "GenSigCycleTime" SG_ 924 RLR_FreespaceSectorDistance85 50;
BA_ "GenSigCycleTime" SG_ 924 RLR_FreespaceSectorKinestate84 50;
BA_ "GenSigCycleTime" SG_ 924 RLR_FreespaceSectorConRidence84 50;
BA_ "GenSigCycleTime" SG_ 924 RLR_FreespaceSectorDistance84 50;
BA_ "GenSigCycleTime" SG_ 924 RLR_FreespaceSectorKinestate83 50;
BA_ "GenSigCycleTime" SG_ 924 RLR_FreespaceSectorConRidence83 50;
BA_ "GenSigCycleTime" SG_ 924 RLR_FreespaceSectorDistance83 50;
BA_ "GenSigCycleTime" SG_ 924 RLR_FreespaceSectorKinestate82 50;
BA_ "GenSigCycleTime" SG_ 924 RLR_FreespaceSectorConRidence82 50;
BA_ "GenSigCycleTime" SG_ 924 RLR_FreespaceSectorDistance82 50;
BA_ "GenSigCycleTime" SG_ 924 RLR_FreespaceSectorKinestate81 50;
BA_ "GenSigCycleTime" SG_ 924 RLR_FreespaceSectorConRidence81 50;
BA_ "GenSigCycleTime" SG_ 924 RLR_FreespaceSectorDistance81 50;
BA_ "GenSigCycleTime" SG_ 924 RLR_FreespaceSectorKinestate80 50;
BA_ "GenSigCycleTime" SG_ 924 RLR_FreespaceSectorConRidence80 50;
BA_ "GenSigCycleTime" SG_ 924 RLR_FreespaceSectorDistance80 50;
BA_ "GenSigCycleTime" SG_ 924 RLR_FreespaceSectorKinestate79 50;
BA_ "GenSigCycleTime" SG_ 924 RLR_FreespaceSectorConRidence79 50;
BA_ "GenSigCycleTime" SG_ 924 RLR_FreespaceSectorDistance79 50;
BA_ "GenSigCycleTime" SG_ 924 RLR_FreespaceSectorKinestate78 50;
BA_ "GenSigCycleTime" SG_ 924 RLR_FreespaceSectorConRidence78 50;
BA_ "GenSigCycleTime" SG_ 924 RLR_FreespaceSectorDistance78 50;
BA_ "GenSigCycleTime" SG_ 924 RLR_FreespaceSectorKinestate77 50;
BA_ "GenSigCycleTime" SG_ 924 RLR_FreespaceSectorConRidence77 50;
BA_ "GenSigCycleTime" SG_ 924 RLR_FreespaceSectorDistance77 50;
BA_ "GenSigCycleTime" SG_ 924 RLR_FreespaceSectorKinestate76 50;
BA_ "GenSigCycleTime" SG_ 924 RLR_FreespaceSectorConRidence76 50;
BA_ "GenSigCycleTime" SG_ 924 RLR_FreespaceSectorDistance76 50;
BA_ "GenSigCycleTime" SG_ 924 RLR_FreespaceSectorKinestate75 50;
BA_ "GenSigCycleTime" SG_ 924 RLR_FreespaceSectorConRidence75 50;
BA_ "GenSigCycleTime" SG_ 924 RLR_FreespaceSectorDistance75 50;
BA_ "GenSigCycleTime" SG_ 924 RLR_FreespaceSectorKinestate74 50;
BA_ "GenSigCycleTime" SG_ 924 RLR_FreespaceSectorConRidence74 50;
BA_ "GenSigCycleTime" SG_ 924 RLR_FreespaceSectorDistance74 50;
BA_ "GenSigCycleTime" SG_ 924 RLR_FreespaceSectorKinestate73 50;
BA_ "GenSigCycleTime" SG_ 924 RLR_FreespaceSectorConRidence73 50;
BA_ "GenSigCycleTime" SG_ 924 RLR_FreespaceSectorDistance73 50;
BA_ "GenSigCycleTime" SG_ 924 RLR_FreespaceSectorKinestate72 50;
BA_ "GenSigCycleTime" SG_ 924 RLR_FreespaceSectorConRidence72 50;
BA_ "GenSigCycleTime" SG_ 924 RLR_FreespaceSectorDistance72 50;
BA_ "GenSigCycleTime" SG_ 924 RLR_FreespaceSectorKinestate71 50;
BA_ "GenSigCycleTime" SG_ 924 RLR_FreespaceSectorConRidence71 50;
BA_ "GenSigCycleTime" SG_ 924 RLR_FreespaceSectorDistance71 50;
BA_ "GenSigCycleTime" SG_ 924 RLR_FreespaceSectorKinestate70 50;
BA_ "GenSigCycleTime" SG_ 924 RLR_FreespaceSectorConRidence70 50;
BA_ "GenSigCycleTime" SG_ 924 RLR_FreespaceSectorDistance70 50;
BA_ "GenSigCycleTime" SG_ 924 RLR_FreespaceSectorKinestate69 50;
BA_ "GenSigCycleTime" SG_ 924 RLR_FreespaceSectorConRidence69 50;
BA_ "GenSigCycleTime" SG_ 924 RLR_FreespaceSectorDistance69 50;

BA_ "GenSigCycleTime" SG_ 925 RLR_CRCCheck_39D 50;
BA_ "GenSigCycleTime" SG_ 925 RLR_RollingCounter_39D 50;
BA_ "GenSigCycleTime" SG_ 925 RLR_FreespaceSectorKinestate136 50;
BA_ "GenSigCycleTime" SG_ 925 RLR_FreespaceSectorConRidence136 50;
BA_ "GenSigCycleTime" SG_ 925 RLR_FreespaceSectorDistance136 50;
BA_ "GenSigCycleTime" SG_ 925 RLR_FreespaceSectorKinestate135 50;
BA_ "GenSigCycleTime" SG_ 925 RLR_FreespaceSectorConRidence135 50;
BA_ "GenSigCycleTime" SG_ 925 RLR_FreespaceSectorDistance135 50;
BA_ "GenSigCycleTime" SG_ 925 RLR_FreespaceSectorKinestate134 50;
BA_ "GenSigCycleTime" SG_ 925 RLR_FreespaceSectorConRidence134 50;
BA_ "GenSigCycleTime" SG_ 925 RLR_FreespaceSectorDistance134 50;
BA_ "GenSigCycleTime" SG_ 925 RLR_FreespaceSectorKinestate133 50;
BA_ "GenSigCycleTime" SG_ 925 RLR_FreespaceSectorConRidence133 50;
BA_ "GenSigCycleTime" SG_ 925 RLR_FreespaceSectorDistance133 50;
BA_ "GenSigCycleTime" SG_ 925 RLR_FreespaceSectorKinestate132 50;
BA_ "GenSigCycleTime" SG_ 925 RLR_FreespaceSectorConRidence132 50;
BA_ "GenSigCycleTime" SG_ 925 RLR_FreespaceSectorDistance132 50;
BA_ "GenSigCycleTime" SG_ 925 RLR_FreespaceSectorKinestate131 50;
BA_ "GenSigCycleTime" SG_ 925 RLR_FreespaceSectorConRidence131 50;
BA_ "GenSigCycleTime" SG_ 925 RLR_FreespaceSectorDistance131 50;
BA_ "GenSigCycleTime" SG_ 925 RLR_FreespaceSectorKinestate130 50;
BA_ "GenSigCycleTime" SG_ 925 RLR_FreespaceSectorConRidence130 50;
BA_ "GenSigCycleTime" SG_ 925 RLR_FreespaceSectorDistance130 50;
BA_ "GenSigCycleTime" SG_ 925 RLR_FreespaceSectorKinestate129 50;
BA_ "GenSigCycleTime" SG_ 925 RLR_FreespaceSectorConRidence129 50;
BA_ "GenSigCycleTime" SG_ 925 RLR_FreespaceSectorDistance129 50;
BA_ "GenSigCycleTime" SG_ 925 RLR_FreespaceSectorKinestate128 50;
BA_ "GenSigCycleTime" SG_ 925 RLR_FreespaceSectorConRidence128 50;
BA_ "GenSigCycleTime" SG_ 925 RLR_FreespaceSectorDistance128 50;
BA_ "GenSigCycleTime" SG_ 925 RLR_FreespaceSectorKinestate127 50;
BA_ "GenSigCycleTime" SG_ 925 RLR_FreespaceSectorConRidence127 50;
BA_ "GenSigCycleTime" SG_ 925 RLR_FreespaceSectorDistance127 50;
BA_ "GenSigCycleTime" SG_ 925 RLR_FreespaceSectorKinestate126 50;
BA_ "GenSigCycleTime" SG_ 925 RLR_FreespaceSectorConRidence126 50;
BA_ "GenSigCycleTime" SG_ 925 RLR_FreespaceSectorDistance126 50;
BA_ "GenSigCycleTime" SG_ 925 RLR_FreespaceSectorKinestate125 50;
BA_ "GenSigCycleTime" SG_ 925 RLR_FreespaceSectorConRidence125 50;
BA_ "GenSigCycleTime" SG_ 925 RLR_FreespaceSectorDistance125 50;
BA_ "GenSigCycleTime" SG_ 925 RLR_FreespaceSectorKinestate124 50;
BA_ "GenSigCycleTime" SG_ 925 RLR_FreespaceSectorConRidence124 50;
BA_ "GenSigCycleTime" SG_ 925 RLR_FreespaceSectorDistance124 50;
BA_ "GenSigCycleTime" SG_ 925 RLR_FreespaceSectorKinestate123 50;
BA_ "GenSigCycleTime" SG_ 925 RLR_FreespaceSectorConRidence123 50;
BA_ "GenSigCycleTime" SG_ 925 RLR_FreespaceSectorDistance123 50;
BA_ "GenSigCycleTime" SG_ 925 RLR_FreespaceSectorKinestate122 50;
BA_ "GenSigCycleTime" SG_ 925 RLR_FreespaceSectorConRidence122 50;
BA_ "GenSigCycleTime" SG_ 925 RLR_FreespaceSectorDistance122 50;
BA_ "GenSigCycleTime" SG_ 925 RLR_FreespaceSectorKinestate121 50;
BA_ "GenSigCycleTime" SG_ 925 RLR_FreespaceSectorConRidence121 50;
BA_ "GenSigCycleTime" SG_ 925 RLR_FreespaceSectorDistance121 50;
BA_ "GenSigCycleTime" SG_ 925 RLR_FreespaceSectorKinestate120 50;
BA_ "GenSigCycleTime" SG_ 925 RLR_FreespaceSectorConRidence120 50;
BA_ "GenSigCycleTime" SG_ 925 RLR_FreespaceSectorDistance120 50;
BA_ "GenSigCycleTime" SG_ 925 RLR_FreespaceSectorKinestate119 50;
BA_ "GenSigCycleTime" SG_ 925 RLR_FreespaceSectorConRidence119 50;
BA_ "GenSigCycleTime" SG_ 925 RLR_FreespaceSectorDistance119 50;
BA_ "GenSigCycleTime" SG_ 925 RLR_FreespaceSectorKinestate118 50;
BA_ "GenSigCycleTime" SG_ 925 RLR_FreespaceSectorConRidence118 50;
BA_ "GenSigCycleTime" SG_ 925 RLR_FreespaceSectorDistance118 50;
BA_ "GenSigCycleTime" SG_ 925 RLR_FreespaceSectorKinestate117 50;
BA_ "GenSigCycleTime" SG_ 925 RLR_FreespaceSectorConRidence117 50;
BA_ "GenSigCycleTime" SG_ 925 RLR_FreespaceSectorDistance117 50;
BA_ "GenSigCycleTime" SG_ 925 RLR_FreespaceSectorKinestate116 50;
BA_ "GenSigCycleTime" SG_ 925 RLR_FreespaceSectorConRidence116 50;
BA_ "GenSigCycleTime" SG_ 925 RLR_FreespaceSectorDistance116 50;
BA_ "GenSigCycleTime" SG_ 925 RLR_FreespaceSectorKinestate115 50;
BA_ "GenSigCycleTime" SG_ 925 RLR_FreespaceSectorConRidence115 50;
BA_ "GenSigCycleTime" SG_ 925 RLR_FreespaceSectorDistance115 50;
BA_ "GenSigCycleTime" SG_ 925 RLR_FreespaceSectorKinestate114 50;
BA_ "GenSigCycleTime" SG_ 925 RLR_FreespaceSectorConRidence114 50;
BA_ "GenSigCycleTime" SG_ 925 RLR_FreespaceSectorDistance114 50;
BA_ "GenSigCycleTime" SG_ 925 RLR_FreespaceSectorKinestate113 50;
BA_ "GenSigCycleTime" SG_ 925 RLR_FreespaceSectorConRidence113 50;
BA_ "GenSigCycleTime" SG_ 925 RLR_FreespaceSectorDistance113 50;
BA_ "GenSigCycleTime" SG_ 925 RLR_FreespaceSectorKinestate112 50;
BA_ "GenSigCycleTime" SG_ 925 RLR_FreespaceSectorConRidence112 50;
BA_ "GenSigCycleTime" SG_ 925 RLR_FreespaceSectorDistance112 50;
BA_ "GenSigCycleTime" SG_ 925 RLR_FreespaceSectorKinestate111 50;
BA_ "GenSigCycleTime" SG_ 925 RLR_FreespaceSectorConRidence111 50;
BA_ "GenSigCycleTime" SG_ 925 RLR_FreespaceSectorDistance111 50;
BA_ "GenSigCycleTime" SG_ 925 RLR_FreespaceSectorKinestate110 50;
BA_ "GenSigCycleTime" SG_ 925 RLR_FreespaceSectorConRidence110 50;
BA_ "GenSigCycleTime" SG_ 925 RLR_FreespaceSectorDistance110 50;
BA_ "GenSigCycleTime" SG_ 925 RLR_FreespaceSectorKinestate109 50;
BA_ "GenSigCycleTime" SG_ 925 RLR_FreespaceSectorConRidence109 50;
BA_ "GenSigCycleTime" SG_ 925 RLR_FreespaceSectorDistance109 50;
BA_ "GenSigCycleTime" SG_ 925 RLR_FreespaceSectorKinestate108 50;
BA_ "GenSigCycleTime" SG_ 925 RLR_FreespaceSectorConRidence108 50;
BA_ "GenSigCycleTime" SG_ 925 RLR_FreespaceSectorDistance108 50;
BA_ "GenSigCycleTime" SG_ 925 RLR_FreespaceSectorKinestate107 50;
BA_ "GenSigCycleTime" SG_ 925 RLR_FreespaceSectorConRidence107 50;
BA_ "GenSigCycleTime" SG_ 925 RLR_FreespaceSectorDistance107 50;
BA_ "GenSigCycleTime" SG_ 925 RLR_FreespaceSectorKinestate106 50;
BA_ "GenSigCycleTime" SG_ 925 RLR_FreespaceSectorConRidence106 50;
BA_ "GenSigCycleTime" SG_ 925 RLR_FreespaceSectorDistance106 50;
BA_ "GenSigCycleTime" SG_ 925 RLR_FreespaceSectorKinestate105 50;
BA_ "GenSigCycleTime" SG_ 925 RLR_FreespaceSectorConRidence105 50;
BA_ "GenSigCycleTime" SG_ 925 RLR_FreespaceSectorDistance105 50;
BA_ "GenSigCycleTime" SG_ 925 RLR_FreespaceSectorKinestate104 50;
BA_ "GenSigCycleTime" SG_ 925 RLR_FreespaceSectorConRidence104 50;
BA_ "GenSigCycleTime" SG_ 925 RLR_FreespaceSectorDistance104 50;
BA_ "GenSigCycleTime" SG_ 925 RLR_FreespaceSectorKinestate103 50;
BA_ "GenSigCycleTime" SG_ 925 RLR_FreespaceSectorConRidence103 50;
BA_ "GenSigCycleTime" SG_ 925 RLR_FreespaceSectorDistance103 50;

BA_ "GenSigCycleTime" SG_ 926 RLR_CRCCheck_39E 50;
BA_ "GenSigCycleTime" SG_ 926 RLR_RollingCounter_39E 50;
BA_ "GenSigCycleTime" SG_ 926 RLR_FreespaceSectorKinestate170 50;
BA_ "GenSigCycleTime" SG_ 926 RLR_FreespaceSectorConRidence170 50;
BA_ "GenSigCycleTime" SG_ 926 RLR_FreespaceSectorDistance170 50;
BA_ "GenSigCycleTime" SG_ 926 RLR_FreespaceSectorKinestate169 50;
BA_ "GenSigCycleTime" SG_ 926 RLR_FreespaceSectorConRidence169 50;
BA_ "GenSigCycleTime" SG_ 926 RLR_FreespaceSectorDistance169 50;
BA_ "GenSigCycleTime" SG_ 926 RLR_FreespaceSectorKinestate168 50;
BA_ "GenSigCycleTime" SG_ 926 RLR_FreespaceSectorConRidence168 50;
BA_ "GenSigCycleTime" SG_ 926 RLR_FreespaceSectorDistance168 50;
BA_ "GenSigCycleTime" SG_ 926 RLR_FreespaceSectorKinestate167 50;
BA_ "GenSigCycleTime" SG_ 926 RLR_FreespaceSectorConRidence167 50;
BA_ "GenSigCycleTime" SG_ 926 RLR_FreespaceSectorDistance167 50;
BA_ "GenSigCycleTime" SG_ 926 RLR_FreespaceSectorKinestate166 50;
BA_ "GenSigCycleTime" SG_ 926 RLR_FreespaceSectorConRidence166 50;
BA_ "GenSigCycleTime" SG_ 926 RLR_FreespaceSectorDistance166 50;
BA_ "GenSigCycleTime" SG_ 926 RLR_FreespaceSectorKinestate165 50;
BA_ "GenSigCycleTime" SG_ 926 RLR_FreespaceSectorConRidence165 50;
BA_ "GenSigCycleTime" SG_ 926 RLR_FreespaceSectorDistance165 50;
BA_ "GenSigCycleTime" SG_ 926 RLR_FreespaceSectorKinestate164 50;
BA_ "GenSigCycleTime" SG_ 926 RLR_FreespaceSectorConRidence164 50;
BA_ "GenSigCycleTime" SG_ 926 RLR_FreespaceSectorDistance164 50;
BA_ "GenSigCycleTime" SG_ 926 RLR_FreespaceSectorKinestate163 50;
BA_ "GenSigCycleTime" SG_ 926 RLR_FreespaceSectorConRidence163 50;
BA_ "GenSigCycleTime" SG_ 926 RLR_FreespaceSectorDistance163 50;
BA_ "GenSigCycleTime" SG_ 926 RLR_FreespaceSectorKinestate162 50;
BA_ "GenSigCycleTime" SG_ 926 RLR_FreespaceSectorConRidence162 50;
BA_ "GenSigCycleTime" SG_ 926 RLR_FreespaceSectorDistance162 50;
BA_ "GenSigCycleTime" SG_ 926 RLR_FreespaceSectorKinestate161 50;
BA_ "GenSigCycleTime" SG_ 926 RLR_FreespaceSectorConRidence161 50;
BA_ "GenSigCycleTime" SG_ 926 RLR_FreespaceSectorDistance161 50;
BA_ "GenSigCycleTime" SG_ 926 RLR_FreespaceSectorKinestate160 50;
BA_ "GenSigCycleTime" SG_ 926 RLR_FreespaceSectorConRidence160 50;
BA_ "GenSigCycleTime" SG_ 926 RLR_FreespaceSectorDistance160 50;
BA_ "GenSigCycleTime" SG_ 926 RLR_FreespaceSectorKinestate159 50;
BA_ "GenSigCycleTime" SG_ 926 RLR_FreespaceSectorConRidence159 50;
BA_ "GenSigCycleTime" SG_ 926 RLR_FreespaceSectorDistance159 50;
BA_ "GenSigCycleTime" SG_ 926 RLR_FreespaceSectorKinestate158 50;
BA_ "GenSigCycleTime" SG_ 926 RLR_FreespaceSectorConRidence158 50;
BA_ "GenSigCycleTime" SG_ 926 RLR_FreespaceSectorDistance158 50;
BA_ "GenSigCycleTime" SG_ 926 RLR_FreespaceSectorKinestate157 50;
BA_ "GenSigCycleTime" SG_ 926 RLR_FreespaceSectorConRidence157 50;
BA_ "GenSigCycleTime" SG_ 926 RLR_FreespaceSectorDistance157 50;
BA_ "GenSigCycleTime" SG_ 926 RLR_FreespaceSectorKinestate156 50;
BA_ "GenSigCycleTime" SG_ 926 RLR_FreespaceSectorConRidence156 50;
BA_ "GenSigCycleTime" SG_ 926 RLR_FreespaceSectorDistance156 50;
BA_ "GenSigCycleTime" SG_ 926 RLR_FreespaceSectorKinestate155 50;
BA_ "GenSigCycleTime" SG_ 926 RLR_FreespaceSectorConRidence155 50;
BA_ "GenSigCycleTime" SG_ 926 RLR_FreespaceSectorDistance155 50;
BA_ "GenSigCycleTime" SG_ 926 RLR_FreespaceSectorKinestate154 50;
BA_ "GenSigCycleTime" SG_ 926 RLR_FreespaceSectorConRidence154 50;
BA_ "GenSigCycleTime" SG_ 926 RLR_FreespaceSectorDistance154 50;
BA_ "GenSigCycleTime" SG_ 926 RLR_FreespaceSectorKinestate153 50;
BA_ "GenSigCycleTime" SG_ 926 RLR_FreespaceSectorConRidence153 50;
BA_ "GenSigCycleTime" SG_ 926 RLR_FreespaceSectorDistance153 50;
BA_ "GenSigCycleTime" SG_ 926 RLR_FreespaceSectorKinestate152 50;
BA_ "GenSigCycleTime" SG_ 926 RLR_FreespaceSectorConRidence152 50;
BA_ "GenSigCycleTime" SG_ 926 RLR_FreespaceSectorDistance152 50;
BA_ "GenSigCycleTime" SG_ 926 RLR_FreespaceSectorKinestate151 50;
BA_ "GenSigCycleTime" SG_ 926 RLR_FreespaceSectorConRidence151 50;
BA_ "GenSigCycleTime" SG_ 926 RLR_FreespaceSectorDistance151 50;
BA_ "GenSigCycleTime" SG_ 926 RLR_FreespaceSectorKinestate150 50;
BA_ "GenSigCycleTime" SG_ 926 RLR_FreespaceSectorConRidence150 50;
BA_ "GenSigCycleTime" SG_ 926 RLR_FreespaceSectorDistance150 50;
BA_ "GenSigCycleTime" SG_ 926 RLR_FreespaceSectorKinestate149 50;
BA_ "GenSigCycleTime" SG_ 926 RLR_FreespaceSectorConRidence149 50;
BA_ "GenSigCycleTime" SG_ 926 RLR_FreespaceSectorDistance149 50;
BA_ "GenSigCycleTime" SG_ 926 RLR_FreespaceSectorKinestate148 50;
BA_ "GenSigCycleTime" SG_ 926 RLR_FreespaceSectorConRidence148 50;
BA_ "GenSigCycleTime" SG_ 926 RLR_FreespaceSectorDistance148 50;
BA_ "GenSigCycleTime" SG_ 926 RLR_FreespaceSectorKinestate147 50;
BA_ "GenSigCycleTime" SG_ 926 RLR_FreespaceSectorConRidence147 50;
BA_ "GenSigCycleTime" SG_ 926 RLR_FreespaceSectorDistance147 50;
BA_ "GenSigCycleTime" SG_ 926 RLR_FreespaceSectorKinestate146 50;
BA_ "GenSigCycleTime" SG_ 926 RLR_FreespaceSectorConRidence146 50;
BA_ "GenSigCycleTime" SG_ 926 RLR_FreespaceSectorDistance146 50;
BA_ "GenSigCycleTime" SG_ 926 RLR_FreespaceSectorKinestate145 50;
BA_ "GenSigCycleTime" SG_ 926 RLR_FreespaceSectorConRidence145 50;
BA_ "GenSigCycleTime" SG_ 926 RLR_FreespaceSectorDistance145 50;
BA_ "GenSigCycleTime" SG_ 926 RLR_FreespaceSectorKinestate144 50;
BA_ "GenSigCycleTime" SG_ 926 RLR_FreespaceSectorConRidence144 50;
BA_ "GenSigCycleTime" SG_ 926 RLR_FreespaceSectorDistance144 50;
BA_ "GenSigCycleTime" SG_ 926 RLR_FreespaceSectorKinestate143 50;
BA_ "GenSigCycleTime" SG_ 926 RLR_FreespaceSectorConRidence143 50;
BA_ "GenSigCycleTime" SG_ 926 RLR_FreespaceSectorDistance143 50;
BA_ "GenSigCycleTime" SG_ 926 RLR_FreespaceSectorKinestate142 50;
BA_ "GenSigCycleTime" SG_ 926 RLR_FreespaceSectorConRidence142 50;
BA_ "GenSigCycleTime" SG_ 926 RLR_FreespaceSectorDistance142 50;
BA_ "GenSigCycleTime" SG_ 926 RLR_FreespaceSectorKinestate141 50;
BA_ "GenSigCycleTime" SG_ 926 RLR_FreespaceSectorConRidence141 50;
BA_ "GenSigCycleTime" SG_ 926 RLR_FreespaceSectorDistance141 50;
BA_ "GenSigCycleTime" SG_ 926 RLR_FreespaceSectorKinestate140 50;
BA_ "GenSigCycleTime" SG_ 926 RLR_FreespaceSectorConRidence140 50;
BA_ "GenSigCycleTime" SG_ 926 RLR_FreespaceSectorDistance140 50;
BA_ "GenSigCycleTime" SG_ 926 RLR_FreespaceSectorKinestate139 50;
BA_ "GenSigCycleTime" SG_ 926 RLR_FreespaceSectorConRidence139 50;
BA_ "GenSigCycleTime" SG_ 926 RLR_FreespaceSectorDistance139 50;
BA_ "GenSigCycleTime" SG_ 926 RLR_FreespaceSectorKinestate138 50;
BA_ "GenSigCycleTime" SG_ 926 RLR_FreespaceSectorConRidence138 50;
BA_ "GenSigCycleTime" SG_ 926 RLR_FreespaceSectorDistance138 50;
BA_ "GenSigCycleTime" SG_ 926 RLR_FreespaceSectorKinestate137 50;
BA_ "GenSigCycleTime" SG_ 926 RLR_FreespaceSectorConRidence137 50;
BA_ "GenSigCycleTime" SG_ 926 RLR_FreespaceSectorDistance137 50;

BA_ "GenSigCycleTime" SG_ 927 RLR_CRCCheck_39F 50;
BA_ "GenSigCycleTime" SG_ 927 RLR_RollingCounter_39F 50;
BA_ "GenSigCycleTime" SG_ 927 RLR_FreespaceSectorKinestate180 50;
BA_ "GenSigCycleTime" SG_ 927 RLR_FreespaceSectorConRidence180 50;
BA_ "GenSigCycleTime" SG_ 927 RLR_FreespaceSectorDistance180 50;
BA_ "GenSigCycleTime" SG_ 927 RLR_FreespaceSectorKinestate179 50;
BA_ "GenSigCycleTime" SG_ 927 RLR_FreespaceSectorConRidence179 50;
BA_ "GenSigCycleTime" SG_ 927 RLR_FreespaceSectorDistance179 50;
BA_ "GenSigCycleTime" SG_ 927 RLR_FreespaceSectorKinestate178 50;
BA_ "GenSigCycleTime" SG_ 927 RLR_FreespaceSectorConRidence178 50;
BA_ "GenSigCycleTime" SG_ 927 RLR_FreespaceSectorDistance178 50;
BA_ "GenSigCycleTime" SG_ 927 RLR_FreespaceSectorKinestate177 50;
BA_ "GenSigCycleTime" SG_ 927 RLR_FreespaceSectorConRidence177 50;
BA_ "GenSigCycleTime" SG_ 927 RLR_FreespaceSectorDistance177 50;
BA_ "GenSigCycleTime" SG_ 927 RLR_FreespaceSectorKinestate176 50;
BA_ "GenSigCycleTime" SG_ 927 RLR_FreespaceSectorConRidence176 50;
BA_ "GenSigCycleTime" SG_ 927 RLR_FreespaceSectorDistance176 50;
BA_ "GenSigCycleTime" SG_ 927 RLR_FreespaceSectorKinestate175 50;
BA_ "GenSigCycleTime" SG_ 927 RLR_FreespaceSectorConRidence175 50;
BA_ "GenSigCycleTime" SG_ 927 RLR_FreespaceSectorDistance175 50;
BA_ "GenSigCycleTime" SG_ 927 RLR_FreespaceSectorKinestate174 50;
BA_ "GenSigCycleTime" SG_ 927 RLR_FreespaceSectorConRidence174 50;
BA_ "GenSigCycleTime" SG_ 927 RLR_FreespaceSectorDistance174 50;
BA_ "GenSigCycleTime" SG_ 927 RLR_FreespaceSectorKinestate173 50;
BA_ "GenSigCycleTime" SG_ 927 RLR_FreespaceSectorConRidence173 50;
BA_ "GenSigCycleTime" SG_ 927 RLR_FreespaceSectorDistance173 50;
BA_ "GenSigCycleTime" SG_ 927 RLR_FreespaceSectorKinestate172 50;
BA_ "GenSigCycleTime" SG_ 927 RLR_FreespaceSectorConRidence172 50;
BA_ "GenSigCycleTime" SG_ 927 RLR_FreespaceSectorDistance172 50;
BA_ "GenSigCycleTime" SG_ 927 RLR_FreespaceSectorKinestate171 50;
BA_ "GenSigCycleTime" SG_ 927 RLR_FreespaceSectorConRidence171 50;
BA_ "GenSigCycleTime" SG_ 927 RLR_FreespaceSectorDistance171 50;

BA_ "GenSigCycleTime" SG_ 693 RLR_CRCCheck_2B5 50;
BA_ "GenSigCycleTime" SG_ 693 RLR_RollingCounter_2B5 50;
BA_ "GenSigCycleTime" SG_ 693 LCDAR_ResetSts 50;
BA_ "GenSigInvalidValue" SG_ 693 LCDAR_ResetSts "7";
BA_ "GenSigCycleTime" SG_ 693 FuncDegradeType_RR 50;
BA_ "GenSigCycleTime" SG_ 693 FUSION_TimeoutCnt_RR 50;
BA_ "GenSigCycleTime" SG_ 693 VALIDATION_TimeoutCnt_RR 50;
BA_ "GenSigCycleTime" SG_ 693 CurFrameCycle_RR 50;
BA_ "GenSigCycleTime" SG_ 693 ProcessTimeoutCnt_RR 50;
BA_ "GenSigCycleTime" SG_ 693 RevFrameCnt_RR 50;
BA_ "GenSigCycleTime" SG_ 693 Local_Pointcloud_Number_RR 50;
BA_ "GenSigCycleTime" SG_ 693 RealTimeCal_PrcssBar_RR 50;
BA_ "GenSigCycleTime" SG_ 693 RealTimeCal_VelErrOutput_RR 50;
BA_ "GenSigCycleTime" SG_ 693 RealTimeCal_HoriMntErrOutput_RR 50;
BA_ "GenSigCycleTime" SG_ 693 RealTimeCal_FailReasonCode_RR 50;
BA_ "GenSigCycleTime" SG_ 693 RealTimeCal_Status_RR 50;
BA_ "GenSigCycleTime" SG_ 693 DiagCal_PrcssBar_RR 50;
BA_ "GenSigCycleTime" SG_ 693 DiagCal_VelErrOutput_RR 50;
BA_ "GenSigCycleTime" SG_ 693 DiagCal_HoriMntErrOutput_RR 50;
BA_ "GenSigCycleTime" SG_ 693 DiagCal_FailReasonCode_RR 50;
BA_ "GenSigCycleTime" SG_ 693 DiagCal_Status_RR 50;
BA_ "GenSigCycleTime" SG_ 693 EolCal_PrcssBar_RR 50;
BA_ "GenSigCycleTime" SG_ 693 EolCal_VelErrOutput_RR 50;
BA_ "GenSigCycleTime" SG_ 693 EolCal_HoriMntErrOutput_RR 50;
BA_ "GenSigCycleTime" SG_ 693 EolCal_FailReasonCode_RR 50;
BA_ "GenSigCycleTime" SG_ 693 EolCal_Status_RR 50;
BA_ "GenSigCycleTime" SG_ 693 PriCounter_RR 50;
BA_ "GenSigCycleTime" SG_ 693 MsgCounter_RR 50;

BA_ "GenSigCycleTime" SG_ 338 ADR_TriggerEventReq 10;
BA_ "GenSigCycleTime" SG_ 338 ADC_RollingCounter_152 10;
BA_ "GenSigCycleTime" SG_ 338 ADC_CRCCheck_152 10;
BA_ "GenSigCycleTime" SG_ 338 ADC_SenceMode 10;
BA_ "GenSigInvalidValue" SG_ 338 ADC_SenceMode "0";

BA_ "GenSigSendType" SG_ 936 AD_SYNC_Sync_Time 1;
BA_ "GenSigSendType" SG_ 936 AD_SYNC_UserByte_OVS_SGW 1;
BA_ "GenSigSendType" SG_ 936 AD_SYNC_TimeDomain 1;
BA_ "GenSigSendType" SG_ 936 AD_SYNC_Sequence 1;
BA_ "GenSigSendType" SG_ 936 AD_SYNC_CRC 1;
BA_ "GenSigSendType" SG_ 936 AD_SYNC_Type 1;

BA_ "GenSigCycleTime" SG_ 384 SAS_CRCCheck 10;
BA_ "GenSigCycleTime" SG_ 384 SAS_RollingCounter 10;
BA_ "GenSigCycleTime" SG_ 384 SAS_SteeringAngleValid 10;
BA_ "GenSigInvalidValue" SG_ 384 SAS_SteeringAngleValid "1";
BA_ "GenSigCycleTime" SG_ 384 SAS_SteeringAngleSpeed 10;
BA_ "GenSigInvalidValue" SG_ 384 SAS_SteeringAngleSpeed "255";
BA_ "GenSigCycleTime" SG_ 384 SAS_SteeringAngle 10;
BA_ "GenSigInvalidValue" SG_ 384 SAS_SteeringAngle "32767";
BA_ "GenSigCycleTime" SG_ 384 SAS_SASFailure 10;
BA_ "GenSigInvalidValue" SG_ 384 SAS_SASFailure "1";
BA_ "GenSigCycleTime" SG_ 384 SAS_Calibrated 10;

BA_ "GenSigCycleTime" SG_ 800 GW_ResetReq 100;
BA_ "GenSigInvalidValue" SG_ 800 GW_ResetReq "127";
BA_ "GenSigCycleTime" SG_ 800 GW_OTAmode_Chks 100;
BA_ "GenSigInvalidValue" SG_ 800 GW_OTAmode_Chks "0";
BA_ "GenSigCycleTime" SG_ 800 GW_OTAmode_Cntr 100;
BA_ "GenSigInvalidValue" SG_ 800 GW_OTAmode_Cntr "0";
BA_ "GenSigCycleTime" SG_ 800 GW_OTAmode 100;
BA_ "GenSigInvalidValue" SG_ 800 GW_OTAmode "0";

BA_ "GenSigCycleTime" SG_ 1302 HU_LocalTimeValid 1000;
BA_ "GenSigInvalidValue" SG_ 1302 HU_LocalTimeValid "1";
BA_ "GenSigCycleTime" SG_ 1302 HU_LocalTimeSecond 1000;
BA_ "GenSigInvalidValue" SG_ 1302 HU_LocalTimeSecond "0";
BA_ "GenSigCycleTime" SG_ 1302 HU_LocalTimeMinute 1000;
BA_ "GenSigInvalidValue" SG_ 1302 HU_LocalTimeMinute "0";
BA_ "GenSigCycleTime" SG_ 1302 HU_LocalTimeHour 1000;
BA_ "GenSigInvalidValue" SG_ 1302 HU_LocalTimeHour "0";
BA_ "GenSigCycleTime" SG_ 1302 HU_LocalTimeDate 1000;
BA_ "GenSigStartValue" SG_ 1302 HU_LocalTimeDate 1.000000;
BA_ "GenSigInvalidValue" SG_ 1302 HU_LocalTimeDate "1";
BA_ "GenSigCycleTime" SG_ 1302 HU_LocalTimeMonth 1000;
BA_ "GenSigStartValue" SG_ 1302 HU_LocalTimeMonth 1.000000;
BA_ "GenSigInvalidValue" SG_ 1302 HU_LocalTimeMonth "1";
BA_ "GenSigCycleTime" SG_ 1302 HU_LocalTimeYear 1000;
BA_ "GenSigInvalidValue" SG_ 1302 HU_LocalTimeYear "0";
BA_ "GenSigCycleTime" SG_ 1302 HU_CurrentLocationLatitude 1000;
BA_ "GenSigInvalidValue" SG_ 1302 HU_CurrentLocationLatitude "268435455";
BA_ "GenSigCycleTime" SG_ 1302 HU_CurrentLocationLongitude 1000;
BA_ "GenSigInvalidValue" SG_ 1302 HU_CurrentLocationLongitude "536870911";
BA_ "GenSigCycleTime" SG_ 1302 HU_CurrentLocationValid 1000;
BA_ "GenSigInvalidValue" SG_ 1302 HU_CurrentLocationValid "1";

BA_ "GenSigCycleTime" SG_ 349 ESP_CRCCheck_278 20;
BA_ "GenSigCycleTime" SG_ 349 ESP_RollingCounter_278 20;
BA_ "GenSigCycleTime" SG_ 349 ESP_Calibrated 20;
BA_ "GenSigCycleTime" SG_ 349 ESP_YawRateValid 20;
BA_ "GenSigCycleTime" SG_ 349 ESP_YawRate 20;
BA_ "GenSigInvalidValue" SG_ 349 ESP_YawRate "16383";
BA_ "GenSigCycleTime" SG_ 349 ESP_LongAccelValid 20;
BA_ "GenSigCycleTime" SG_ 349 ESP_LongAccel 20;
BA_ "GenSigInvalidValue" SG_ 349 ESP_LongAccel "1023";
BA_ "GenSigCycleTime" SG_ 349 ESP_LatAccelValid 20;
BA_ "GenSigCycleTime" SG_ 349 ESP_LatAccel 20;
BA_ "GenSigInvalidValue" SG_ 349 ESP_LatAccel "255";

BA_ "GenSigCycleTime" SG_ 632 ESP_YawRateValid 20;
BA_ "GenSigCycleTime" SG_ 632 ESP_YawRate 20;
BA_ "GenSigInvalidValue" SG_ 632 ESP_YawRate "16383";
BA_ "GenSigCycleTime" SG_ 632 ESP_RollingCounter_278 20;
BA_ "GenSigCycleTime" SG_ 632 ESP_LongAccel 20;
BA_ "GenSigInvalidValue" SG_ 632 ESP_LongAccel "1023";
BA_ "GenSigCycleTime" SG_ 632 ESP_LatAccel 20;
BA_ "GenSigInvalidValue" SG_ 632 ESP_LatAccel "255";
BA_ "GenSigCycleTime" SG_ 632 ESP_CRCCheck_278 20;

BA_ "GenSigCycleTime" SG_ 378 ESP_TCSFailStatus 10;
BA_ "GenSigCycleTime" SG_ 378 ESP_ESPFunctionStatus 10;
BA_ "GenSigStartValue" SG_ 378 ESP_ESPFunctionStatus 1.000000;
BA_ "GenSigCycleTime" SG_ 378 ESP_ESPActiveStatus 10;
BA_ "GenSigCycleTime" SG_ 378 ESP_ABSFailStatus 10;
BA_ "GenSigCycleTime" SG_ 378 ESP_ABSActiveStatus 10;
BA_ "GenSigCycleTime" SG_ 378 ESP_VehicleSpeedValid 10;
BA_ "GenSigInvalidValue" SG_ 378 ESP_VehicleSpeedValid "1";
BA_ "GenSigCycleTime" SG_ 378 ESP_VehicleSpeed 10;
BA_ "GenSigInvalidValue" SG_ 378 ESP_VehicleSpeed "8191";

BA_ "GenSigCycleTime" SG_ 523 ESP_RollingCounter_20B 20;
BA_ "GenSigCycleTime" SG_ 523 ESP_CRCCheck_20B 20;
BA_ "GenSigCycleTime" SG_ 523 ESP_PrefillAvailable 20;
BA_ "GenSigCycleTime" SG_ 523 ESP_PrefillActive 20;
BA_ "GenSigCycleTime" SG_ 523 ESP_BrakeOverHeatBrakeDiscTemp 20;
BA_ "GenSigCycleTime" SG_ 523 ESP_BrakeForce 20;
BA_ "GenSigCycleTime" SG_ 523 ESP_AEBdecActive 20;
BA_ "GenSigCycleTime" SG_ 523 ESP_AEBAvailable 20;
BA_ "GenSigCycleTime" SG_ 523 ESP_VDCActive 20;
BA_ "GenSigCycleTime" SG_ 523 ESP_TCSActive 20;
BA_ "GenSigCycleTime" SG_ 523 ESP_OnlyABSActive 20;
BA_ "GenSigCycleTime" SG_ 523 Wheel_Speed_RR_Valid_Data 20;
BA_ "GenSigInvalidValue" SG_ 523 Wheel_Speed_RR_Valid_Data "1";
BA_ "GenSigCycleTime" SG_ 523 Wheel_Speed_RR_Pulse 20;
BA_ "GenSigInvalidValue" SG_ 523 Wheel_Speed_RR_Pulse "255";
BA_ "GenSigCycleTime" SG_ 523 Wheel_Speed_RR_Direction 20;
BA_ "GenSigCycleTime" SG_ 523 Wheel_Speed_RR_Data 20;
BA_ "GenSigInvalidValue" SG_ 523 Wheel_Speed_RR_Data "8191";
BA_ "GenSigCycleTime" SG_ 523 Wheel_Speed_RL_Valid_Data 20;
BA_ "GenSigInvalidValue" SG_ 523 Wheel_Speed_RL_Valid_Data "1";
BA_ "GenSigCycleTime" SG_ 523 Wheel_Speed_RL_Pulse 20;
BA_ "GenSigInvalidValue" SG_ 523 Wheel_Speed_RL_Pulse "255";
BA_ "GenSigCycleTime" SG_ 523 Wheel_Speed_RL_Direction 20;
BA_ "GenSigInvalidValue" SG_ 523 Wheel_Speed_RL_Direction "3";
BA_ "GenSigCycleTime" SG_ 523 Wheel_Speed_RL_Data 20;
BA_ "GenSigInvalidValue" SG_ 523 Wheel_Speed_RL_Data "8191";
BA_ "GenSigCycleTime" SG_ 523 Wheel_Speed_FR_Valid_Data 20;
BA_ "GenSigInvalidValue" SG_ 523 Wheel_Speed_FR_Valid_Data "1";
BA_ "GenSigCycleTime" SG_ 523 Wheel_Speed_FR_Pulse 20;
BA_ "GenSigInvalidValue" SG_ 523 Wheel_Speed_FR_Pulse "255";
BA_ "GenSigCycleTime" SG_ 523 Wheel_Speed_FR_Direction 20;
BA_ "GenSigInvalidValue" SG_ 523 Wheel_Speed_FR_Direction "3";
BA_ "GenSigCycleTime" SG_ 523 Wheel_Speed_FR_Data 20;
BA_ "GenSigInvalidValue" SG_ 523 Wheel_Speed_FR_Data "8191";
BA_ "GenSigCycleTime" SG_ 523 Wheel_Speed_FL_Valid_Data 20;
BA_ "GenSigInvalidValue" SG_ 523 Wheel_Speed_FL_Valid_Data "1";
BA_ "GenSigCycleTime" SG_ 523 Wheel_Speed_FL_Pulse 20;
BA_ "GenSigInvalidValue" SG_ 523 Wheel_Speed_FL_Pulse "255";
BA_ "GenSigCycleTime" SG_ 523 Wheel_Speed_FL_Direction 20;
BA_ "GenSigInvalidValue" SG_ 523 Wheel_Speed_FL_Direction "3";
BA_ "GenSigCycleTime" SG_ 523 Wheel_Speed_FL_Data 20;
BA_ "GenSigInvalidValue" SG_ 523 Wheel_Speed_FL_Data "8191";
BA_ "GenSigCycleTime" SG_ 523 IBCU_BrkPedlStsGbVld 20;
BA_ "GenSigInvalidValue" SG_ 523 IBCU_BrkPedlStsGbVld "2";
BA_ "GenSigCycleTime" SG_ 523 IBCU_BrkPedoplStsGb 20;
BA_ "GenSigInvalidValue" SG_ 523 IBCU_BrkPedoplStsGb "255";
BA_ "GenSigCycleTime" SG_ 523 ESP_VehicleStandstillVld 20;
BA_ "GenSigInvalidValue" SG_ 523 ESP_VehicleStandstillVld "NA";
BA_ "GenSigCycleTime" SG_ 523 ESP_VehicleStandstill 20;

BA_ "GenSigCycleTime" SG_ 271 IBCU_sOutputRodAct_Q 20;
BA_ "GenSigCycleTime" SG_ 271 IBCU_sOutputRodAct 20;

BA_ "GenSigCycleTime" SG_ 381 PCU_RollingCounter_17D 10;
BA_ "GenSigCycleTime" SG_ 381 PCU_CRCCheck_17D 10;
BA_ "GenSigCycleTime" SG_ 381 PCU_RealAccPedlVld 10;
BA_ "GenSigCycleTime" SG_ 381 PCU_RealAccPedl 10;

BA_ "GenSigCycleTime" SG_ 398 EMS_BrakePedalStatus 10;
BA_ "GenSigInvalidValue" SG_ 398 EMS_BrakePedalStatus "3";
BA_ "GenSigCycleTime" SG_ 398 EMS_RollingCounter_18E 10;
BA_ "GenSigCycleTime" SG_ 398 EMS_CRCCheck_18E 10;
BA_ "GenSigCycleTime" SG_ 398 EMS_RealAccPedal 10;
BA_ "GenSigInvalidValue" SG_ 398 EMS_RealAccPedal "255";

BA_ "GenSigCycleTime" SG_ 431 TCU_CRCCheck_1A8 10;
BA_ "GenSigCycleTime" SG_ 431 TCU_RollingCounter_1A8 10;
BA_ "GenSigCycleTime" SG_ 431 TCU_GearShiftPosition 10;
BA_ "GenSigStartValue" SG_ 431 TCU_GearShiftPosition 13.000000;
BA_ "GenSigInvalidValue" SG_ 431 TCU_GearShiftPosition "15";
BA_ "GenSigCycleTime" SG_ 431 TCU_ShiftPostionValid 10;
BA_ "GenSigInvalidValue" SG_ 431 TCU_ShiftPostionValid "1";

BA_ "GenSigCycleTime" SG_ 424 TCU_CRCCheck_1A8 10;
BA_ "GenSigCycleTime" SG_ 424 TCU_RollingCounter_1A8 10;
BA_ "GenSigCycleTime" SG_ 424 TCU_ActualGear 10;
BA_ "GenSigInvalidValue" SG_ 424 TCU_ActualGear "15";
BA_ "GenSigCycleTime" SG_ 424 TCU_ActualGearValid 10;
BA_ "GenSigInvalidValue" SG_ 424 TCU_ActualGearValid "1";
BA_ "GenSigCycleTime" SG_ 424 TCU_GearShiftPosition 10;
BA_ "GenSigStartValue" SG_ 424 TCU_GearShiftPosition 14.000000;
BA_ "GenSigInvalidValue" SG_ 424 TCU_GearShiftPosition "15";
BA_ "GenSigCycleTime" SG_ 424 TCU_ShiftPostionValid 10;
BA_ "GenSigInvalidValue" SG_ 424 TCU_ShiftPostionValid "1";

BA_ "GenSigCycleTime" SG_ 796 PCU_VcuRdySts 100;
BA_ "GenSigInvalidValue" SG_ 796 PCU_VcuRdySts "NA";

BA_ "GenSigCycleTime" SG_ 651 BCM_CRCCheck_28B 40;
BA_ "GenSigCycleTime" SG_ 651 BCM_RollingCounter_28B 40;
BA_ "GenSigCycleTime" SG_ 651 BCM_LockTrigger 40;
BA_ "GenSigInvalidValue" SG_ 651 BCM_LockTrigger "0";
BA_ "GenSigCycleTime" SG_ 651 BCM_TurnIndicatorLeft 40;
BA_ "GenSigInvalidValue" SG_ 651 BCM_TurnIndicatorLeft "3";
BA_ "GenSigCycleTime" SG_ 651 BCM_TurnIndicatorRight 40;
BA_ "GenSigInvalidValue" SG_ 651 BCM_TurnIndicatorRight "3";
BA_ "GenSigCycleTime" SG_ 651 BCM_TurnLightSwitchSts 40;
BA_ "GenSigInvalidValue" SG_ 651 BCM_TurnLightSwitchSts "3";
BA_ "GenSigCycleTime" SG_ 651 BCM_emergencylightstatus 40;
BA_ "GenSigInvalidValue" SG_ 651 BCM_emergencylightstatus "3";
BA_ "GenSigCycleTime" SG_ 651 BCM_DriverDoorStatus 40;
BA_ "GenSigCycleTime" SG_ 651 BCM_PowerStatusFeedback 40;

BA_ "GenSigCycleTime" SG_ 664 BCM_CRCCheck_298 40;
BA_ "GenSigCycleTime" SG_ 664 BCM_RollingCounter_298 40;
BA_ "GenSigCycleTime" SG_ 664 PEPS_LockSignal 40;
BA_ "GenSigInvalidValue" SG_ 664 PEPS_LockSignal "0";
BA_ "GenSigCycleTime" SG_ 664 BCM_DriverDoorLockStatus 40;
BA_ "GenSigStartValue" SG_ 664 BCM_DriverDoorLockStatus 3.000000;
BA_ "GenSigCycleTime" SG_ 664 BCM_LeftRearDoorStatus 40;

BA_ "GenSigCycleTime" SG_ 721 BCM_RightRearDoorStatus 40;
BA_ "GenSigCycleTime" SG_ 721 BCM_PassengerDoorStatus 40;

BA_ "GenSigCycleTime" SG_ 734 IP_CRCCheck_2DE 50;
BA_ "GenSigCycleTime" SG_ 734 IP_RollingCounter_2DE 50;
BA_ "GenSigCycleTime" SG_ 734 IP_DriverLCDALEDSts 50;
BA_ "GenSigInvalidValue" SG_ 734 IP_DriverLCDALEDSts "0";
BA_ "GenSigCycleTime" SG_ 734 IP_PassengerLCDALEDSts 50;
BA_ "GenSigInvalidValue" SG_ 734 IP_PassengerLCDALEDSts "0";

BA_ "GenSigCycleTime" SG_ 80 SRS_CRCCheck_50 500;
BA_ "GenSigCycleTime" SG_ 80 SRS_RollingCounter_id050 500;
BA_ "GenSigCycleTime" SG_ 80 SRS_WarningLampStatus 500;
BA_ "GenSigCycleTime" SG_ 80 SRS_PassengerBuckleSwitchStatus 500;
BA_ "GenSigCycleTime" SG_ 80 SRS_DriverBuckleSwitchStatus 500;

BA_ "GenSigCycleTime" SG_ 870 AC_EnvironmentalTemp 100;
BA_ "GenSigStartValue" SG_ 870 AC_EnvironmentalTemp 255.000000;
BA_ "GenSigInvalidValue" SG_ 870 AC_EnvironmentalTemp "255";
BA_ "GenSigCycleTime" SG_ 870 AC_EnvironmentalTempVD 100;
BA_ "GenSigInvalidValue" SG_ 870 AC_EnvironmentalTempVD "1";

BA_ "GenSigSendType" SG_ 1287 HU_AudioWarningEnable 1;
BA_ "GenSigSendType" SG_ 1287 HU_RCTBEnable 1;
BA_ "GenSigSendType" SG_ 1287 HU_RCTAEnable 1;
BA_ "GenSigSendType" SG_ 1287 HU_BSDLCASetting 1;
BA_ "GenSigSendType" SG_ 1287 HU_SEAEnable 1;
BA_ "GenSigSendType" SG_ 1287 HU_RCWEnable 1;

BA_ "GenSigCycleTime" SG_ 1328 IP_TotalOdometer 500;
BA_ "GenSigInvalidValue" SG_ 1328 IP_TotalOdometer "16777215";

BA_ "GenSigCycleTime" SG_ 903 BCM_PowersaveModeStatus 100;
BA_ "GenSigInvalidValue" SG_ 903 BCM_PowersaveModeStatus "0";

BA_ "GenSigCycleTime" SG_ 964 HU_BSDLCAMode 100;

BA_ "GenSigCycleTime" SG_ 579 Transmitcnt6_F 50;
BA_ "GenSigCycleTime" SG_ 579 Transmitcnt5_F 50;
BA_ "GenSigCycleTime" SG_ 579 Transmitcnt4_F 50;
BA_ "GenSigCycleTime" SG_ 579 Transmitcnt3_F 50;
BA_ "GenSigCycleTime" SG_ 579 Transmitcnt2_F 50;
BA_ "GenSigCycleTime" SG_ 579 Transmitcnt1_F 50;
BA_ "GenSigCycleTime" SG_ 579 FLR_Track_ID_R 50;
BA_ "GenSigInvalidValue" SG_ 579 FLR_Track_ID_R "NA";
BA_ "GenSigCycleTime" SG_ 579 FLR_Measured_R 50;
BA_ "GenSigInvalidValue" SG_ 579 FLR_Measured_R "NA";
BA_ "GenSigCycleTime" SG_ 579 FLR_Location_R 50;
BA_ "GenSigInvalidValue" SG_ 579 FLR_Location_R "NA";
BA_ "GenSigCycleTime" SG_ 579 FLR_ClassComfrmFlg_R 50;
BA_ "GenSigInvalidValue" SG_ 579 FLR_ClassComfrmFlg_R "NA";
BA_ "GenSigCycleTime" SG_ 579 FLR_TrckrType_R 50;
BA_ "GenSigInvalidValue" SG_ 579 FLR_TrckrType_R "NA";
BA_ "GenSigCycleTime" SG_ 579 FLR_TrckrAge_R 50;
BA_ "GenSigInvalidValue" SG_ 579 FLR_TrckrAge_R "NA";
BA_ "GenSigCycleTime" SG_ 579 FLR_MotionStatus_R 50;
BA_ "GenSigInvalidValue" SG_ 579 FLR_MotionStatus_R "NA";
BA_ "GenSigCycleTime" SG_ 579 FLR_AbsVy_R 50;
BA_ "GenSigInvalidValue" SG_ 579 FLR_AbsVy_R "NA";
BA_ "GenSigCycleTime" SG_ 579 FLR_AbsoVx_R 50;
BA_ "GenSigInvalidValue" SG_ 579 FLR_AbsoVx_R "NA";
BA_ "GenSigCycleTime" SG_ 579 FLR_LocDx_R 50;
BA_ "GenSigInvalidValue" SG_ 579 FLR_LocDx_R "NA";
BA_ "GenSigCycleTime" SG_ 579 FLR_LocDy_R 50;
BA_ "GenSigInvalidValue" SG_ 579 FLR_LocDy_R "NA";
BA_ "GenSigCycleTime" SG_ 579 FLR_HeadingAngle_R 50;
BA_ "GenSigInvalidValue" SG_ 579 FLR_HeadingAngle_R "NA";
BA_ "GenSigCycleTime" SG_ 579 FLR_Length_R 50;
BA_ "GenSigInvalidValue" SG_ 579 FLR_Length_R "NA";
BA_ "GenSigCycleTime" SG_ 579 FLR_Width_R 50;
BA_ "GenSigInvalidValue" SG_ 579 FLR_Width_R "NA";
BA_ "GenSigCycleTime" SG_ 579 FLR_Track_ID_L 50;
BA_ "GenSigInvalidValue" SG_ 579 FLR_Track_ID_L "NA";
BA_ "GenSigCycleTime" SG_ 579 FLR_Measured_L 50;
BA_ "GenSigInvalidValue" SG_ 579 FLR_Measured_L "NA";
BA_ "GenSigCycleTime" SG_ 579 FLR_Location_L 50;
BA_ "GenSigInvalidValue" SG_ 579 FLR_Location_L "NA";
BA_ "GenSigCycleTime" SG_ 579 FLR_ClassComfrmFlg_L 50;
BA_ "GenSigInvalidValue" SG_ 579 FLR_ClassComfrmFlg_L "NA";
BA_ "GenSigCycleTime" SG_ 579 FLR_TrckrType_L 50;
BA_ "GenSigInvalidValue" SG_ 579 FLR_TrckrType_L "NA";
BA_ "GenSigCycleTime" SG_ 579 FLR_TrckrAge_L 50;
BA_ "GenSigInvalidValue" SG_ 579 FLR_TrckrAge_L "NA";
BA_ "GenSigCycleTime" SG_ 579 FLR_MotionStatus_L 50;
BA_ "GenSigInvalidValue" SG_ 579 FLR_MotionStatus_L "NA";
BA_ "GenSigCycleTime" SG_ 579 FLR_AbsVy_L 50;
BA_ "GenSigInvalidValue" SG_ 579 FLR_AbsVy_L "NA";
BA_ "GenSigCycleTime" SG_ 579 FLR_AbsoVx_L 50;
BA_ "GenSigInvalidValue" SG_ 579 FLR_AbsoVx_L "NA";
BA_ "GenSigCycleTime" SG_ 579 FLR_LocDx_L 50;
BA_ "GenSigInvalidValue" SG_ 579 FLR_LocDx_L "NA";
BA_ "GenSigCycleTime" SG_ 579 FLR_LocDy_L 50;
BA_ "GenSigInvalidValue" SG_ 579 FLR_LocDy_L "NA";
BA_ "GenSigCycleTime" SG_ 579 FLR_HeadingAngle_L 50;
BA_ "GenSigInvalidValue" SG_ 579 FLR_HeadingAngle_L "NA";
BA_ "GenSigCycleTime" SG_ 579 FLR_Length_L 50;
BA_ "GenSigInvalidValue" SG_ 579 FLR_Length_L "NA";
BA_ "GenSigCycleTime" SG_ 579 FLR_Width_L 50;
BA_ "GenSigInvalidValue" SG_ 579 FLR_Width_L "NA";
BA_ "GenSigCycleTime" SG_ 579 FLR_TrckrNum 50;
BA_ "GenSigInvalidValue" SG_ 579 FLR_TrckrNum "NA";
BA_ "GenSigCycleTime" SG_ 579 FLR_TrackerTimeStamp 50;
BA_ "GenSigInvalidValue" SG_ 579 FLR_TrackerTimeStamp "NA";

BA_ "GenSigCycleTime" SG_ 1687 LCDAL_DTC2_Status 500;
BA_ "GenSigCycleTime" SG_ 1687 LCDAL_DTC2_LowByte 500;
BA_ "GenSigCycleTime" SG_ 1687 LCDAL_DTC2_MiddByte 500;
BA_ "GenSigCycleTime" SG_ 1687 LCDAL_DTC2_HighByte 500;
BA_ "GenSigCycleTime" SG_ 1687 LCDAL_DTC1_Status 500;
BA_ "GenSigCycleTime" SG_ 1687 LCDAL_DTC1_LowByte 500;
BA_ "GenSigCycleTime" SG_ 1687 LCDAL_DTC1_MiddByte 500;
BA_ "GenSigCycleTime" SG_ 1687 LCDAL_DTC1_HighByte 500;

BA_ "GenSigCycleTime" SG_ 1755 LCDAR_DTC2_Status 500;
BA_ "GenSigCycleTime" SG_ 1755 LCDAR_DTC2_LowByte 500;
BA_ "GenSigCycleTime" SG_ 1755 LCDAR_DTC2_MiddByte 500;
BA_ "GenSigCycleTime" SG_ 1755 LCDAR_DTC2_HighByte 500;
BA_ "GenSigCycleTime" SG_ 1755 LCDAR_DTC1_Status 500;
BA_ "GenSigCycleTime" SG_ 1755 LCDAR_DTC1_LowByte 500;
BA_ "GenSigCycleTime" SG_ 1755 LCDAR_DTC1_MiddByte 500;
BA_ "GenSigCycleTime" SG_ 1755 LCDAR_DTC1_HighByte 500;

BA_ "GenSigCycleTime" SG_ 1430 LCDAL_WakeUp_BYTE4BIT1 1000;
BA_ "GenSigCycleTime" SG_ 1430 LCDAL_WakeUp_BYTE4BIT0 1000;
BA_ "GenSigCycleTime" SG_ 1430 LCDAL_NotSleep_BYTE7BIT4 1000;
BA_ "GenSigCycleTime" SG_ 1430 LCDAL_NotSleep_BYTE7BIT3 1000;
BA_ "GenSigCycleTime" SG_ 1430 LCDAL_NotSleep_BYTE7BIT2 1000;
BA_ "GenSigCycleTime" SG_ 1430 LCDAL_NotSleep_BYTE7BIT1 1000;
BA_ "GenSigCycleTime" SG_ 1430 LCDAL_NotSleep_BYTE7BIT0 1000;

BA_ "GenSigCycleTime" SG_ 1431 LCDAR_WakeUp_BYTE4BIT1 1000;
BA_ "GenSigCycleTime" SG_ 1431 LCDAR_WakeUp_BYTE4BIT0 1000;
BA_ "GenSigCycleTime" SG_ 1431 LCDAR_NotSleep_BYTE7BIT4 1000;
BA_ "GenSigCycleTime" SG_ 1431 LCDAR_NotSleep_BYTE7BIT3 1000;
BA_ "GenSigCycleTime" SG_ 1431 LCDAR_NotSleep_BYTE7BIT2 1000;
BA_ "GenSigCycleTime" SG_ 1431 LCDAR_NotSleep_BYTE7BIT1 1000;
BA_ "GenSigCycleTime" SG_ 1431 LCDAR_NotSleep_BYTE7BIT0 1000;

BA_ "GenSigCycleTime" SG_ 698 RLR_CRCCheck_2BA 50;
BA_ "GenSigCycleTime" SG_ 698 RLR_RollingCounter_2BA 50;
BA_ "GenSigCycleTime" SG_ 698 RLR_OBJ32_Ax 50;
BA_ "GenSigCycleTime" SG_ 698 RLR_OBJ31_Ax 50;
BA_ "GenSigCycleTime" SG_ 698 RLR_OBJ30_Ax 50;
BA_ "GenSigCycleTime" SG_ 698 RLR_OBJ29_Ax 50;
BA_ "GenSigCycleTime" SG_ 698 RLR_OBJ28_Ax 50;
BA_ "GenSigCycleTime" SG_ 698 RLR_OBJ27_Ax 50;
BA_ "GenSigCycleTime" SG_ 698 RLR_OBJ26_Ax 50;
BA_ "GenSigCycleTime" SG_ 698 RLR_OBJ25_Ax 50;
BA_ "GenSigCycleTime" SG_ 698 RLR_OBJ24_Ax 50;
BA_ "GenSigCycleTime" SG_ 698 RLR_OBJ23_Ax 50;
BA_ "GenSigCycleTime" SG_ 698 RLR_OBJ22_Ax 50;
BA_ "GenSigCycleTime" SG_ 698 RLR_OBJ21_Ax 50;
BA_ "GenSigCycleTime" SG_ 698 RLR_OBJ20_Ax 50;
BA_ "GenSigCycleTime" SG_ 698 RLR_OBJ19_Ax 50;
BA_ "GenSigCycleTime" SG_ 698 RLR_OBJ18_Ax 50;
BA_ "GenSigCycleTime" SG_ 698 RLR_OBJ17_Ax 50;
BA_ "GenSigCycleTime" SG_ 698 RLR_OBJ16_Ax 50;
BA_ "GenSigCycleTime" SG_ 698 RLR_OBJ15_Ax 50;
BA_ "GenSigCycleTime" SG_ 698 RLR_OBJ14_Ax 50;
BA_ "GenSigCycleTime" SG_ 698 RLR_OBJ13_Ax 50;
BA_ "GenSigCycleTime" SG_ 698 RLR_OBJ12_Ax 50;
BA_ "GenSigCycleTime" SG_ 698 RLR_OBJ11_Ax 50;
BA_ "GenSigCycleTime" SG_ 698 RLR_OBJ10_Ax 50;
BA_ "GenSigCycleTime" SG_ 698 RLR_OBJ9_Ax 50;
BA_ "GenSigCycleTime" SG_ 698 RLR_OBJ8_Ax 50;
BA_ "GenSigCycleTime" SG_ 698 RLR_OBJ7_Ax 50;
BA_ "GenSigCycleTime" SG_ 698 RLR_OBJ6_Ax 50;
BA_ "GenSigCycleTime" SG_ 698 RLR_OBJ5_Ax 50;
BA_ "GenSigCycleTime" SG_ 698 RLR_OBJ4_Ax 50;
BA_ "GenSigCycleTime" SG_ 698 RLR_OBJ3_Ax 50;
BA_ "GenSigCycleTime" SG_ 698 RLR_OBJ2_Ax 50;
BA_ "GenSigCycleTime" SG_ 698 RLR_OBJ1_Ax 50;

BA_ "GenSigCycleTime" SG_ 957 HU_AsistantSysteSwitch 100;
BA_ "GenSigInvalidValue" SG_ 957 HU_AsistantSysteSwitch "0";

VAL_ 693 LCDAR_ResetSts 0 "Valid" 1 "GW请求复位" 2 "自身判断复位" 3 "不满足复位条件" 4 "Reserve" 7 "Invalid";
VAL_ 693 RealTimeCal_Status_RR 0 "未开始
0x1=开始
0x2=成功
0x3=失败
0x4= 人工取消";
VAL_ 693 DiagCal_Status_RR 0 "未开始
0x1=开始
0x2=成功
0x3=失败
0x4= 人工取消";
VAL_ 693 EolCal_Status_RR 0 "未开始
0x1=开始
0x2=成功
0x3=失败
0x4= 人工取消";

VAL_ 338 ADR_TriggerEventReq 0 "";
VAL_ 338 ADC_SenceMode 0 "";

VAL_ 936 AD_SYNC_Sync_Time 32 "SYNC. SyncTimeSec = 32bit LSB of the 48 bits Seconds part of the time
Type0x28=FUP.SyncTimeNSec = 32 bit time stamp in nanoseconds";
VAL_ 936 AD_SYNC_UserByte_OVS_SGW 32 "SYNC.用户自定义数据，默认为0" 40 "FUP.";
VAL_ 936 AD_SYNC_Type 32 "SYNC" 40 "FUP";

VAL_ 384 SAS_SteeringAngleValid 0 "Valid" 1 "Invalid";
VAL_ 384 SAS_SASFailure 0 "No Failure" 1 "Failure";
VAL_ 384 SAS_Calibrated 0 "Calibrated" 1 " Not Calibrated";

VAL_ 800 GW_ResetReq 0 "Valid" 1 "THU" 2 " AMP" 3 "ADS/ADC" 4 " FC/LAS" 5 "FR/ACC" 6 "FLR" 7 "FRR" 8 "RLR/LCDAL" 9 "RRR/LCDAR" 10 "LVSM" 11 "INS" 12 "APA" 13 "BCML/BCM" 14 "GW/BCMR" 15 "EMS" 16 "PCU" 17 "BMS" 18 "PEU" 19 "OBC" 20 "TCU" 21 "IPUMP" 22 "ACM" 23 "ESL" 24 "PTS" 25 "ESCL" 26 "TMS/AC" 27 "DKC/RFBT/BLEM" 28 "WLCM" 29 "EPBI" 30 "IBCU" 31 "RBM" 32 "EPS" 33 "EPS2" 34 "DSM" 35 "IP" 36 "SLCM" 37 "HUD" 38 "GPEU" 39 "PDU" 40 "RPEU" 41 "VMC" 43 "DPEU" 44 "NFC-Enter" 45 "PATC" 46 "VMC2" 47 "RCCS" 48 "TRM" 49 "PDCU" 50 "BDCR" 51 "mADC" 52 "EPB" 53 "EVCC" 54 "HLM" 55 "CTMU" 56 "HRM" 57 "RLM" 64 "Reserve" 127 "Invalid";
VAL_ 800 GW_OTAmode 0 "OTAinactive" 1 "OTAmode1-车内升级安全执行中" 2 " OTAmode2-车外升级安全执行中" 3 "OTAmode3-Reserved" 4 "OTAmode4-车内升级非安全执行中" 5 "OTAmode5-车外升级非安全执行中" 6 "OTAmode6-车内升级条件检测中" 7 "OTAmode7-车外升级条件检测中" 7 "Reserved";

VAL_ 1302 HU_LocalTimeValid 0 "Valid" 1 "Not Valid";
VAL_ 1302 HU_CurrentLocationLatitude 134217727 "";
VAL_ 1302 HU_CurrentLocationLongitude 268435455 "";
VAL_ 1302 HU_CurrentLocationValid 0 "Valid" 1 "Not Valid";

VAL_ 349 ESP_Calibrated 0 "Calibrated" 1 " Not Calibrated";
VAL_ 349 ESP_YawRateValid 0 " Initializing" 1 " Valid" 2 " Invalid" 3 " Reserved";
VAL_ 349 ESP_LongAccelValid 0 "Initializing" 1 "Valid" 2 "Invalid" 3 "Reserved";
VAL_ 349 ESP_LatAccelValid 0 "Initializing" 1 "Valid" 2 "Invalid" 3 "Reserved";

VAL_ 632 ESP_YawRateValid 0 "Valid" 1 "Invalid";

VAL_ 378 ESP_TCSFailStatus 0 "Noerror" 1 "Error";
VAL_ 378 ESP_ESPFunctionStatus 0 "OFF" 1 "ON";
VAL_ 378 ESP_ESPActiveStatus 0 "NotActive" 1 "Active";
VAL_ 378 ESP_ABSFailStatus 0 "Noerror" 1 "Error";
VAL_ 378 ESP_ABSActiveStatus 0 "NotActive" 1 "Active";
VAL_ 378 ESP_VehicleSpeedValid 0 "Valid" 1 "NotValid";
VAL_ 378 ESP_VehicleSpeed 0 "0~360km/h" 6401 "Reserved" 8191 "Invalid";

VAL_ 523 ESP_PrefillAvailable 0 "notavailable" 1 "available";
VAL_ 523 ESP_PrefillActive 0 "notactive" 1 "active";
VAL_ 523 ESP_BrakeOverHeatBrakeDiscTemp 0 "nothigh" 1 "temptoohigh";
VAL_ 523 ESP_BrakeForce 0 "nobrakeforce" 1 "havebrakeforce";
VAL_ 523 ESP_AEBdecActive 0 "notactive" 1 "active";
VAL_ 523 ESP_AEBAvailable 0 "notavailable" 1 "available";
VAL_ 523 ESP_VDCActive 0 "NotActive" 1 "Active";
VAL_ 523 ESP_TCSActive 0 "NotActive" 1 "Active";
VAL_ 523 ESP_OnlyABSActive 0 "NotActive" 1 "Active";
VAL_ 523 Wheel_Speed_RR_Valid_Data 0 "Valid" 1 "NotValid";
VAL_ 523 Wheel_Speed_RR_Direction 0 "Forward" 1 "backward" 2 "Standstill" 3 "Invalid";
VAL_ 523 Wheel_Speed_RL_Valid_Data 0 "Valid" 1 "NotValid";
VAL_ 523 Wheel_Speed_RL_Direction 0 "Forward" 1 "backward" 2 "Standstill" 3 "Invalid";
VAL_ 523 Wheel_Speed_FR_Valid_Data 0 "Valid" 1 "NotValid";
VAL_ 523 Wheel_Speed_FR_Direction 0 "Forward" 1 "backward" 2 "Standstill" 3 "Invalid";
VAL_ 523 Wheel_Speed_FL_Valid_Data 0 "Valid" 1 "NotValid";
VAL_ 523 Wheel_Speed_FL_Direction 0 "Forward" 1 "backward" 2 "Standstill" 3 "Invalid";
VAL_ 523 IBCU_BrkPedlStsGbVld 0 "NotInitialized" 1 "Normal" 2 "Invalid";
VAL_ 523 IBCU_BrkPedoplStsGb 0 " 制动未踩下" 101 " 制动踩下" 254 "异常";
VAL_ 523 ESP_VehicleStandstillVld 0 "valid" 1 "Invalid";
VAL_ 523 ESP_VehicleStandstill 0 "notstandstill" 1 "standstill";

VAL_ 271 IBCU_sOutputRodAct_Q 0 "SoutputRodAct_NotInitialized" 1 "SoutputRodAct_Normal" 2 "SoutputRodAct_Faulty";

VAL_ 381 PCU_RealAccPedlVld 1 "invalid" 0 "valid";

VAL_ 398 EMS_BrakePedalStatus 0 "NotPressed" 1 "Pressed" 2 "Reserved" 3 "Error";

VAL_ 431 TCU_GearShiftPosition 0 "Parking" 1 "Reverse" 2 "Neutral" 3 "D" 4 "D3" 5 "D2" 6 "L" 7 "M/S" 8 "Reserved" 13 " Initial value" 14 " Unreliable" 15 " Invalid";
VAL_ 431 TCU_ShiftPostionValid 0 "valid" 1 "invalid";

VAL_ 424 TCU_ActualGear 0 "Neutral" 1 "1stgear" 2 "2ndgear" 3 "3rdgear" 4 "4tgear" 5 "5tgear" 6 "6tgear" 7 "7tgear" 8 "8tgear" 9 "Reverse" 10 "Parking" 11 "Reserved" 12 "Reserved" 13 "Reserved" 14 "Reserved" 15 "Invalid";
VAL_ 424 TCU_ActualGearValid 0 "Valid" 1 "Invalid";
VAL_ 424 TCU_GearShiftPosition 0 "Parking" 1 "Reverse" 2 "Neutral" 3 "D" 4 "D3" 5 "D2" 6 "L" 7 "M_or_S" 8 "Reserved" 9 "Reserved" 10 "Reserved" 11 "Reserved" 12 "Reserved" 13 "Reserved" 14 "Unreliable" 15 "Invalid";
VAL_ 424 TCU_ShiftPostionValid 0 "Valid" 1 "Invalid";

VAL_ 796 PCU_VcuRdySts 0 "no Ready" 1 "Ready";

VAL_ 651 BCM_LockTrigger 0 "none" 1 "RKE闭锁" 2 "PKE闭锁" 3 "中控闭锁" 4 "速度落锁" 5 "二次落锁" 6 "机械闭锁" 7 "远程闭锁" 8 "蓝牙闭锁" 9 "离车自动闭锁" 10 "HU闭锁" 11 "APA后闭锁" 12 "主动迎宾闭锁" 13 "开放功能闭锁" 14 "电动背门双击闭锁" 15 "NFC闭锁" 16 "UWB实体钥匙闭锁" 17 "远程音乐灯光秀闭锁" 18 "人脸闭锁" 19 "分级迎宾闭锁";
VAL_ 651 BCM_TurnIndicatorLeft 0 "OFF" 1 "ON" 2 "Not used" 3 "Error";
VAL_ 651 BCM_TurnIndicatorRight 0 "OFF" 1 "ON" 2 "Not used" 3 "Error";
VAL_ 651 BCM_TurnLightSwitchSts 0 "Not Actived" 1 "Left Actived" 2 "Right Actived" 3 "Invalid";
VAL_ 651 BCM_emergencylightstatus 0 "OFF" 1 "ON" 2 "Not used" 3 "Error（故障）";
VAL_ 651 BCM_DriverDoorStatus 0 "Close" 1 "Open";
VAL_ 651 BCM_PowerStatusFeedback 0 "OFF" 1 "ACC" 2 "ON" 3 "Start";

VAL_ 664 PEPS_LockSignal 0 " Inactive" 1 " 遥控闭锁" 2 " PE闭锁" 3 " 不可用";
VAL_ 664 BCM_DriverDoorLockStatus 0 "Lock" 1 "Unlock" 2 "Not used" 3 "Error";
VAL_ 664 BCM_LeftRearDoorStatus 0 "Close" 1 "Open";

VAL_ 721 BCM_RightRearDoorStatus 0 "Close" 1 "Open";
VAL_ 721 BCM_PassengerDoorStatus 0 "Close" 1 "Open";

VAL_ 734 IP_DriverLCDALEDSts 0 "No Error" 1 "Error";
VAL_ 734 IP_PassengerLCDALEDSts 0 "No Error" 1 "Error";

VAL_ 80 SRS_CRCCheck_50 0 "0xFF，XOR value=0xFF，input data reflected=No，Result data reflected=No，check=0x48，Magic check=0xC4）";
VAL_ 80 SRS_WarningLampStatus 0 "Lamp off" 1 "Lamp on" 2 "Lamp Flashing" 3 "Not Used";
VAL_ 80 SRS_PassengerBuckleSwitchStatus 0 "Buckled" 1 "Unbuckle " 2 "Not Used" 3 "Not Used
Default value= 0x0";
VAL_ 80 SRS_DriverBuckleSwitchStatus 0 "Buckled" 1 "Unbuckle " 2 "Not Used" 3 "Not Used
Default value= 0x0";

VAL_ 870 AC_EnvironmentalTemp 0 "-40~87℃" 255 "Invalid";
VAL_ 870 AC_EnvironmentalTempVD 0 "Valid" 1 "Invalid";

VAL_ 1287 HU_AudioWarningEnable 0 "inactive" 1 "Off" 2 "On" 3 " Reserved";
VAL_ 1287 HU_RCTBEnable 0 "Inactive" 1 "Off" 2 "On" 3 " Reserved";
VAL_ 1287 HU_RCTAEnable 0 "inactive" 1 "Off" 2 "On" 3 " Reserved";
VAL_ 1287 HU_BSDLCASetting 0 "early" 1 "normal" 2 "late" 3 "Off" 4 "reserved" 7 "Invalid";
VAL_ 1287 HU_SEAEnable 0 "inactive" 1 "Off" 2 "On" 3 " Reserved";
VAL_ 1287 HU_RCWEnable 0 "Inactive" 1 "Off" 2 "On" 3 " Reserved";

VAL_ 903 BCM_PowersaveModeStatus 0 "Inactive" 1 "ON" 2 " OFF" 3 "Reserved";

VAL_ 964 HU_BSDLCAMode 0 "inactive" 1 "Light" 2 "Light+Vibration" 3 "Light+Voice" 4 "OFF" 5 "Reserved" 6 "Reserved" 7 "Invalid";

VAL_ 579 FLR_Measured_R 0 "unknown" 1 "Measured" 2 "Predicted" 3 "Reserved";
VAL_ 579 FLR_Location_R 0 "unknown" 1 "Left Lane" 2 "Right  Lane" 3 "Ego Lane";
VAL_ 579 FLR_ClassComfrmFlg_R 0 "未确认" 1 "已确认;";
VAL_ 579 FLR_TrckrType_R 0 "Not Detected" 1 "car" 2 "truck" 3 "bicycle/motorbike" 4 "pedestrian" 5 "general" 6 "animal" 7 "uncertain";
VAL_ 579 FLR_MotionStatus_R 0 "unknown" 1 "moving " 2 "stopped" 3 "stationary" 4 "crossing" 5 "reserve;";
VAL_ 579 FLR_Measured_L 0 "unknown" 1 "Measured" 2 "Predicted" 3 "Reserved";
VAL_ 579 FLR_Location_L 0 "unknown" 1 "Left Lane" 2 "Right  Lane" 3 "Ego Lane";
VAL_ 579 FLR_ClassComfrmFlg_L 0 "未确认" 1 "已确认;";
VAL_ 579 FLR_TrckrType_L 0 "Not Detected" 1 "car" 2 "truck" 3 "bicycle/motorbike" 4 "pedestrian" 5 "general" 6 "animal" 7 "uncertain";
VAL_ 579 FLR_MotionStatus_L 0 "unknown" 1 "moving " 2 "stopped" 3 "stationary" 4 "crossing" 5 "reserve;";

VAL_ 1430 LCDAL_WakeUp_BYTE4BIT1 0 "Inactive" 1 " IG唤醒（若不接IG硬线则无此位）";
VAL_ 1430 LCDAL_WakeUp_BYTE4BIT0 0 "Inactive" 1 " CAN网络管理报文唤醒";
VAL_ 1430 LCDAL_NotSleep_BYTE7BIT4 0 "Inactive" 1 "SEW功能开启且电源模式切换为OFF刚好5分钟但SEW报警报文正在发送";
VAL_ 1430 LCDAL_NotSleep_BYTE7BIT3 0 "Inactive" 1 "SEW功能开启且电源模式切换为OFF不足5分钟";
VAL_ 1430 LCDAL_NotSleep_BYTE7BIT2 0 "Inactive" 1 "诊断服务在线";
VAL_ 1430 LCDAL_NotSleep_BYTE7BIT1 0 "Inactive" 1 " IGN硬线信号为ON档/总线电源挡位信号非OFF";
VAL_ 1430 LCDAL_NotSleep_BYTE7BIT0 0 "Inactive" 1 " CAN网络上其他节点不允许休眠";

VAL_ 1431 LCDAR_WakeUp_BYTE4BIT1 0 "Inactive" 1 " IG唤醒（若不接IG硬线则无此位）";
VAL_ 1431 LCDAR_WakeUp_BYTE4BIT0 0 "Inactive" 1 " CAN网络管理报文唤醒";
VAL_ 1431 LCDAR_NotSleep_BYTE7BIT4 0 "Inactive" 1 "SEW功能开启且电源模式切换为OFF刚好5分钟但SEW报警报文正在发送";
VAL_ 1431 LCDAR_NotSleep_BYTE7BIT3 0 "Inactive" 1 "SEW功能开启且电源模式切换为OFF不足5分钟";
VAL_ 1431 LCDAR_NotSleep_BYTE7BIT2 0 "Inactive" 1 "诊断服务在线";
VAL_ 1431 LCDAR_NotSleep_BYTE7BIT1 0 "Inactive" 1 " IGN硬线信号为ON档/总线电源挡位信号非OFF";
VAL_ 1431 LCDAR_NotSleep_BYTE7BIT0 0 "Inactive" 1 " CAN网络上其他节点不允许休眠";

VAL_ 957 HU_AsistantSysteSwitch 0 " inactive " 1 "关闭" 2 "开启";
